VERSION "created by canmatrix"

NS_ :

BS_:

BU_: RadarFrontCenter DASy MPC3

BO_ 206 VFC_Object15A: 64 MPC3
 SG_ VFC_Obj15A_CRC : 0|16@1+ (1,0) [0|65535] ""  RadarFrontCenter,DASy
 SG_ VFC_Obj15A_AliveCtr : 16|8@1+ (1,0) [0|255] ""  RadarFrontCenter,DASy
 SG_ VFC_Obj15A_BlockCtr : 24|4@1+ (1,0) [0|15] ""  RadarFrontCenter,DASy
 SG_ VFC_Obj15A_ProtOrderIndex : 32|6@1+ (1,0) [0|63] ""  RadarFrontCenter,DASy
 SG_ VFC_Obj15A_Ax : 39|9@1+ (0.1,-16) [-16|16] "m/s^2"  RadarFrontCenter,DASy
 SG_ VFC_Obj15A_Vx : 48|12@1+ (0.1,-154) [-154|50] "m/s"  RadarFrontCenter,DASy
 SG_ VFC_Obj15A_Dx : 60|12@1+ (0.05,0) [0|204.7] "m"  RadarFrontCenter,DASy
 SG_ VFC_Obj15A_Dy : 72|14@1+ (0.01,-80) [-80|80] "m"  RadarFrontCenter,DASy
 SG_ VFC_Obj15A_Vy : 86|10@1+ (0.1,-50) [-50|50] "m/s"  RadarFrontCenter,DASy
 SG_ VFC_Obj15A_Ay : 96|8@1+ (0.1,-12) [-12|12] "m/s^2"  RadarFrontCenter,DASy
 SG_ VFC_Obj15A_DyStdDev : 104|10@1+ (0.02,0) [0|20] "m"  RadarFrontCenter,DASy
 SG_ VFC_Obj15A_DxStdDev : 118|10@1+ (0.05,0) [0|50] "m"  RadarFrontCenter,DASy
 SG_ VFC_Obj15A_VxStdDev : 128|10@1+ (0.1,0) [0|100] "m/s"  RadarFrontCenter,DASy
 SG_ VFC_Obj15A_ExistProb : 138|6@1+ (2,0) [0|100] "%"  RadarFrontCenter,DASy
 SG_ VFC_Obj15A_VyStdDev : 144|9@1+ (0.1,0) [0|50] "m/s"  RadarFrontCenter,DASy
 SG_ VFC_Obj15A_TypeProb : 154|6@1+ (2,0) [0|100] "%"  RadarFrontCenter,DASy
 SG_ VFC_Obj15A_AxStdDev : 160|8@1+ (0.1,0) [0|25] "m/s^2"  RadarFrontCenter,DASy
 SG_ VFC_Obj15A_AyStdDev : 168|8@1+ (0.1,0) [0|25] "m/s^2"  RadarFrontCenter,DASy
 SG_ VFC_Obj15A_PhiLeft : 176|13@1+ (0.00025,-1) [-1|1] ""  RadarFrontCenter,DASy
 SG_ VFC_Obj15A_ClassifiedView : 189|3@1+ (1,0) [0|7] ""  RadarFrontCenter,DASy
 SG_ VFC_Obj15A_Length : 192|9@1+ (0.05,0) [0|25.5] "m"  RadarFrontCenter,DASy
 SG_ VFC_Obj15A_WidthStdDev : 201|7@1+ (0.01,0) [0|1] "m"  RadarFrontCenter,DASy
 SG_ VFC_Obj15A_Height : 208|9@1+ (0.01,0) [0|5.11] "m"  RadarFrontCenter,DASy
 SG_ VFC_Obj15A_HeightStdDev : 217|7@1+ (0.01,0) [0|1] "m"  RadarFrontCenter,DASy
 SG_ VFC_Obj15A_PhiLeftStdDev : 224|8@1+ (0.0002,0) [0|0.05] ""  RadarFrontCenter,DASy
 SG_ VFC_Obj15A_HeadingStdDev : 232|6@1+ (0.01,0) [0|0.5] "rad"  RadarFrontCenter,DASy
 SG_ VFC_Obj15A_Measured : 238|2@1+ (1,0) [0|3] ""  RadarFrontCenter,DASy
 SG_ VFC_Obj15A_Heading : 240|9@1+ (0.01,-1.57) [-1.57|1.57] "rad"  RadarFrontCenter,DASy
 SG_ VFC_Obj15A_LengthStdDev : 249|7@1+ (0.05,0) [0|5] "m"  RadarFrontCenter,DASy
 SG_ VFC_Obj15A_PhiMid : 256|13@1+ (0.00025,-1) [-1|1] ""  RadarFrontCenter,DASy
 SG_ VFC_Obj15A_Width : 269|11@1+ (0.01,0) [0|12] "m"  RadarFrontCenter,DASy
 SG_ VFC_Obj15A_PhiMidStdDev : 280|8@1+ (0.0002,0) [0|0.05] ""  RadarFrontCenter,DASy
 SG_ VFC_Obj15A_PhiRight : 288|13@1+ (0.00025,-1) [-1|1] ""  RadarFrontCenter,DASy
 SG_ VFC_Obj15A_VisibleView : 301|3@1+ (1,0) [0|4] ""  RadarFrontCenter,DASy
 SG_ VFC_Obj15A_PhiRightStdDev : 304|8@1+ (0.0002,0) [0|0.05] ""  RadarFrontCenter,DASy
 SG_ VFC_Obj15A_PhiLeftVel : 312|13@1+ (0.001,-4) [-4|4] "1/s"  RadarFrontCenter,DASy
 SG_ VFC_Obj15A_PhiRightVel : 328|13@1+ (0.001,-4) [-4|4] "1/s"  RadarFrontCenter,DASy
 SG_ VFC_Obj15A_PhiRightVelStdDev : 344|8@1+ (0.001,0) [0|0.25] "1/s"  RadarFrontCenter,DASy
 SG_ VFC_Obj15A_PhiLeftVelStdDev : 352|8@1+ (0.001,0) [0|0.25] "1/s"  RadarFrontCenter,DASy
 SG_ VFC_Obj15A_PhiTop : 360|12@1+ (0.00025,-0.4) [-0.4|0.4] ""  RadarFrontCenter,DASy
 SG_ VFC_Obj15A_PhiBottom : 372|12@1+ (0.00025,-0.4) [-0.4|0.4] ""  RadarFrontCenter,DASy
 SG_ VFC_Obj15A_PhiTopStdDev : 384|8@1+ (0.0002,0) [0|0.05] ""  RadarFrontCenter,DASy
 SG_ VFC_Obj15A_HeadOrientation : 392|4@1+ (1,0) [0|10] ""  RadarFrontCenter,DASy
 SG_ VFC_Obj15A_Type : 396|4@1+ (1,0) [0|15] ""  RadarFrontCenter,DASy
 SG_ VFC_Obj15A_PhiBottomStdDev : 400|8@1+ (0.0002,0) [0|0.05] ""  RadarFrontCenter,DASy
 SG_ VFC_Obj15A_NormVx : 408|16@1+ (0.001,-40) [-40|25] "1/s"  RadarFrontCenter,DASy
 SG_ VFC_Obj15A_NormAx : 424|13@1+ (0.002,-10) [-10|6] "1/s^2"  RadarFrontCenter,DASy
 SG_ VFC_Obj15A_NormAxStdDev : 440|10@1+ (0.0025,0) [0|2.5] "1/s^2"  RadarFrontCenter,DASy
 SG_ VFC_Obj15A_ProbMovingLat : 450|6@1+ (2,0) [0|100] "%"  RadarFrontCenter,DASy
 SG_ VFC_Obj15A_ID : 456|8@1+ (1,0) [0|254] ""  RadarFrontCenter,DASy
 SG_ VFC_Obj15A_NormVxStdDev : 464|10@1+ (0.001,0) [0|1] "1/s"  RadarFrontCenter,DASy
 SG_ VFC_Obj15A_ProbMovingLong : 474|6@1+ (2,0) [0|100] "%"  RadarFrontCenter,DASy

BO_ 207 VFC_Object15B: 16 MPC3
 SG_ VFC_Obj15B_TTIPC_StdDev : 120|7@1+ (0.0625,0) [0|7.875] ""  RadarFrontCenter,DASy
 SG_ VFC_Obj15B_TTIPC : 104|11@1+ (0.008,-8) [-8|8] ""  RadarFrontCenter,DASy
 SG_ VFC_Obj15B_AngLongitude : 88|10@1+ (0.005,-2.5) [-2.5|2.5] "rad/s"  RadarFrontCenter,DASy
 SG_ VFC_Obj15B_CRC : 0|16@1+ (1,0) [0|65535] ""  RadarFrontCenter,DASy
 SG_ VFC_Obj15B_AliveCtr : 16|8@1+ (1,0) [0|255] ""  RadarFrontCenter,DASy
 SG_ VFC_Obj15B_BlockCtr : 24|4@1+ (1,0) [0|15] ""  RadarFrontCenter,DASy
 SG_ VFC_Obj15B_ScaleChange : 32|14@1+ (0.0001,0.5) [0.5|2.1] ""  RadarFrontCenter,DASy
 SG_ VFC_Obj15B_ScaleChngStdDev : 48|10@1+ (0.0001,0) [0|0.1] ""  RadarFrontCenter,DASy
 SG_ VFC_Obj15B_LineEdgeRightEgo : 58|1@1+ (1,0) [0|1] ""  RadarFrontCenter,DASy
 SG_ VFC_Obj15B_LineEdgeLeftEgo : 59|1@1+ (1,0) [0|1] ""  RadarFrontCenter,DASy
 SG_ VFC_Obj15B_CompletelyInImg : 60|1@1+ (1,0) [0|1] ""  RadarFrontCenter,DASy
 SG_ VFC_Obj15B_DirIndicator : 61|3@1+ (1,0) [0|7] ""  RadarFrontCenter,DASy
 SG_ VFC_Obj15B_LineEdgeAngle : 64|13@1+ (0.00025,-1) [-1|1] "rad"  RadarFrontCenter,DASy
 SG_ VFC_Obj15B_BrakeLight : 77|3@1+ (1,0) [0|7] ""  RadarFrontCenter,DASy
 SG_ VFC_Obj15B_MeasSource : 80|5@1+ (1,0) [0|31] ""  RadarFrontCenter,DASy
 SG_ VFC_Obj15B_Reliab : 98|6@1+ (1,0) [0|63] ""  RadarFrontCenter,DASy

BO_ 208 VFC_Object16A: 64 MPC3
 SG_ VFC_Obj16A_CRC : 0|16@1+ (1,0) [0|65535] ""  RadarFrontCenter,DASy
 SG_ VFC_Obj16A_AliveCtr : 16|8@1+ (1,0) [0|255] ""  RadarFrontCenter,DASy
 SG_ VFC_Obj16A_BlockCtr : 24|4@1+ (1,0) [0|15] ""  RadarFrontCenter,DASy
 SG_ VFC_Obj16A_ProtOrderIndex : 32|6@1+ (1,0) [0|63] ""  RadarFrontCenter,DASy
 SG_ VFC_Obj16A_Ax : 39|9@1+ (0.1,-16) [-16|16] "m/s^2"  RadarFrontCenter,DASy
 SG_ VFC_Obj16A_Vx : 48|12@1+ (0.1,-154) [-154|50] "m/s"  RadarFrontCenter,DASy
 SG_ VFC_Obj16A_Dx : 60|12@1+ (0.05,0) [0|204.7] "m"  RadarFrontCenter,DASy
 SG_ VFC_Obj16A_Dy : 72|14@1+ (0.01,-80) [-80|80] "m"  RadarFrontCenter,DASy
 SG_ VFC_Obj16A_Vy : 86|10@1+ (0.1,-50) [-50|50] "m/s"  RadarFrontCenter,DASy
 SG_ VFC_Obj16A_Ay : 96|8@1+ (0.1,-12) [-12|12] "m/s^2"  RadarFrontCenter,DASy
 SG_ VFC_Obj16A_DyStdDev : 104|10@1+ (0.02,0) [0|20] "m"  RadarFrontCenter,DASy
 SG_ VFC_Obj16A_DxStdDev : 118|10@1+ (0.05,0) [0|50] "m"  RadarFrontCenter,DASy
 SG_ VFC_Obj16A_VxStdDev : 128|10@1+ (0.1,0) [0|100] "m/s"  RadarFrontCenter,DASy
 SG_ VFC_Obj16A_ExistProb : 138|6@1+ (2,0) [0|100] "%"  RadarFrontCenter,DASy
 SG_ VFC_Obj16A_VyStdDev : 144|9@1+ (0.1,0) [0|50] "m/s"  RadarFrontCenter,DASy
 SG_ VFC_Obj16A_TypeProb : 154|6@1+ (2,0) [0|100] "%"  RadarFrontCenter,DASy
 SG_ VFC_Obj16A_AxStdDev : 160|8@1+ (0.1,0) [0|25] "m/s^2"  RadarFrontCenter,DASy
 SG_ VFC_Obj16A_AyStdDev : 168|8@1+ (0.1,0) [0|25] "m/s^2"  RadarFrontCenter,DASy
 SG_ VFC_Obj16A_PhiLeft : 176|13@1+ (0.00025,-1) [-1|1] ""  RadarFrontCenter,DASy
 SG_ VFC_Obj16A_ClassifiedView : 189|3@1+ (1,0) [0|7] ""  RadarFrontCenter,DASy
 SG_ VFC_Obj16A_Length : 192|9@1+ (0.05,0) [0|25.5] "m"  RadarFrontCenter,DASy
 SG_ VFC_Obj16A_WidthStdDev : 201|7@1+ (0.01,0) [0|1] "m"  RadarFrontCenter,DASy
 SG_ VFC_Obj16A_Height : 208|9@1+ (0.01,0) [0|5.11] "m"  RadarFrontCenter,DASy
 SG_ VFC_Obj16A_HeightStdDev : 217|7@1+ (0.01,0) [0|1] "m"  RadarFrontCenter,DASy
 SG_ VFC_Obj16A_PhiLeftStdDev : 224|8@1+ (0.0002,0) [0|0.05] ""  RadarFrontCenter,DASy
 SG_ VFC_Obj16A_HeadingStdDev : 232|6@1+ (0.01,0) [0|0.5] "rad"  RadarFrontCenter,DASy
 SG_ VFC_Obj16A_Measured : 238|2@1+ (1,0) [0|3] ""  RadarFrontCenter,DASy
 SG_ VFC_Obj16A_Heading : 240|9@1+ (0.01,-1.57) [-1.57|1.57] "rad"  RadarFrontCenter,DASy
 SG_ VFC_Obj16A_LengthStdDev : 249|7@1+ (0.05,0) [0|5] "m"  RadarFrontCenter,DASy
 SG_ VFC_Obj16A_PhiMid : 256|13@1+ (0.00025,-1) [-1|1] ""  RadarFrontCenter,DASy
 SG_ VFC_Obj16A_Width : 269|11@1+ (0.01,0) [0|12] "m"  RadarFrontCenter,DASy
 SG_ VFC_Obj16A_PhiMidStdDev : 280|8@1+ (0.0002,0) [0|0.05] ""  RadarFrontCenter,DASy
 SG_ VFC_Obj16A_PhiRight : 288|13@1+ (0.00025,-1) [-1|1] ""  RadarFrontCenter,DASy
 SG_ VFC_Obj16A_VisibleView : 301|3@1+ (1,0) [0|4] ""  RadarFrontCenter,DASy
 SG_ VFC_Obj16A_PhiRightStdDev : 304|8@1+ (0.0002,0) [0|0.05] ""  RadarFrontCenter,DASy
 SG_ VFC_Obj16A_PhiLeftVel : 312|13@1+ (0.001,-4) [-4|4] "1/s"  RadarFrontCenter,DASy
 SG_ VFC_Obj16A_PhiRightVel : 328|13@1+ (0.001,-4) [-4|4] "1/s"  RadarFrontCenter,DASy
 SG_ VFC_Obj16A_PhiRightVelStdDev : 344|8@1+ (0.001,0) [0|0.25] "1/s"  RadarFrontCenter,DASy
 SG_ VFC_Obj16A_PhiLeftVelStdDev : 352|8@1+ (0.001,0) [0|0.25] "1/s"  RadarFrontCenter,DASy
 SG_ VFC_Obj16A_PhiTop : 360|12@1+ (0.00025,-0.4) [-0.4|0.4] ""  RadarFrontCenter,DASy
 SG_ VFC_Obj16A_PhiBottom : 372|12@1+ (0.00025,-0.4) [-0.4|0.4] ""  RadarFrontCenter,DASy
 SG_ VFC_Obj16A_PhiTopStdDev : 384|8@1+ (0.0002,0) [0|0.05] ""  RadarFrontCenter,DASy
 SG_ VFC_Obj16A_HeadOrientation : 392|4@1+ (1,0) [0|10] ""  RadarFrontCenter,DASy
 SG_ VFC_Obj16A_Type : 396|4@1+ (1,0) [0|15] ""  RadarFrontCenter,DASy
 SG_ VFC_Obj16A_PhiBottomStdDev : 400|8@1+ (0.0002,0) [0|0.05] ""  RadarFrontCenter,DASy
 SG_ VFC_Obj16A_NormVx : 408|16@1+ (0.001,-40) [-40|25] "1/s"  RadarFrontCenter,DASy
 SG_ VFC_Obj16A_NormAx : 424|13@1+ (0.002,-10) [-10|6] "1/s^2"  RadarFrontCenter,DASy
 SG_ VFC_Obj16A_NormAxStdDev : 440|10@1+ (0.0025,0) [0|2.5] "1/s^2"  RadarFrontCenter,DASy
 SG_ VFC_Obj16A_ProbMovingLat : 450|6@1+ (2,0) [0|100] "%"  RadarFrontCenter,DASy
 SG_ VFC_Obj16A_ID : 456|8@1+ (1,0) [0|254] ""  RadarFrontCenter,DASy
 SG_ VFC_Obj16A_NormVxStdDev : 464|10@1+ (0.001,0) [0|1] "1/s"  RadarFrontCenter,DASy
 SG_ VFC_Obj16A_ProbMovingLong : 474|6@1+ (2,0) [0|100] "%"  RadarFrontCenter,DASy

BO_ 209 VFC_Object16B: 16 MPC3
 SG_ VFC_Obj16B_TTIPC_StdDev : 120|7@1+ (0.0625,0) [0|7.875] ""  RadarFrontCenter,DASy
 SG_ VFC_Obj16B_TTIPC : 104|11@1+ (0.008,-8) [-8|8] ""  RadarFrontCenter,DASy
 SG_ VFC_Obj16B_AngLongitude : 88|10@1+ (0.005,-2.5) [-2.5|2.5] "rad/s"  RadarFrontCenter,DASy
 SG_ VFC_Obj16B_CRC : 0|16@1+ (1,0) [0|65535] ""  RadarFrontCenter,DASy
 SG_ VFC_Obj16B_AliveCtr : 16|8@1+ (1,0) [0|255] ""  RadarFrontCenter,DASy
 SG_ VFC_Obj16B_BlockCtr : 24|4@1+ (1,0) [0|15] ""  RadarFrontCenter,DASy
 SG_ VFC_Obj16B_ScaleChange : 32|14@1+ (0.0001,0.5) [0.5|2.1] ""  RadarFrontCenter,DASy
 SG_ VFC_Obj16B_ScaleChngStdDev : 48|10@1+ (0.0001,0) [0|0.1] ""  RadarFrontCenter,DASy
 SG_ VFC_Obj16B_LineEdgeRightEgo : 58|1@1+ (1,0) [0|1] ""  RadarFrontCenter,DASy
 SG_ VFC_Obj16B_LineEdgeLeftEgo : 59|1@1+ (1,0) [0|1] ""  RadarFrontCenter,DASy
 SG_ VFC_Obj16B_CompletelyInImg : 60|1@1+ (1,0) [0|1] ""  RadarFrontCenter,DASy
 SG_ VFC_Obj16B_DirIndicator : 61|3@1+ (1,0) [0|7] ""  RadarFrontCenter,DASy
 SG_ VFC_Obj16B_LineEdgeAngle : 64|13@1+ (0.00025,-1) [-1|1] "rad"  RadarFrontCenter,DASy
 SG_ VFC_Obj16B_BrakeLight : 77|3@1+ (1,0) [0|7] ""  RadarFrontCenter,DASy
 SG_ VFC_Obj16B_MeasSource : 80|5@1+ (1,0) [0|31] ""  RadarFrontCenter,DASy
 SG_ VFC_Obj16B_Reliab : 98|6@1+ (1,0) [0|63] ""  RadarFrontCenter,DASy

BO_ 210 VFC_Object17A: 64 MPC3
 SG_ VFC_Obj17A_CRC : 0|16@1+ (1,0) [0|65535] ""  RadarFrontCenter,DASy
 SG_ VFC_Obj17A_AliveCtr : 16|8@1+ (1,0) [0|255] ""  RadarFrontCenter,DASy
 SG_ VFC_Obj17A_BlockCtr : 24|4@1+ (1,0) [0|15] ""  RadarFrontCenter,DASy
 SG_ VFC_Obj17A_ProtOrderIndex : 32|6@1+ (1,0) [0|63] ""  RadarFrontCenter,DASy
 SG_ VFC_Obj17A_Ax : 39|9@1+ (0.1,-16) [-16|16] "m/s^2"  RadarFrontCenter,DASy
 SG_ VFC_Obj17A_Vx : 48|12@1+ (0.1,-154) [-154|50] "m/s"  RadarFrontCenter,DASy
 SG_ VFC_Obj17A_Dx : 60|12@1+ (0.05,0) [0|204.7] "m"  RadarFrontCenter,DASy
 SG_ VFC_Obj17A_Dy : 72|14@1+ (0.01,-80) [-80|80] "m"  RadarFrontCenter,DASy
 SG_ VFC_Obj17A_Vy : 86|10@1+ (0.1,-50) [-50|50] "m/s"  RadarFrontCenter,DASy
 SG_ VFC_Obj17A_Ay : 96|8@1+ (0.1,-12) [-12|12] "m/s^2"  RadarFrontCenter,DASy
 SG_ VFC_Obj17A_DyStdDev : 104|10@1+ (0.02,0) [0|20] "m"  RadarFrontCenter,DASy
 SG_ VFC_Obj17A_DxStdDev : 118|10@1+ (0.05,0) [0|50] "m"  RadarFrontCenter,DASy
 SG_ VFC_Obj17A_VxStdDev : 128|10@1+ (0.1,0) [0|100] "m/s"  RadarFrontCenter,DASy
 SG_ VFC_Obj17A_ExistProb : 138|6@1+ (2,0) [0|100] "%"  RadarFrontCenter,DASy
 SG_ VFC_Obj17A_VyStdDev : 144|9@1+ (0.1,0) [0|50] "m/s"  RadarFrontCenter,DASy
 SG_ VFC_Obj17A_TypeProb : 154|6@1+ (2,0) [0|100] "%"  RadarFrontCenter,DASy
 SG_ VFC_Obj17A_AxStdDev : 160|8@1+ (0.1,0) [0|25] "m/s^2"  RadarFrontCenter,DASy
 SG_ VFC_Obj17A_AyStdDev : 168|8@1+ (0.1,0) [0|25] "m/s^2"  RadarFrontCenter,DASy
 SG_ VFC_Obj17A_PhiLeft : 176|13@1+ (0.00025,-1) [-1|1] ""  RadarFrontCenter,DASy
 SG_ VFC_Obj17A_ClassifiedView : 189|3@1+ (1,0) [0|7] ""  RadarFrontCenter,DASy
 SG_ VFC_Obj17A_Length : 192|9@1+ (0.05,0) [0|25.5] "m"  RadarFrontCenter,DASy
 SG_ VFC_Obj17A_WidthStdDev : 201|7@1+ (0.01,0) [0|1] "m"  RadarFrontCenter,DASy
 SG_ VFC_Obj17A_Height : 208|9@1+ (0.01,0) [0|5.11] "m"  RadarFrontCenter,DASy
 SG_ VFC_Obj17A_HeightStdDev : 217|7@1+ (0.01,0) [0|1] "m"  RadarFrontCenter,DASy
 SG_ VFC_Obj17A_PhiLeftStdDev : 224|8@1+ (0.0002,0) [0|0.05] ""  RadarFrontCenter,DASy
 SG_ VFC_Obj17A_HeadingStdDev : 232|6@1+ (0.01,0) [0|0.5] "rad"  RadarFrontCenter,DASy
 SG_ VFC_Obj17A_Measured : 238|2@1+ (1,0) [0|3] ""  RadarFrontCenter,DASy
 SG_ VFC_Obj17A_Heading : 240|9@1+ (0.01,-1.57) [-1.57|1.57] "rad"  RadarFrontCenter,DASy
 SG_ VFC_Obj17A_LengthStdDev : 249|7@1+ (0.05,0) [0|5] "m"  RadarFrontCenter,DASy
 SG_ VFC_Obj17A_PhiMid : 256|13@1+ (0.00025,-1) [-1|1] ""  RadarFrontCenter,DASy
 SG_ VFC_Obj17A_Width : 269|11@1+ (0.01,0) [0|12] "m"  RadarFrontCenter,DASy
 SG_ VFC_Obj17A_PhiMidStdDev : 280|8@1+ (0.0002,0) [0|0.05] ""  RadarFrontCenter,DASy
 SG_ VFC_Obj17A_PhiRight : 288|13@1+ (0.00025,-1) [-1|1] ""  RadarFrontCenter,DASy
 SG_ VFC_Obj17A_VisibleView : 301|3@1+ (1,0) [0|4] ""  RadarFrontCenter,DASy
 SG_ VFC_Obj17A_PhiRightStdDev : 304|8@1+ (0.0002,0) [0|0.05] ""  RadarFrontCenter,DASy
 SG_ VFC_Obj17A_PhiLeftVel : 312|13@1+ (0.001,-4) [-4|4] "1/s"  RadarFrontCenter,DASy
 SG_ VFC_Obj17A_PhiRightVel : 328|13@1+ (0.001,-4) [-4|4] "1/s"  RadarFrontCenter,DASy
 SG_ VFC_Obj17A_PhiRightVelStdDev : 344|8@1+ (0.001,0) [0|0.25] "1/s"  RadarFrontCenter,DASy
 SG_ VFC_Obj17A_PhiLeftVelStdDev : 352|8@1+ (0.001,0) [0|0.25] "1/s"  RadarFrontCenter,DASy
 SG_ VFC_Obj17A_PhiTop : 360|12@1+ (0.00025,-0.4) [-0.4|0.4] ""  RadarFrontCenter,DASy
 SG_ VFC_Obj17A_PhiBottom : 372|12@1+ (0.00025,-0.4) [-0.4|0.4] ""  RadarFrontCenter,DASy
 SG_ VFC_Obj17A_PhiTopStdDev : 384|8@1+ (0.0002,0) [0|0.05] ""  RadarFrontCenter,DASy
 SG_ VFC_Obj17A_HeadOrientation : 392|4@1+ (1,0) [0|10] ""  RadarFrontCenter,DASy
 SG_ VFC_Obj17A_Type : 396|4@1+ (1,0) [0|15] ""  RadarFrontCenter,DASy
 SG_ VFC_Obj17A_PhiBottomStdDev : 400|8@1+ (0.0002,0) [0|0.05] ""  RadarFrontCenter,DASy
 SG_ VFC_Obj17A_NormVx : 408|16@1+ (0.001,-40) [-40|25] "1/s"  RadarFrontCenter,DASy
 SG_ VFC_Obj17A_NormAx : 424|13@1+ (0.002,-10) [-10|6] "1/s^2"  RadarFrontCenter,DASy
 SG_ VFC_Obj17A_NormAxStdDev : 440|10@1+ (0.0025,0) [0|2.5] "1/s^2"  RadarFrontCenter,DASy
 SG_ VFC_Obj17A_ProbMovingLat : 450|6@1+ (2,0) [0|100] "%"  RadarFrontCenter,DASy
 SG_ VFC_Obj17A_ID : 456|8@1+ (1,0) [0|254] ""  RadarFrontCenter,DASy
 SG_ VFC_Obj17A_NormVxStdDev : 464|10@1+ (0.001,0) [0|1] "1/s"  RadarFrontCenter,DASy
 SG_ VFC_Obj17A_ProbMovingLong : 474|6@1+ (2,0) [0|100] "%"  RadarFrontCenter,DASy

BO_ 211 VFC_Object17B: 16 MPC3
 SG_ VFC_Obj17B_TTIPC_StdDev : 120|7@1+ (0.0625,0) [0|7.875] ""  RadarFrontCenter,DASy
 SG_ VFC_Obj17B_TTIPC : 104|11@1+ (0.008,-8) [-8|8] ""  RadarFrontCenter,DASy
 SG_ VFC_Obj17B_AngLongitude : 88|10@1+ (0.005,-2.5) [-2.5|2.5] "rad/s"  RadarFrontCenter,DASy
 SG_ VFC_Obj17B_CRC : 0|16@1+ (1,0) [0|65535] ""  RadarFrontCenter,DASy
 SG_ VFC_Obj17B_AliveCtr : 16|8@1+ (1,0) [0|255] ""  RadarFrontCenter,DASy
 SG_ VFC_Obj17B_BlockCtr : 24|4@1+ (1,0) [0|15] ""  RadarFrontCenter,DASy
 SG_ VFC_Obj17B_ScaleChange : 32|14@1+ (0.0001,0.5) [0.5|2.1] ""  RadarFrontCenter,DASy
 SG_ VFC_Obj17B_ScaleChngStdDev : 48|10@1+ (0.0001,0) [0|0.1] ""  RadarFrontCenter,DASy
 SG_ VFC_Obj17B_LineEdgeRightEgo : 58|1@1+ (1,0) [0|1] ""  RadarFrontCenter,DASy
 SG_ VFC_Obj17B_LineEdgeLeftEgo : 59|1@1+ (1,0) [0|1] ""  RadarFrontCenter,DASy
 SG_ VFC_Obj17B_CompletelyInImg : 60|1@1+ (1,0) [0|1] ""  RadarFrontCenter,DASy
 SG_ VFC_Obj17B_DirIndicator : 61|3@1+ (1,0) [0|7] ""  RadarFrontCenter,DASy
 SG_ VFC_Obj17B_LineEdgeAngle : 64|13@1+ (0.00025,-1) [-1|1] "rad"  RadarFrontCenter,DASy
 SG_ VFC_Obj17B_BrakeLight : 77|3@1+ (1,0) [0|7] ""  RadarFrontCenter,DASy
 SG_ VFC_Obj17B_MeasSource : 80|5@1+ (1,0) [0|31] ""  RadarFrontCenter,DASy
 SG_ VFC_Obj17B_Reliab : 98|6@1+ (1,0) [0|63] ""  RadarFrontCenter,DASy

BO_ 212 VFC_Object18A: 64 MPC3
 SG_ VFC_Obj18A_CRC : 0|16@1+ (1,0) [0|65535] ""  RadarFrontCenter,DASy
 SG_ VFC_Obj18A_AliveCtr : 16|8@1+ (1,0) [0|255] ""  RadarFrontCenter,DASy
 SG_ VFC_Obj18A_BlockCtr : 24|4@1+ (1,0) [0|15] ""  RadarFrontCenter,DASy
 SG_ VFC_Obj18A_ProtOrderIndex : 32|6@1+ (1,0) [0|63] ""  RadarFrontCenter,DASy
 SG_ VFC_Obj18A_Ax : 39|9@1+ (0.1,-16) [-16|16] "m/s^2"  RadarFrontCenter,DASy
 SG_ VFC_Obj18A_Vx : 48|12@1+ (0.1,-154) [-154|50] "m/s"  RadarFrontCenter,DASy
 SG_ VFC_Obj18A_Dx : 60|12@1+ (0.05,0) [0|204.7] "m"  RadarFrontCenter,DASy
 SG_ VFC_Obj18A_Dy : 72|14@1+ (0.01,-80) [-80|80] "m"  RadarFrontCenter,DASy
 SG_ VFC_Obj18A_Vy : 86|10@1+ (0.1,-50) [-50|50] "m/s"  RadarFrontCenter,DASy
 SG_ VFC_Obj18A_Ay : 96|8@1+ (0.1,-12) [-12|12] "m/s^2"  RadarFrontCenter,DASy
 SG_ VFC_Obj18A_DyStdDev : 104|10@1+ (0.02,0) [0|20] "m"  RadarFrontCenter,DASy
 SG_ VFC_Obj18A_DxStdDev : 118|10@1+ (0.05,0) [0|50] "m"  RadarFrontCenter,DASy
 SG_ VFC_Obj18A_VxStdDev : 128|10@1+ (0.1,0) [0|100] "m/s"  RadarFrontCenter,DASy
 SG_ VFC_Obj18A_ExistProb : 138|6@1+ (2,0) [0|100] "%"  RadarFrontCenter,DASy
 SG_ VFC_Obj18A_VyStdDev : 144|9@1+ (0.1,0) [0|50] "m/s"  RadarFrontCenter,DASy
 SG_ VFC_Obj18A_TypeProb : 154|6@1+ (2,0) [0|100] "%"  RadarFrontCenter,DASy
 SG_ VFC_Obj18A_AxStdDev : 160|8@1+ (0.1,0) [0|25] "m/s^2"  RadarFrontCenter,DASy
 SG_ VFC_Obj18A_AyStdDev : 168|8@1+ (0.1,0) [0|25] "m/s^2"  RadarFrontCenter,DASy
 SG_ VFC_Obj18A_PhiLeft : 176|13@1+ (0.00025,-1) [-1|1] ""  RadarFrontCenter,DASy
 SG_ VFC_Obj18A_ClassifiedView : 189|3@1+ (1,0) [0|7] ""  RadarFrontCenter,DASy
 SG_ VFC_Obj18A_Length : 192|9@1+ (0.05,0) [0|25.5] "m"  RadarFrontCenter,DASy
 SG_ VFC_Obj18A_WidthStdDev : 201|7@1+ (0.01,0) [0|1] "m"  RadarFrontCenter,DASy
 SG_ VFC_Obj18A_Height : 208|9@1+ (0.01,0) [0|5.11] "m"  RadarFrontCenter,DASy
 SG_ VFC_Obj18A_HeightStdDev : 217|7@1+ (0.01,0) [0|1] "m"  RadarFrontCenter,DASy
 SG_ VFC_Obj18A_PhiLeftStdDev : 224|8@1+ (0.0002,0) [0|0.05] ""  RadarFrontCenter,DASy
 SG_ VFC_Obj18A_HeadingStdDev : 232|6@1+ (0.01,0) [0|0.5] "rad"  RadarFrontCenter,DASy
 SG_ VFC_Obj18A_Measured : 238|2@1+ (1,0) [0|3] ""  RadarFrontCenter,DASy
 SG_ VFC_Obj18A_Heading : 240|9@1+ (0.01,-1.57) [-1.57|1.57] "rad"  RadarFrontCenter,DASy
 SG_ VFC_Obj18A_LengthStdDev : 249|7@1+ (0.05,0) [0|5] "m"  RadarFrontCenter,DASy
 SG_ VFC_Obj18A_PhiMid : 256|13@1+ (0.00025,-1) [-1|1] ""  RadarFrontCenter,DASy
 SG_ VFC_Obj18A_Width : 269|11@1+ (0.01,0) [0|12] "m"  RadarFrontCenter,DASy
 SG_ VFC_Obj18A_PhiMidStdDev : 280|8@1+ (0.0002,0) [0|0.05] ""  RadarFrontCenter,DASy
 SG_ VFC_Obj18A_PhiRight : 288|13@1+ (0.00025,-1) [-1|1] ""  RadarFrontCenter,DASy
 SG_ VFC_Obj18A_VisibleView : 301|3@1+ (1,0) [0|4] ""  RadarFrontCenter,DASy
 SG_ VFC_Obj18A_PhiRightStdDev : 304|8@1+ (0.0002,0) [0|0.05] ""  RadarFrontCenter,DASy
 SG_ VFC_Obj18A_PhiLeftVel : 312|13@1+ (0.001,-4) [-4|4] "1/s"  RadarFrontCenter,DASy
 SG_ VFC_Obj18A_PhiRightVel : 328|13@1+ (0.001,-4) [-4|4] "1/s"  RadarFrontCenter,DASy
 SG_ VFC_Obj18A_PhiRightVelStdDev : 344|8@1+ (0.001,0) [0|0.25] "1/s"  RadarFrontCenter,DASy
 SG_ VFC_Obj18A_PhiLeftVelStdDev : 352|8@1+ (0.001,0) [0|0.25] "1/s"  RadarFrontCenter,DASy
 SG_ VFC_Obj18A_PhiTop : 360|12@1+ (0.00025,-0.4) [-0.4|0.4] ""  RadarFrontCenter,DASy
 SG_ VFC_Obj18A_PhiBottom : 372|12@1+ (0.00025,-0.4) [-0.4|0.4] ""  RadarFrontCenter,DASy
 SG_ VFC_Obj18A_PhiTopStdDev : 384|8@1+ (0.0002,0) [0|0.05] ""  RadarFrontCenter,DASy
 SG_ VFC_Obj18A_HeadOrientation : 392|4@1+ (1,0) [0|10] ""  RadarFrontCenter,DASy
 SG_ VFC_Obj18A_Type : 396|4@1+ (1,0) [0|15] ""  RadarFrontCenter,DASy
 SG_ VFC_Obj18A_PhiBottomStdDev : 400|8@1+ (0.0002,0) [0|0.05] ""  RadarFrontCenter,DASy
 SG_ VFC_Obj18A_NormVx : 408|16@1+ (0.001,-40) [-40|25] "1/s"  RadarFrontCenter,DASy
 SG_ VFC_Obj18A_NormAx : 424|13@1+ (0.002,-10) [-10|6] "1/s^2"  RadarFrontCenter,DASy
 SG_ VFC_Obj18A_NormAxStdDev : 440|10@1+ (0.0025,0) [0|2.5] "1/s^2"  RadarFrontCenter,DASy
 SG_ VFC_Obj18A_ProbMovingLat : 450|6@1+ (2,0) [0|100] "%"  RadarFrontCenter,DASy
 SG_ VFC_Obj18A_ID : 456|8@1+ (1,0) [0|254] ""  RadarFrontCenter,DASy
 SG_ VFC_Obj18A_NormVxStdDev : 464|10@1+ (0.001,0) [0|1] "1/s"  RadarFrontCenter,DASy
 SG_ VFC_Obj18A_ProbMovingLong : 474|6@1+ (2,0) [0|100] "%"  RadarFrontCenter,DASy

BO_ 213 VFC_Object18B: 16 MPC3
 SG_ VFC_Obj18B_TTIPC_StdDev : 120|7@1+ (0.0625,0) [0|7.875] ""  RadarFrontCenter,DASy
 SG_ VFC_Obj18B_TTIPC : 104|11@1+ (0.008,-8) [-8|8] ""  RadarFrontCenter,DASy
 SG_ VFC_Obj18B_AngLongitude : 88|10@1+ (0.005,-2.5) [-2.5|2.5] "rad/s"  RadarFrontCenter,DASy
 SG_ VFC_Obj18B_CRC : 0|16@1+ (1,0) [0|65535] ""  RadarFrontCenter,DASy
 SG_ VFC_Obj18B_AliveCtr : 16|8@1+ (1,0) [0|255] ""  RadarFrontCenter,DASy
 SG_ VFC_Obj18B_BlockCtr : 24|4@1+ (1,0) [0|15] ""  RadarFrontCenter,DASy
 SG_ VFC_Obj18B_ScaleChange : 32|14@1+ (0.0001,0.5) [0.5|2.1] ""  RadarFrontCenter,DASy
 SG_ VFC_Obj18B_ScaleChngStdDev : 48|10@1+ (0.0001,0) [0|0.1] ""  RadarFrontCenter,DASy
 SG_ VFC_Obj18B_LineEdgeRightEgo : 58|1@1+ (1,0) [0|1] ""  RadarFrontCenter,DASy
 SG_ VFC_Obj18B_LineEdgeLeftEgo : 59|1@1+ (1,0) [0|1] ""  RadarFrontCenter,DASy
 SG_ VFC_Obj18B_CompletelyInImg : 60|1@1+ (1,0) [0|1] ""  RadarFrontCenter,DASy
 SG_ VFC_Obj18B_DirIndicator : 61|3@1+ (1,0) [0|7] ""  RadarFrontCenter,DASy
 SG_ VFC_Obj18B_LineEdgeAngle : 64|13@1+ (0.00025,-1) [-1|1] "rad"  RadarFrontCenter,DASy
 SG_ VFC_Obj18B_BrakeLight : 77|3@1+ (1,0) [0|7] ""  RadarFrontCenter,DASy
 SG_ VFC_Obj18B_MeasSource : 80|5@1+ (1,0) [0|31] ""  RadarFrontCenter,DASy
 SG_ VFC_Obj18B_Reliab : 98|6@1+ (1,0) [0|63] ""  RadarFrontCenter,DASy

BO_ 214 VFC_Object19A: 64 MPC3
 SG_ VFC_Obj19A_CRC : 0|16@1+ (1,0) [0|65535] ""  RadarFrontCenter,DASy
 SG_ VFC_Obj19A_AliveCtr : 16|8@1+ (1,0) [0|255] ""  RadarFrontCenter,DASy
 SG_ VFC_Obj19A_BlockCtr : 24|4@1+ (1,0) [0|15] ""  RadarFrontCenter,DASy
 SG_ VFC_Obj19A_ProtOrderIndex : 32|6@1+ (1,0) [0|63] ""  RadarFrontCenter,DASy
 SG_ VFC_Obj19A_Ax : 39|9@1+ (0.1,-16) [-16|16] "m/s^2"  RadarFrontCenter,DASy
 SG_ VFC_Obj19A_Vx : 48|12@1+ (0.1,-154) [-154|50] "m/s"  RadarFrontCenter,DASy
 SG_ VFC_Obj19A_Dx : 60|12@1+ (0.05,0) [0|204.7] "m"  RadarFrontCenter,DASy
 SG_ VFC_Obj19A_Dy : 72|14@1+ (0.01,-80) [-80|80] "m"  RadarFrontCenter,DASy
 SG_ VFC_Obj19A_Vy : 86|10@1+ (0.1,-50) [-50|50] "m/s"  RadarFrontCenter,DASy
 SG_ VFC_Obj19A_Ay : 96|8@1+ (0.1,-12) [-12|12] "m/s^2"  RadarFrontCenter,DASy
 SG_ VFC_Obj19A_DyStdDev : 104|10@1+ (0.02,0) [0|20] "m"  RadarFrontCenter,DASy
 SG_ VFC_Obj19A_DxStdDev : 118|10@1+ (0.05,0) [0|50] "m"  RadarFrontCenter,DASy
 SG_ VFC_Obj19A_VxStdDev : 128|10@1+ (0.1,0) [0|100] "m/s"  RadarFrontCenter,DASy
 SG_ VFC_Obj19A_ExistProb : 138|6@1+ (2,0) [0|100] "%"  RadarFrontCenter,DASy
 SG_ VFC_Obj19A_VyStdDev : 144|9@1+ (0.1,0) [0|50] "m/s"  RadarFrontCenter,DASy
 SG_ VFC_Obj19A_TypeProb : 154|6@1+ (2,0) [0|100] "%"  RadarFrontCenter,DASy
 SG_ VFC_Obj19A_AxStdDev : 160|8@1+ (0.1,0) [0|25] "m/s^2"  RadarFrontCenter,DASy
 SG_ VFC_Obj19A_AyStdDev : 168|8@1+ (0.1,0) [0|25] "m/s^2"  RadarFrontCenter,DASy
 SG_ VFC_Obj19A_PhiLeft : 176|13@1+ (0.00025,-1) [-1|1] ""  RadarFrontCenter,DASy
 SG_ VFC_Obj19A_ClassifiedView : 189|3@1+ (1,0) [0|7] ""  RadarFrontCenter,DASy
 SG_ VFC_Obj19A_Length : 192|9@1+ (0.05,0) [0|25.5] "m"  RadarFrontCenter,DASy
 SG_ VFC_Obj19A_WidthStdDev : 201|7@1+ (0.01,0) [0|1] "m"  RadarFrontCenter,DASy
 SG_ VFC_Obj19A_Height : 208|9@1+ (0.01,0) [0|5.11] "m"  RadarFrontCenter,DASy
 SG_ VFC_Obj19A_HeightStdDev : 217|7@1+ (0.01,0) [0|1] "m"  RadarFrontCenter,DASy
 SG_ VFC_Obj19A_PhiLeftStdDev : 224|8@1+ (0.0002,0) [0|0.05] ""  RadarFrontCenter,DASy
 SG_ VFC_Obj19A_HeadingStdDev : 232|6@1+ (0.01,0) [0|0.5] "rad"  RadarFrontCenter,DASy
 SG_ VFC_Obj19A_Measured : 238|2@1+ (1,0) [0|3] ""  RadarFrontCenter,DASy
 SG_ VFC_Obj19A_Heading : 240|9@1+ (0.01,-1.57) [-1.57|1.57] "rad"  RadarFrontCenter,DASy
 SG_ VFC_Obj19A_LengthStdDev : 249|7@1+ (0.05,0) [0|5] "m"  RadarFrontCenter,DASy
 SG_ VFC_Obj19A_PhiMid : 256|13@1+ (0.00025,-1) [-1|1] ""  RadarFrontCenter,DASy
 SG_ VFC_Obj19A_Width : 269|11@1+ (0.01,0) [0|12] "m"  RadarFrontCenter,DASy
 SG_ VFC_Obj19A_PhiMidStdDev : 280|8@1+ (0.0002,0) [0|0.05] ""  RadarFrontCenter,DASy
 SG_ VFC_Obj19A_PhiRight : 288|13@1+ (0.00025,-1) [-1|1] ""  RadarFrontCenter,DASy
 SG_ VFC_Obj19A_VisibleView : 301|3@1+ (1,0) [0|4] ""  RadarFrontCenter,DASy
 SG_ VFC_Obj19A_PhiRightStdDev : 304|8@1+ (0.0002,0) [0|0.05] ""  RadarFrontCenter,DASy
 SG_ VFC_Obj19A_PhiLeftVel : 312|13@1+ (0.001,-4) [-4|4] "1/s"  RadarFrontCenter,DASy
 SG_ VFC_Obj19A_PhiRightVel : 328|13@1+ (0.001,-4) [-4|4] "1/s"  RadarFrontCenter,DASy
 SG_ VFC_Obj19A_PhiRightVelStdDev : 344|8@1+ (0.001,0) [0|0.25] "1/s"  RadarFrontCenter,DASy
 SG_ VFC_Obj19A_PhiLeftVelStdDev : 352|8@1+ (0.001,0) [0|0.25] "1/s"  RadarFrontCenter,DASy
 SG_ VFC_Obj19A_PhiTop : 360|12@1+ (0.00025,-0.4) [-0.4|0.4] ""  RadarFrontCenter,DASy
 SG_ VFC_Obj19A_PhiBottom : 372|12@1+ (0.00025,-0.4) [-0.4|0.4] ""  RadarFrontCenter,DASy
 SG_ VFC_Obj19A_PhiTopStdDev : 384|8@1+ (0.0002,0) [0|0.05] ""  RadarFrontCenter,DASy
 SG_ VFC_Obj19A_HeadOrientation : 392|4@1+ (1,0) [0|10] ""  RadarFrontCenter,DASy
 SG_ VFC_Obj19A_Type : 396|4@1+ (1,0) [0|15] ""  RadarFrontCenter,DASy
 SG_ VFC_Obj19A_PhiBottomStdDev : 400|8@1+ (0.0002,0) [0|0.05] ""  RadarFrontCenter,DASy
 SG_ VFC_Obj19A_NormVx : 408|16@1+ (0.001,-40) [-40|25] "1/s"  RadarFrontCenter,DASy
 SG_ VFC_Obj19A_NormAx : 424|13@1+ (0.002,-10) [-10|6] "1/s^2"  RadarFrontCenter,DASy
 SG_ VFC_Obj19A_NormAxStdDev : 440|10@1+ (0.0025,0) [0|2.5] "1/s^2"  RadarFrontCenter,DASy
 SG_ VFC_Obj19A_ProbMovingLat : 450|6@1+ (2,0) [0|100] "%"  RadarFrontCenter,DASy
 SG_ VFC_Obj19A_ID : 456|8@1+ (1,0) [0|254] ""  RadarFrontCenter,DASy
 SG_ VFC_Obj19A_NormVxStdDev : 464|10@1+ (0.001,0) [0|1] "1/s"  RadarFrontCenter,DASy
 SG_ VFC_Obj19A_ProbMovingLong : 474|6@1+ (2,0) [0|100] "%"  RadarFrontCenter,DASy

BO_ 215 VFC_Object19B: 16 MPC3
 SG_ VFC_Obj19B_TTIPC_StdDev : 120|7@1+ (0.0625,0) [0|7.875] ""  RadarFrontCenter,DASy
 SG_ VFC_Obj19B_TTIPC : 104|11@1+ (0.008,-8) [-8|8] ""  RadarFrontCenter,DASy
 SG_ VFC_Obj19B_AngLongitude : 88|10@1+ (0.005,-2.5) [-2.5|2.5] "rad/s"  RadarFrontCenter,DASy
 SG_ VFC_Obj19B_CRC : 0|16@1+ (1,0) [0|65535] ""  RadarFrontCenter,DASy
 SG_ VFC_Obj19B_AliveCtr : 16|8@1+ (1,0) [0|255] ""  RadarFrontCenter,DASy
 SG_ VFC_Obj19B_BlockCtr : 24|4@1+ (1,0) [0|15] ""  RadarFrontCenter,DASy
 SG_ VFC_Obj19B_ScaleChange : 32|14@1+ (0.0001,0.5) [0.5|2.1] ""  RadarFrontCenter,DASy
 SG_ VFC_Obj19B_ScaleChngStdDev : 48|10@1+ (0.0001,0) [0|0.1] ""  RadarFrontCenter,DASy
 SG_ VFC_Obj19B_LineEdgeRightEgo : 58|1@1+ (1,0) [0|1] ""  RadarFrontCenter,DASy
 SG_ VFC_Obj19B_LineEdgeLeftEgo : 59|1@1+ (1,0) [0|1] ""  RadarFrontCenter,DASy
 SG_ VFC_Obj19B_CompletelyInImg : 60|1@1+ (1,0) [0|1] ""  RadarFrontCenter,DASy
 SG_ VFC_Obj19B_DirIndicator : 61|3@1+ (1,0) [0|7] ""  RadarFrontCenter,DASy
 SG_ VFC_Obj19B_LineEdgeAngle : 64|13@1+ (0.00025,-1) [-1|1] "rad"  RadarFrontCenter,DASy
 SG_ VFC_Obj19B_BrakeLight : 77|3@1+ (1,0) [0|7] ""  RadarFrontCenter,DASy
 SG_ VFC_Obj19B_MeasSource : 80|5@1+ (1,0) [0|31] ""  RadarFrontCenter,DASy
 SG_ VFC_Obj19B_Reliab : 98|6@1+ (1,0) [0|63] ""  RadarFrontCenter,DASy

BO_ 128 VFC_LineHeader: 16 MPC3
 SG_ VFC_LineHdr_AUTOSARTStamp : 96|26@1+ (1,0) [0|67108863] "ms"  DASy,RadarFrontCenter
 SG_ VFC_LineHdr_FrameNo : 28|4@1+ (1,0) [0|15] ""  RadarFrontCenter,DASy
 SG_ VFC_LineHdr_CRC : 0|16@1+ (1,0) [0|65535] ""  RadarFrontCenter,DASy
 SG_ VFC_LineHdr_AliveCtr : 16|8@1+ (1,0) [0|255] ""  RadarFrontCenter,DASy
 SG_ VFC_LineHdr_BlockCounter : 24|4@1+ (1,0) [0|15] ""  RadarFrontCenter,DASy
 SG_ VFC_LineHdr_Report : 32|8@1+ (1,0) [0|255] ""  RadarFrontCenter,DASy
 SG_ VFC_LineHdr_LineCount : 40|8@1+ (1,0) [0|255] ""  RadarFrontCenter,DASy
 SG_ VFC_LineHdr_PEPSIRuntime : 48|8@1+ (0.05,0) [0|10] "ms"  RadarFrontCenter,DASy
 SG_ VFC_LineHdr_TimeStamp : 56|26@1+ (1,0) [0|67108863] "ms"  RadarFrontCenter,DASy
 SG_ VFC_LineHdr_Blindness : 82|6@1+ (2,0) [0|100] "%"  RadarFrontCenter,DASy
 SG_ VFC_LineHdr_State : 88|3@1+ (1,0) [0|7] ""  RadarFrontCenter,DASy

BO_ 129 VFC_Line01: 32 MPC3
 SG_ VFC_Line01_CRC : 0|16@1+ (1,0) [0|65535] ""  RadarFrontCenter,DASy
 SG_ VFC_Line01_AliveCtr : 16|8@1+ (1,0) [0|255] ""  RadarFrontCenter,DASy
 SG_ VFC_Line01_BlockCounter : 24|4@1+ (1,0) [0|15] ""  RadarFrontCenter,DASy
 SG_ VFC_Line01_ProtOrderIndex : 32|6@1+ (1,0) [0|63] ""  RadarFrontCenter,DASy
 SG_ VFC_Line01_LineID : 40|8@1+ (1,0) [0|255] ""  RadarFrontCenter,DASy
 SG_ VFC_Line01_LaneRelation : 48|8@1+ (1,0) [0|255] ""  RadarFrontCenter,DASy
 SG_ VFC_Line01_ExistProb : 56|6@1+ (2,0) [0|100] "%"  RadarFrontCenter,DASy
 SG_ VFC_Line01_DxStart : 64|13@1+ (0.025,0) [0|204.775] "m"  RadarFrontCenter,DASy
 SG_ VFC_Line01_ColorClass : 77|3@1+ (1,0) [0|7] ""  RadarFrontCenter,DASy
 SG_ VFC_Line01_DxEnd : 80|10@1+ (0.25,0) [0|255.75] "m"  RadarFrontCenter,DASy
 SG_ VFC_Line01_HeadingAngle : 91|13@1+ (0.000488281,-1.6) [-1.6|1.6] "rad"  RadarFrontCenter,DASy
 SG_ VFC_Line01_Dy : 104|12@1+ (0.015625,-32) [-32|31.984375] "m"  RadarFrontCenter,DASy
 SG_ VFC_Line01_CurvChange : 116|12@1+ (3.8147E-006,-0.0078125) [-0.0078125|0.0078086965] "1/(m*m)"  RadarFrontCenter,DASy
 SG_ VFC_Line01_Curv : 128|13@1+ (3.8147E-006,-0.015625) [-0.015625|0.0156212077] "1/m"  RadarFrontCenter,DASy
 SG_ VFC_Line01_MeasureType : 141|3@1+ (1,0) [0|3] ""  RadarFrontCenter,DASy
 SG_ VFC_Line01_LineWidth : 144|8@1+ (0.01,0) [0|2.55] "m"  RadarFrontCenter,DASy
 SG_ VFC_Line01_CourseDeviation : 152|10@1+ (0.05,0) [0|50] ""  RadarFrontCenter,DASy
 SG_ VFC_Line01_Type : 162|5@1+ (1,0) [0|31] ""  RadarFrontCenter,DASy
 SG_ VFC_Line01_DyStdDevDxEnd : 167|9@1+ (0.0078125,0) [0|3.9921875] "m"  RadarFrontCenter,DASy
 SG_ VFC_Line01_HypoConfidence : 176|8@1+ (1,0) [0|255] ""  RadarFrontCenter,DASy
 SG_ VFC_Line01_prevID : 184|8@1+ (1,0) [0|255] ""  RadarFrontCenter,DASy
 SG_ VFC_Line01_nextID : 192|8@1+ (1,0) [0|255] ""  RadarFrontCenter,DASy
 SG_ VFC_Line01_DyStdDevDxStart : 200|9@1+ (0.0078125,0) [0|3.9921875] "m"  RadarFrontCenter,DASy
 SG_ VFC_Line01_TypeProb : 209|6@1+ (2,0) [0|100] "%"  RadarFrontCenter,DASy
 SG_ VFC_Line01_DyStdDevDxMid : 215|9@1+ (0.0078125,0) [0|3.9921875] "m"  RadarFrontCenter,DASy

BO_ 130 VFC_Line02: 32 MPC3
 SG_ VFC_Line02_CRC : 0|16@1+ (1,0) [0|65535] ""  RadarFrontCenter,DASy
 SG_ VFC_Line02_AliveCtr : 16|8@1+ (1,0) [0|255] ""  RadarFrontCenter,DASy
 SG_ VFC_Line02_BlockCounter : 24|4@1+ (1,0) [0|15] ""  RadarFrontCenter,DASy
 SG_ VFC_Line02_ProtOrderIndex : 32|6@1+ (1,0) [0|63] ""  RadarFrontCenter,DASy
 SG_ VFC_Line02_LineID : 40|8@1+ (1,0) [0|255] ""  RadarFrontCenter,DASy
 SG_ VFC_Line02_LaneRelation : 48|8@1+ (1,0) [0|255] ""  RadarFrontCenter,DASy
 SG_ VFC_Line02_ExistProb : 56|6@1+ (2,0) [0|100] "%"  RadarFrontCenter,DASy
 SG_ VFC_Line02_DxStart : 64|13@1+ (0.025,0) [0|204.775] "m"  RadarFrontCenter,DASy
 SG_ VFC_Line02_ColorClass : 77|3@1+ (1,0) [0|7] ""  RadarFrontCenter,DASy
 SG_ VFC_Line02_DxEnd : 80|10@1+ (0.25,0) [0|255.75] "m"  RadarFrontCenter,DASy
 SG_ VFC_Line02_HeadingAngle : 91|13@1+ (0.000488281,-1.6) [-1.6|1.6] "rad"  RadarFrontCenter,DASy
 SG_ VFC_Line02_Dy : 104|12@1+ (0.015625,-32) [-32|31.984375] "m"  RadarFrontCenter,DASy
 SG_ VFC_Line02_CurvChange : 116|12@1+ (3.8147E-006,-0.0078125) [-0.0078125|0.0078086965] "1/(m*m)"  RadarFrontCenter,DASy
 SG_ VFC_Line02_Curv : 128|13@1+ (3.8147E-006,-0.015625) [-0.015625|0.0156212077] "1/m"  RadarFrontCenter,DASy
 SG_ VFC_Line02_MeasureType : 141|3@1+ (1,0) [0|3] ""  RadarFrontCenter,DASy
 SG_ VFC_Line02_LineWidth : 144|8@1+ (0.01,0) [0|2.55] "m"  RadarFrontCenter,DASy
 SG_ VFC_Line02_CourseDeviation : 152|10@1+ (0.05,0) [0|50] ""  RadarFrontCenter,DASy
 SG_ VFC_Line02_Type : 162|5@1+ (1,0) [0|31] ""  RadarFrontCenter,DASy
 SG_ VFC_Line02_DyStdDevDxEnd : 167|9@1+ (0.0078125,0) [0|3.9921875] "m"  RadarFrontCenter,DASy
 SG_ VFC_Line02_HypoConfidence : 176|8@1+ (1,0) [0|255] ""  RadarFrontCenter,DASy
 SG_ VFC_Line02_prevID : 184|8@1+ (1,0) [0|255] ""  RadarFrontCenter,DASy
 SG_ VFC_Line02_nextID : 192|8@1+ (1,0) [0|255] ""  RadarFrontCenter,DASy
 SG_ VFC_Line02_DyStdDevDxStart : 200|9@1+ (0.0078125,0) [0|3.9921875] "m"  RadarFrontCenter,DASy
 SG_ VFC_Line02_TypeProb : 209|6@1+ (2,0) [0|100] "%"  RadarFrontCenter,DASy
 SG_ VFC_Line02_DyStdDevDxMid : 215|9@1+ (0.0078125,0) [0|3.9921875] "m"  RadarFrontCenter,DASy

BO_ 131 VFC_Line03: 32 MPC3
 SG_ VFC_Line03_CRC : 0|16@1+ (1,0) [0|65535] ""  RadarFrontCenter,DASy
 SG_ VFC_Line03_AliveCtr : 16|8@1+ (1,0) [0|255] ""  RadarFrontCenter,DASy
 SG_ VFC_Line03_BlockCounter : 24|4@1+ (1,0) [0|15] ""  RadarFrontCenter,DASy
 SG_ VFC_Line03_ProtOrderIndex : 32|6@1+ (1,0) [0|63] ""  RadarFrontCenter,DASy
 SG_ VFC_Line03_LineID : 40|8@1+ (1,0) [0|255] ""  RadarFrontCenter,DASy
 SG_ VFC_Line03_LaneRelation : 48|8@1+ (1,0) [0|255] ""  RadarFrontCenter,DASy
 SG_ VFC_Line03_ExistProb : 56|6@1+ (2,0) [0|100] "%"  RadarFrontCenter,DASy
 SG_ VFC_Line03_DxStart : 64|13@1+ (0.025,0) [0|204.775] "m"  RadarFrontCenter,DASy
 SG_ VFC_Line03_ColorClass : 77|3@1+ (1,0) [0|7] ""  RadarFrontCenter,DASy
 SG_ VFC_Line03_DxEnd : 80|10@1+ (0.25,0) [0|255.75] "m"  RadarFrontCenter,DASy
 SG_ VFC_Line03_HeadingAngle : 91|13@1+ (0.000488281,-1.6) [-1.6|1.6] "rad"  RadarFrontCenter,DASy
 SG_ VFC_Line03_Dy : 104|12@1+ (0.015625,-32) [-32|31.984375] "m"  RadarFrontCenter,DASy
 SG_ VFC_Line03_CurvChange : 116|12@1+ (3.8147E-006,-0.0078125) [-0.0078125|0.0078086965] "1/(m*m)"  RadarFrontCenter,DASy
 SG_ VFC_Line03_Curv : 128|13@1+ (3.8147E-006,-0.015625) [-0.015625|0.0156212077] "1/m"  RadarFrontCenter,DASy
 SG_ VFC_Line03_MeasureType : 141|3@1+ (1,0) [0|3] ""  RadarFrontCenter,DASy
 SG_ VFC_Line03_LineWidth : 144|8@1+ (0.01,0) [0|2.55] "m"  RadarFrontCenter,DASy
 SG_ VFC_Line03_CourseDeviation : 152|10@1+ (0.05,0) [0|50] ""  RadarFrontCenter,DASy
 SG_ VFC_Line03_Type : 162|5@1+ (1,0) [0|31] ""  RadarFrontCenter,DASy
 SG_ VFC_Line03_DyStdDevDxEnd : 167|9@1+ (0.0078125,0) [0|3.9921875] "m"  RadarFrontCenter,DASy
 SG_ VFC_Line03_HypoConfidence : 176|8@1+ (1,0) [0|255] ""  RadarFrontCenter,DASy
 SG_ VFC_Line03_prevID : 184|8@1+ (1,0) [0|255] ""  RadarFrontCenter,DASy
 SG_ VFC_Line03_nextID : 192|8@1+ (1,0) [0|255] ""  RadarFrontCenter,DASy
 SG_ VFC_Line03_DyStdDevDxStart : 200|9@1+ (0.0078125,0) [0|3.9921875] "m"  RadarFrontCenter,DASy
 SG_ VFC_Line03_TypeProb : 209|6@1+ (2,0) [0|100] "%"  RadarFrontCenter,DASy
 SG_ VFC_Line03_DyStdDevDxMid : 215|9@1+ (0.0078125,0) [0|3.9921875] "m"  RadarFrontCenter,DASy

BO_ 132 VFC_Line04: 32 MPC3
 SG_ VFC_Line04_CRC : 0|16@1+ (1,0) [0|65535] ""  RadarFrontCenter,DASy
 SG_ VFC_Line04_AliveCtr : 16|8@1+ (1,0) [0|255] ""  RadarFrontCenter,DASy
 SG_ VFC_Line04_BlockCounter : 24|4@1+ (1,0) [0|15] ""  RadarFrontCenter,DASy
 SG_ VFC_Line04_ProtOrderIndex : 32|6@1+ (1,0) [0|63] ""  RadarFrontCenter,DASy
 SG_ VFC_Line04_LineID : 40|8@1+ (1,0) [0|255] ""  RadarFrontCenter,DASy
 SG_ VFC_Line04_LaneRelation : 48|8@1+ (1,0) [0|255] ""  RadarFrontCenter,DASy
 SG_ VFC_Line04_ExistProb : 56|6@1+ (2,0) [0|100] "%"  RadarFrontCenter,DASy
 SG_ VFC_Line04_DxStart : 64|13@1+ (0.025,0) [0|204.775] "m"  RadarFrontCenter,DASy
 SG_ VFC_Line04_ColorClass : 77|3@1+ (1,0) [0|7] ""  RadarFrontCenter,DASy
 SG_ VFC_Line04_DxEnd : 80|10@1+ (0.25,0) [0|255.75] "m"  RadarFrontCenter,DASy
 SG_ VFC_Line04_HeadingAngle : 91|13@1+ (0.000488281,-1.6) [-1.6|1.6] "rad"  RadarFrontCenter,DASy
 SG_ VFC_Line04_Dy : 104|12@1+ (0.015625,-32) [-32|31.984375] "m"  RadarFrontCenter,DASy
 SG_ VFC_Line04_CurvChange : 116|12@1+ (3.8147E-006,-0.0078125) [-0.0078125|0.0078086965] "1/(m*m)"  RadarFrontCenter,DASy
 SG_ VFC_Line04_Curv : 128|13@1+ (3.8147E-006,-0.015625) [-0.015625|0.0156212077] "1/m"  RadarFrontCenter,DASy
 SG_ VFC_Line04_MeasureType : 141|3@1+ (1,0) [0|3] ""  RadarFrontCenter,DASy
 SG_ VFC_Line04_LineWidth : 144|8@1+ (0.01,0) [0|2.55] "m"  RadarFrontCenter,DASy
 SG_ VFC_Line04_CourseDeviation : 152|10@1+ (0.05,0) [0|50] ""  RadarFrontCenter,DASy
 SG_ VFC_Line04_Type : 162|5@1+ (1,0) [0|31] ""  RadarFrontCenter,DASy
 SG_ VFC_Line04_DyStdDevDxEnd : 167|9@1+ (0.0078125,0) [0|3.9921875] "m"  RadarFrontCenter,DASy
 SG_ VFC_Line04_HypoConfidence : 176|8@1+ (1,0) [0|255] ""  RadarFrontCenter,DASy
 SG_ VFC_Line04_prevID : 184|8@1+ (1,0) [0|255] ""  RadarFrontCenter,DASy
 SG_ VFC_Line04_nextID : 192|8@1+ (1,0) [0|255] ""  RadarFrontCenter,DASy
 SG_ VFC_Line04_DyStdDevDxStart : 200|9@1+ (0.0078125,0) [0|3.9921875] "m"  RadarFrontCenter,DASy
 SG_ VFC_Line04_TypeProb : 209|6@1+ (2,0) [0|100] "%"  RadarFrontCenter,DASy
 SG_ VFC_Line04_DyStdDevDxMid : 215|9@1+ (0.0078125,0) [0|3.9921875] "m"  RadarFrontCenter,DASy

BO_ 133 VFC_Line05: 32 MPC3
 SG_ VFC_Line05_CRC : 0|16@1+ (1,0) [0|65535] ""  RadarFrontCenter,DASy
 SG_ VFC_Line05_AliveCtr : 16|8@1+ (1,0) [0|255] ""  RadarFrontCenter,DASy
 SG_ VFC_Line05_BlockCounter : 24|4@1+ (1,0) [0|15] ""  RadarFrontCenter,DASy
 SG_ VFC_Line05_ProtOrderIndex : 32|6@1+ (1,0) [0|63] ""  RadarFrontCenter,DASy
 SG_ VFC_Line05_LineID : 40|8@1+ (1,0) [0|255] ""  RadarFrontCenter,DASy
 SG_ VFC_Line05_LaneRelation : 48|8@1+ (1,0) [0|255] ""  RadarFrontCenter,DASy
 SG_ VFC_Line05_ExistProb : 56|6@1+ (2,0) [0|100] "%"  RadarFrontCenter,DASy
 SG_ VFC_Line05_DxStart : 64|13@1+ (0.025,0) [0|204.775] "m"  RadarFrontCenter,DASy
 SG_ VFC_Line05_ColorClass : 77|3@1+ (1,0) [0|7] ""  RadarFrontCenter,DASy
 SG_ VFC_Line05_DxEnd : 80|10@1+ (0.25,0) [0|255.75] "m"  RadarFrontCenter,DASy
 SG_ VFC_Line05_HeadingAngle : 91|13@1+ (0.000488281,-1.6) [-1.6|1.6] "rad"  RadarFrontCenter,DASy
 SG_ VFC_Line05_Dy : 104|12@1+ (0.015625,-32) [-32|31.984375] "m"  RadarFrontCenter,DASy
 SG_ VFC_Line05_CurvChange : 116|12@1+ (3.8147E-006,-0.0078125) [-0.0078125|0.0078086965] "1/(m*m)"  RadarFrontCenter,DASy
 SG_ VFC_Line05_Curv : 128|13@1+ (3.8147E-006,-0.015625) [-0.015625|0.0156212077] "1/m"  RadarFrontCenter,DASy
 SG_ VFC_Line05_MeasureType : 141|3@1+ (1,0) [0|3] ""  RadarFrontCenter,DASy
 SG_ VFC_Line05_LineWidth : 144|8@1+ (0.01,0) [0|2.55] "m"  RadarFrontCenter,DASy
 SG_ VFC_Line05_CourseDeviation : 152|10@1+ (0.05,0) [0|50] ""  RadarFrontCenter,DASy
 SG_ VFC_Line05_Type : 162|5@1+ (1,0) [0|31] ""  RadarFrontCenter,DASy
 SG_ VFC_Line05_DyStdDevDxEnd : 167|9@1+ (0.0078125,0) [0|3.9921875] "m"  RadarFrontCenter,DASy
 SG_ VFC_Line05_HypoConfidence : 176|8@1+ (1,0) [0|255] ""  RadarFrontCenter,DASy
 SG_ VFC_Line05_prevID : 184|8@1+ (1,0) [0|255] ""  RadarFrontCenter,DASy
 SG_ VFC_Line05_nextID : 192|8@1+ (1,0) [0|255] ""  RadarFrontCenter,DASy
 SG_ VFC_Line05_DyStdDevDxStart : 200|9@1+ (0.0078125,0) [0|3.9921875] "m"  RadarFrontCenter,DASy
 SG_ VFC_Line05_TypeProb : 209|6@1+ (2,0) [0|100] "%"  RadarFrontCenter,DASy
 SG_ VFC_Line05_DyStdDevDxMid : 215|9@1+ (0.0078125,0) [0|3.9921875] "m"  RadarFrontCenter,DASy

BO_ 134 VFC_Line06: 32 MPC3
 SG_ VFC_Line06_CRC : 0|16@1+ (1,0) [0|65535] ""  RadarFrontCenter,DASy
 SG_ VFC_Line06_AliveCtr : 16|8@1+ (1,0) [0|255] ""  RadarFrontCenter,DASy
 SG_ VFC_Line06_BlockCounter : 24|4@1+ (1,0) [0|15] ""  RadarFrontCenter,DASy
 SG_ VFC_Line06_ProtOrderIndex : 32|6@1+ (1,0) [0|63] ""  RadarFrontCenter,DASy
 SG_ VFC_Line06_LineID : 40|8@1+ (1,0) [0|255] ""  RadarFrontCenter,DASy
 SG_ VFC_Line06_LaneRelation : 48|8@1+ (1,0) [0|255] ""  RadarFrontCenter,DASy
 SG_ VFC_Line06_ExistProb : 56|6@1+ (2,0) [0|100] "%"  RadarFrontCenter,DASy
 SG_ VFC_Line06_DxStart : 64|13@1+ (0.025,0) [0|204.775] "m"  RadarFrontCenter,DASy
 SG_ VFC_Line06_ColorClass : 77|3@1+ (1,0) [0|7] ""  RadarFrontCenter,DASy
 SG_ VFC_Line06_DxEnd : 80|10@1+ (0.25,0) [0|255.75] "m"  RadarFrontCenter,DASy
 SG_ VFC_Line06_HeadingAngle : 91|13@1+ (0.000488281,-1.6) [-1.6|1.6] "rad"  RadarFrontCenter,DASy
 SG_ VFC_Line06_Dy : 104|12@1+ (0.015625,-32) [-32|31.984375] "m"  RadarFrontCenter,DASy
 SG_ VFC_Line06_CurvChange : 116|12@1+ (3.8147E-006,-0.0078125) [-0.0078125|0.0078086965] "1/(m*m)"  RadarFrontCenter,DASy
 SG_ VFC_Line06_Curv : 128|13@1+ (3.8147E-006,-0.015625) [-0.015625|0.0156212077] "1/m"  RadarFrontCenter,DASy
 SG_ VFC_Line06_MeasureType : 141|3@1+ (1,0) [0|3] ""  RadarFrontCenter,DASy
 SG_ VFC_Line06_LineWidth : 144|8@1+ (0.01,0) [0|2.55] "m"  RadarFrontCenter,DASy
 SG_ VFC_Line06_CourseDeviation : 152|10@1+ (0.05,0) [0|50] ""  RadarFrontCenter,DASy
 SG_ VFC_Line06_Type : 162|5@1+ (1,0) [0|31] ""  RadarFrontCenter,DASy
 SG_ VFC_Line06_DyStdDevDxEnd : 167|9@1+ (0.0078125,0) [0|3.9921875] "m"  RadarFrontCenter,DASy
 SG_ VFC_Line06_HypoConfidence : 176|8@1+ (1,0) [0|255] ""  RadarFrontCenter,DASy
 SG_ VFC_Line06_prevID : 184|8@1+ (1,0) [0|255] ""  RadarFrontCenter,DASy
 SG_ VFC_Line06_nextID : 192|8@1+ (1,0) [0|255] ""  RadarFrontCenter,DASy
 SG_ VFC_Line06_DyStdDevDxStart : 200|9@1+ (0.0078125,0) [0|3.9921875] "m"  RadarFrontCenter,DASy
 SG_ VFC_Line06_TypeProb : 209|6@1+ (2,0) [0|100] "%"  RadarFrontCenter,DASy
 SG_ VFC_Line06_DyStdDevDxMid : 215|9@1+ (0.0078125,0) [0|3.9921875] "m"  RadarFrontCenter,DASy

BO_ 135 VFC_Line07: 32 MPC3
 SG_ VFC_Line07_CRC : 0|16@1+ (1,0) [0|65535] ""  RadarFrontCenter,DASy
 SG_ VFC_Line07_AliveCtr : 16|8@1+ (1,0) [0|255] ""  RadarFrontCenter,DASy
 SG_ VFC_Line07_BlockCounter : 24|4@1+ (1,0) [0|15] ""  RadarFrontCenter,DASy
 SG_ VFC_Line07_ProtOrderIndex : 32|6@1+ (1,0) [0|63] ""  RadarFrontCenter,DASy
 SG_ VFC_Line07_LineID : 40|8@1+ (1,0) [0|255] ""  RadarFrontCenter,DASy
 SG_ VFC_Line07_LaneRelation : 48|8@1+ (1,0) [0|255] ""  RadarFrontCenter,DASy
 SG_ VFC_Line07_ExistProb : 56|6@1+ (2,0) [0|100] "%"  RadarFrontCenter,DASy
 SG_ VFC_Line07_DxStart : 64|13@1+ (0.025,0) [0|204.775] "m"  RadarFrontCenter,DASy
 SG_ VFC_Line07_ColorClass : 77|3@1+ (1,0) [0|7] ""  RadarFrontCenter,DASy
 SG_ VFC_Line07_DxEnd : 80|10@1+ (0.25,0) [0|255.75] "m"  RadarFrontCenter,DASy
 SG_ VFC_Line07_HeadingAngle : 91|13@1+ (0.000488281,-1.6) [-1.6|1.6] "rad"  RadarFrontCenter,DASy
 SG_ VFC_Line07_Dy : 104|12@1+ (0.015625,-32) [-32|31.984375] "m"  RadarFrontCenter,DASy
 SG_ VFC_Line07_CurvChange : 116|12@1+ (3.8147E-006,-0.0078125) [-0.0078125|0.0078086965] "1/(m*m)"  RadarFrontCenter,DASy
 SG_ VFC_Line07_Curv : 128|13@1+ (3.8147E-006,-0.015625) [-0.015625|0.0156212077] "1/m"  RadarFrontCenter,DASy
 SG_ VFC_Line07_MeasureType : 141|3@1+ (1,0) [0|3] ""  RadarFrontCenter,DASy
 SG_ VFC_Line07_LineWidth : 144|8@1+ (0.01,0) [0|2.55] "m"  RadarFrontCenter,DASy
 SG_ VFC_Line07_CourseDeviation : 152|10@1+ (0.05,0) [0|50] ""  RadarFrontCenter,DASy
 SG_ VFC_Line07_Type : 162|5@1+ (1,0) [0|31] ""  RadarFrontCenter,DASy
 SG_ VFC_Line07_DyStdDevDxEnd : 167|9@1+ (0.0078125,0) [0|3.9921875] "m"  RadarFrontCenter,DASy
 SG_ VFC_Line07_HypoConfidence : 176|8@1+ (1,0) [0|255] ""  RadarFrontCenter,DASy
 SG_ VFC_Line07_prevID : 184|8@1+ (1,0) [0|255] ""  RadarFrontCenter,DASy
 SG_ VFC_Line07_nextID : 192|8@1+ (1,0) [0|255] ""  RadarFrontCenter,DASy
 SG_ VFC_Line07_DyStdDevDxStart : 200|9@1+ (0.0078125,0) [0|3.9921875] "m"  RadarFrontCenter,DASy
 SG_ VFC_Line07_TypeProb : 209|6@1+ (2,0) [0|100] "%"  RadarFrontCenter,DASy
 SG_ VFC_Line07_DyStdDevDxMid : 215|9@1+ (0.0078125,0) [0|3.9921875] "m"  RadarFrontCenter,DASy

BO_ 136 VFC_Line08: 32 MPC3
 SG_ VFC_Line08_CRC : 0|16@1+ (1,0) [0|65535] ""  RadarFrontCenter,DASy
 SG_ VFC_Line08_AliveCtr : 16|8@1+ (1,0) [0|255] ""  RadarFrontCenter,DASy
 SG_ VFC_Line08_BlockCounter : 24|4@1+ (1,0) [0|15] ""  RadarFrontCenter,DASy
 SG_ VFC_Line08_ProtOrderIndex : 32|6@1+ (1,0) [0|63] ""  RadarFrontCenter,DASy
 SG_ VFC_Line08_LineID : 40|8@1+ (1,0) [0|255] ""  RadarFrontCenter,DASy
 SG_ VFC_Line08_LaneRelation : 48|8@1+ (1,0) [0|255] ""  RadarFrontCenter,DASy
 SG_ VFC_Line08_ExistProb : 56|6@1+ (2,0) [0|100] "%"  RadarFrontCenter,DASy
 SG_ VFC_Line08_DxStart : 64|13@1+ (0.025,0) [0|204.775] "m"  RadarFrontCenter,DASy
 SG_ VFC_Line08_ColorClass : 77|3@1+ (1,0) [0|7] ""  RadarFrontCenter,DASy
 SG_ VFC_Line08_DxEnd : 80|10@1+ (0.25,0) [0|255.75] "m"  RadarFrontCenter,DASy
 SG_ VFC_Line08_HeadingAngle : 91|13@1+ (0.000488281,-1.6) [-1.6|1.6] "rad"  RadarFrontCenter,DASy
 SG_ VFC_Line08_Dy : 104|12@1+ (0.015625,-32) [-32|31.984375] "m"  RadarFrontCenter,DASy
 SG_ VFC_Line08_CurvChange : 116|12@1+ (3.8147E-006,-0.0078125) [-0.0078125|0.0078086965] "1/(m*m)"  RadarFrontCenter,DASy
 SG_ VFC_Line08_Curv : 128|13@1+ (3.8147E-006,-0.015625) [-0.015625|0.0156212077] "1/m"  RadarFrontCenter,DASy
 SG_ VFC_Line08_MeasureType : 141|3@1+ (1,0) [0|3] ""  RadarFrontCenter,DASy
 SG_ VFC_Line08_LineWidth : 144|8@1+ (0.01,0) [0|2.55] "m"  RadarFrontCenter,DASy
 SG_ VFC_Line08_CourseDeviation : 152|10@1+ (0.05,0) [0|50] ""  RadarFrontCenter,DASy
 SG_ VFC_Line08_Type : 162|5@1+ (1,0) [0|31] ""  RadarFrontCenter,DASy
 SG_ VFC_Line08_DyStdDevDxEnd : 167|9@1+ (0.0078125,0) [0|3.9921875] "m"  RadarFrontCenter,DASy
 SG_ VFC_Line08_HypoConfidence : 176|8@1+ (1,0) [0|255] ""  RadarFrontCenter,DASy
 SG_ VFC_Line08_prevID : 184|8@1+ (1,0) [0|255] ""  RadarFrontCenter,DASy
 SG_ VFC_Line08_nextID : 192|8@1+ (1,0) [0|255] ""  RadarFrontCenter,DASy
 SG_ VFC_Line08_DyStdDevDxStart : 200|9@1+ (0.0078125,0) [0|3.9921875] "m"  RadarFrontCenter,DASy
 SG_ VFC_Line08_TypeProb : 209|6@1+ (2,0) [0|100] "%"  RadarFrontCenter,DASy
 SG_ VFC_Line08_DyStdDevDxMid : 215|9@1+ (0.0078125,0) [0|3.9921875] "m"  RadarFrontCenter,DASy

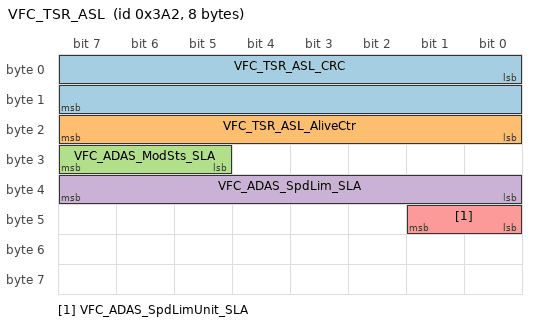
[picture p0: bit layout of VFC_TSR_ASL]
BO_ 930 VFC_TSR_ASL: 8 MPC3
 SG_ VFC_TSR_ASL_CRC : 0|16@1+ (1,0) [0|65535] ""  RadarFrontCenter,DASy
 SG_ VFC_TSR_ASL_AliveCtr : 16|8@1+ (1,0) [0|255] ""  RadarFrontCenter,DASy
 SG_ VFC_ADAS_ModSts_SLA : 29|3@1+ (1,0) [0|7] ""  RadarFrontCenter,DASy
 SG_ VFC_ADAS_SpdLim_SLA : 32|8@1+ (1,0) [0|255] ""  RadarFrontCenter,DASy
 SG_ VFC_ADAS_SpdLimUnit_SLA : 40|2@1+ (1,0) [0|3] ""  RadarFrontCenter,DASy

CM_ SG_ 206 VFC_Obj15A_CRC "CRC - Autosar E2E Profile 5";
CM_ SG_ 206 VFC_Obj15A_AliveCtr "Alive counter - Autosar E2E Profile 5";
CM_ SG_ 206 VFC_Obj15A_BlockCtr "Protocol-Signal: Block-Counter";
CM_ SG_ 206 VFC_Obj15A_ProtOrderIndex "Protocol-Signal: Index to ensure same order in Tx and Rx of the objects";
CM_ SG_ 206 VFC_Obj15A_Ax "Object Acceleration in longitudinal direction";
CM_ SG_ 206 VFC_Obj15A_Vx "Object Velocity in longitudinal direction";
CM_ SG_ 206 VFC_Obj15A_Dx "Object Position in longitudinal direction";
CM_ SG_ 206 VFC_Obj15A_Dy "Object Position in lateral direction";
CM_ SG_ 206 VFC_Obj15A_Vy "Object Velocity in lateral direction";
CM_ SG_ 206 VFC_Obj15A_Ay "Object Acceleration in lateral direction";
CM_ SG_ 206 VFC_Obj15A_DyStdDev "Standard deviation of Object position in lateral direction";
CM_ SG_ 206 VFC_Obj15A_DxStdDev "Standard deviation of Object position in longitudinal direction";
CM_ SG_ 206 VFC_Obj15A_VxStdDev "Standard deviation of Object velocity in longitudinal direction";
CM_ SG_ 206 VFC_Obj15A_ExistProb "Object existence probability";
CM_ SG_ 206 VFC_Obj15A_VyStdDev "Standard deviation of Object velocity in lateral direction";
CM_ SG_ 206 VFC_Obj15A_TypeProb "Probability of the classified object type";
CM_ SG_ 206 VFC_Obj15A_AxStdDev "Standard deviation of Object acceleration in longitudinal direction";
CM_ SG_ 206 VFC_Obj15A_AyStdDev "Standard deviation of Object acceleration in lateral direction";
CM_ SG_ 206 VFC_Obj15A_PhiLeft "ACCS Viewing Angle of left object edge(dimensionless)";
CM_ SG_ 206 VFC_Obj15A_ClassifiedView "The classified view of object to be used in connection with Heading angle";
CM_ SG_ 206 VFC_Obj15A_Length "Length of the object";
CM_ SG_ 206 VFC_Obj15A_WidthStdDev "Standard deviation of object width";
CM_ SG_ 206 VFC_Obj15A_Height "Height of the object";
CM_ SG_ 206 VFC_Obj15A_HeightStdDev "Standard deviation of object height";
CM_ SG_ 206 VFC_Obj15A_PhiLeftStdDev "Standard deviation of the ACCS angle of left object(dimensionless)";
CM_ SG_ 206 VFC_Obj15A_HeadingStdDev "Standard deviation of object Heading angle";
CM_ SG_ 206 VFC_Obj15A_Measured "Indicator if the object detected is measured or predicted.";
CM_ SG_ 206 VFC_Obj15A_Heading "Heading angle of the object";
CM_ SG_ 206 VFC_Obj15A_LengthStdDev "Standard deviation of object length";
CM_ SG_ 206 VFC_Obj15A_PhiMid "Viewing angle of the ACCS middle of the object(dimensionless)";
CM_ SG_ 206 VFC_Obj15A_Width "Width of the object";
CM_ SG_ 206 VFC_Obj15A_PhiMidStdDev "Standard deviation of the ACCS middle angle of object(dimensionless)";
CM_ SG_ 206 VFC_Obj15A_PhiRight "ACCS Viewing Angle of right object edge(dimensionless)";
CM_ SG_ 206 VFC_Obj15A_VisibleView "The visible view of the detectd object";
CM_ SG_ 206 VFC_Obj15A_PhiRightStdDev "Standard deviation of the ACCS angle of right object(dimensionless)";
CM_ SG_ 206 VFC_Obj15A_PhiLeftVel "Velocity of the ACCS viewing angle of the left edge";
CM_ SG_ 206 VFC_Obj15A_PhiRightVel "Velocity of the ACCS viewing angle of the right edge";
CM_ SG_ 206 VFC_Obj15A_PhiRightVelStdDev "Standard deviation of ACCS viewing angle velocity of right object edge from ego vehicle related to camera";
CM_ SG_ 206 VFC_Obj15A_PhiLeftVelStdDev "Standard deviation of ACCS viewing angle velocity of left object edge from ego vehicle related to camera";
CM_ SG_ 206 VFC_Obj15A_PhiTop "ACCS Viewing angle of the top of the object(dimensionless)";
CM_ SG_ 206 VFC_Obj15A_PhiBottom "ACCS Viewing angle of the bottom of the object(dimensionless)";
CM_ SG_ 206 VFC_Obj15A_PhiTopStdDev "Standard deviation  of the ACCS top angle of object(dimensionless)";
CM_ SG_ 206 VFC_Obj15A_HeadOrientation "The orientation of the head of cyclists or pedestrians that are detected.";
CM_ SG_ 206 VFC_Obj15A_Type "Classification of the object";
CM_ SG_ 206 VFC_Obj15A_PhiBottomStdDev "Standard deviation of the ACCS bottom angle of object(dimensionless)";
CM_ SG_ 206 VFC_Obj15A_NormVx "Normalised object velocity in longitudinal direction.";
CM_ SG_ 206 VFC_Obj15A_NormAx "Normalised object acceleration in longitudinal direction.";
CM_ SG_ 206 VFC_Obj15A_NormAxStdDev "Standard deviation of Normalized Object Acceleration in longitudinal direction";
CM_ SG_ 206 VFC_Obj15A_ProbMovingLat "Probability of object moving laterally";
CM_ SG_ 206 VFC_Obj15A_ID "Unique Object ID";
CM_ SG_ 206 VFC_Obj15A_NormVxStdDev "Standard deviation of Normalized Object Velocity in longitudinal direction";
CM_ SG_ 206 VFC_Obj15A_ProbMovingLong "Probability of object moving longitudinally";
CM_ SG_ 207 VFC_Obj15B_TTIPC_StdDev "Inverse TTI standard deviation";
CM_ SG_ 207 VFC_Obj15B_TTIPC "Inverse TTI";
CM_ SG_ 207 VFC_Obj15B_AngLongitude "angular velocity with regarding to longitudinal direction";
CM_ SG_ 207 VFC_Obj15B_CRC "CRC - Autosar E2E Profile 5";
CM_ SG_ 207 VFC_Obj15B_AliveCtr "Alive counter - Autosar E2E Profile 5";
CM_ SG_ 207 VFC_Obj15B_BlockCtr "Protocol-Signal: Block Counter";
CM_ SG_ 207 VFC_Obj15B_ScaleChange "A scale change of of the detected object";
CM_ SG_ 207 VFC_Obj15B_ScaleChngStdDev "Standard deviation of object scale change";
CM_ SG_ 207 VFC_Obj15B_LineEdgeRightEgo "ObjLineEdgeAngle refers to the line which limits the host vehicle lane on the right side";
CM_ SG_ 207 VFC_Obj15B_LineEdgeLeftEgo "ObjLineEdgeAngle refers to the line which limits the host vehicle lane on the left side";
CM_ SG_ 207 VFC_Obj15B_CompletelyInImg "indicator if the object is completely measrued in the image";
CM_ SG_ 207 VFC_Obj15B_DirIndicator "The detected direction indicator lights";
CM_ SG_ 207 VFC_Obj15B_LineEdgeAngle "Angle between the video object's edge and the lane marking";
CM_ SG_ 207 VFC_Obj15B_BrakeLight "The number of detected lights. More confident if more lights are detected.";
CM_ SG_ 207 VFC_Obj15B_MeasSource "Bitmask for the measurement programs from which this object originates";
CM_ SG_ 207 VFC_Obj15B_Reliab "Bitmask that indicates the algorithmic paths that have detected this object";
CM_ SG_ 208 VFC_Obj16A_CRC "CRC - Autosar E2E Profile 5";
CM_ SG_ 208 VFC_Obj16A_AliveCtr "Alive counter - Autosar E2E Profile 5";
CM_ SG_ 208 VFC_Obj16A_BlockCtr "Protocol-Signal: Block-Counter";
CM_ SG_ 208 VFC_Obj16A_ProtOrderIndex "Protocol-Signal: Index to ensure same order in Tx and Rx of the objects";
CM_ SG_ 208 VFC_Obj16A_Ax "Object Acceleration in longitudinal direction";
CM_ SG_ 208 VFC_Obj16A_Vx "Object Velocity in longitudinal direction";
CM_ SG_ 208 VFC_Obj16A_Dx "Object Position in longitudinal direction";
CM_ SG_ 208 VFC_Obj16A_Dy "Object Position in lateral direction";
CM_ SG_ 208 VFC_Obj16A_Vy "Object Velocity in lateral direction";
CM_ SG_ 208 VFC_Obj16A_Ay "Object Acceleration in lateral direction";
CM_ SG_ 208 VFC_Obj16A_DyStdDev "Standard deviation of Object position in lateral direction";
CM_ SG_ 208 VFC_Obj16A_DxStdDev "Standard deviation of Object position in longitudinal direction";
CM_ SG_ 208 VFC_Obj16A_VxStdDev "Standard deviation of Object velocity in longitudinal direction";
CM_ SG_ 208 VFC_Obj16A_ExistProb "Object existence probability";
CM_ SG_ 208 VFC_Obj16A_VyStdDev "Standard deviation of Object velocity in lateral direction";
CM_ SG_ 208 VFC_Obj16A_TypeProb "Probability of the classified object type";
CM_ SG_ 208 VFC_Obj16A_AxStdDev "Standard deviation of Object acceleration in longitudinal direction";
CM_ SG_ 208 VFC_Obj16A_AyStdDev "Standard deviation of Object acceleration in lateral direction";
CM_ SG_ 208 VFC_Obj16A_PhiLeft "ACCS Viewing Angle of left object edge(dimensionless)";
CM_ SG_ 208 VFC_Obj16A_ClassifiedView "The classified view of object to be used in connection with Heading angle";
CM_ SG_ 208 VFC_Obj16A_Length "Length of the object";
CM_ SG_ 208 VFC_Obj16A_WidthStdDev "Standard deviation of object width";
CM_ SG_ 208 VFC_Obj16A_Height "Height of the object";
CM_ SG_ 208 VFC_Obj16A_HeightStdDev "Standard deviation of object height";
CM_ SG_ 208 VFC_Obj16A_PhiLeftStdDev "Standard deviation of the ACCS angle of left object(dimensionless)";
CM_ SG_ 208 VFC_Obj16A_HeadingStdDev "Standard deviation of object Heading angle";
CM_ SG_ 208 VFC_Obj16A_Measured "Indicator if the object detected is measured or predicted.";
CM_ SG_ 208 VFC_Obj16A_Heading "Heading angle of the object";
CM_ SG_ 208 VFC_Obj16A_LengthStdDev "Standard deviation of object length";
CM_ SG_ 208 VFC_Obj16A_PhiMid "Viewing angle of the ACCS middle of the object(dimensionless)";
CM_ SG_ 208 VFC_Obj16A_Width "Width of the object";
CM_ SG_ 208 VFC_Obj16A_PhiMidStdDev "Standard deviation of the ACCS middle angle of object(dimensionless)";
CM_ SG_ 208 VFC_Obj16A_PhiRight "ACCS Viewing Angle of right object edge(dimensionless)";
CM_ SG_ 208 VFC_Obj16A_VisibleView "The visible view of the detectd object";
CM_ SG_ 208 VFC_Obj16A_PhiRightStdDev "Standard deviation of the ACCS angle of right object(dimensionless)";
CM_ SG_ 208 VFC_Obj16A_PhiLeftVel "Velocity of the ACCS viewing angle of the left edge";
CM_ SG_ 208 VFC_Obj16A_PhiRightVel "Velocity of the ACCS viewing angle of the right edge";
CM_ SG_ 208 VFC_Obj16A_PhiRightVelStdDev "Standard deviation of ACCS viewing angle velocity of right object edge from ego vehicle related to camera";
CM_ SG_ 208 VFC_Obj16A_PhiLeftVelStdDev "Standard deviation of ACCS viewing angle velocity of left object edge from ego vehicle related to camera";
CM_ SG_ 208 VFC_Obj16A_PhiTop "ACCS Viewing angle of the top of the object(dimensionless)";
CM_ SG_ 208 VFC_Obj16A_PhiBottom "ACCS Viewing angle of the bottom of the object(dimensionless)";
CM_ SG_ 208 VFC_Obj16A_PhiTopStdDev "Standard deviation  of the ACCS top angle of object(dimensionless)";
CM_ SG_ 208 VFC_Obj16A_HeadOrientation "The orientation of the head of cyclists or pedestrians that are detected.";
CM_ SG_ 208 VFC_Obj16A_Type "Classification of the object";
CM_ SG_ 208 VFC_Obj16A_PhiBottomStdDev "Standard deviation of the ACCS bottom angle of object(dimensionless)";
CM_ SG_ 208 VFC_Obj16A_NormVx "Normalised object velocity in longitudinal direction.";
CM_ SG_ 208 VFC_Obj16A_NormAx "Normalised object acceleration in longitudinal direction.";
CM_ SG_ 208 VFC_Obj16A_NormAxStdDev "Standard deviation of Normalized Object Acceleration in longitudinal direction";
CM_ SG_ 208 VFC_Obj16A_ProbMovingLat "Probability of object moving laterally";
CM_ SG_ 208 VFC_Obj16A_ID "Unique Object ID";
CM_ SG_ 208 VFC_Obj16A_NormVxStdDev "Standard deviation of Normalized Object Velocity in longitudinal direction";
CM_ SG_ 208 VFC_Obj16A_ProbMovingLong "Probability of object moving longitudinally";
CM_ SG_ 209 VFC_Obj16B_TTIPC_StdDev "Inverse TTI standard deviation";
CM_ SG_ 209 VFC_Obj16B_TTIPC "Inverse TTI";
CM_ SG_ 209 VFC_Obj16B_AngLongitude "angular velocity with regarding to longitudinal direction";
CM_ SG_ 209 VFC_Obj16B_CRC "CRC - Autosar E2E Profile 5";
CM_ SG_ 209 VFC_Obj16B_AliveCtr "Alive counter - Autosar E2E Profile 5";
CM_ SG_ 209 VFC_Obj16B_BlockCtr "Protocol-Signal: Block Counter";
CM_ SG_ 209 VFC_Obj16B_ScaleChange "A scale change of of the detected object";
CM_ SG_ 209 VFC_Obj16B_ScaleChngStdDev "Standard deviation of object scale change";
CM_ SG_ 209 VFC_Obj16B_LineEdgeRightEgo "ObjLineEdgeAngle refers to the line which limits the host vehicle lane on the right side";
CM_ SG_ 209 VFC_Obj16B_LineEdgeLeftEgo "ObjLineEdgeAngle refers to the line which limits the host vehicle lane on the left side";
CM_ SG_ 209 VFC_Obj16B_CompletelyInImg "indicator if the object is completely measrued in the image";
CM_ SG_ 209 VFC_Obj16B_DirIndicator "The detected direction indicator lights";
CM_ SG_ 209 VFC_Obj16B_LineEdgeAngle "Angle between the video object's edge and the lane marking";
CM_ SG_ 209 VFC_Obj16B_BrakeLight "The number of detected lights. More confident if more lights are detected.";
CM_ SG_ 209 VFC_Obj16B_MeasSource "Bitmask for the measurement programs from which this object originates";
CM_ SG_ 209 VFC_Obj16B_Reliab "Bitmask that indicates the algorithmic paths that have detected this object";
CM_ SG_ 210 VFC_Obj17A_CRC "CRC - Autosar E2E Profile 5";
CM_ SG_ 210 VFC_Obj17A_AliveCtr "Alive counter - Autosar E2E Profile 5";
CM_ SG_ 210 VFC_Obj17A_BlockCtr "Protocol-Signal: Block-Counter";
CM_ SG_ 210 VFC_Obj17A_ProtOrderIndex "Protocol-Signal: Index to ensure same order in Tx and Rx of the objects";
CM_ SG_ 210 VFC_Obj17A_Ax "Object Acceleration in longitudinal direction";
CM_ SG_ 210 VFC_Obj17A_Vx "Object Velocity in longitudinal direction";
CM_ SG_ 210 VFC_Obj17A_Dx "Object Position in longitudinal direction";
CM_ SG_ 210 VFC_Obj17A_Dy "Object Position in lateral direction";
CM_ SG_ 210 VFC_Obj17A_Vy "Object Velocity in lateral direction";
CM_ SG_ 210 VFC_Obj17A_Ay "Object Acceleration in lateral direction";
CM_ SG_ 210 VFC_Obj17A_DyStdDev "Standard deviation of Object position in lateral direction";
CM_ SG_ 210 VFC_Obj17A_DxStdDev "Standard deviation of Object position in longitudinal direction";
CM_ SG_ 210 VFC_Obj17A_VxStdDev "Standard deviation of Object velocity in longitudinal direction";
CM_ SG_ 210 VFC_Obj17A_ExistProb "Object existence probability";
CM_ SG_ 210 VFC_Obj17A_VyStdDev "Standard deviation of Object velocity in lateral direction";
CM_ SG_ 210 VFC_Obj17A_TypeProb "Probability of the classified object type";
CM_ SG_ 210 VFC_Obj17A_AxStdDev "Standard deviation of Object acceleration in longitudinal direction";
CM_ SG_ 210 VFC_Obj17A_AyStdDev "Standard deviation of Object acceleration in lateral direction";
CM_ SG_ 210 VFC_Obj17A_PhiLeft "ACCS Viewing Angle of left object edge(dimensionless)";
CM_ SG_ 210 VFC_Obj17A_ClassifiedView "The classified view of object to be used in connection with Heading angle";
CM_ SG_ 210 VFC_Obj17A_Length "Length of the object";
CM_ SG_ 210 VFC_Obj17A_WidthStdDev "Standard deviation of object width";
CM_ SG_ 210 VFC_Obj17A_Height "Height of the object";
CM_ SG_ 210 VFC_Obj17A_HeightStdDev "Standard deviation of object height";
CM_ SG_ 210 VFC_Obj17A_PhiLeftStdDev "Standard deviation of the ACCS angle of left object(dimensionless)";
CM_ SG_ 210 VFC_Obj17A_HeadingStdDev "Standard deviation of object Heading angle";
CM_ SG_ 210 VFC_Obj17A_Measured "Indicator if the object detected is measured or predicted.";
CM_ SG_ 210 VFC_Obj17A_Heading "Heading angle of the object";
CM_ SG_ 210 VFC_Obj17A_LengthStdDev "Standard deviation of object length";
CM_ SG_ 210 VFC_Obj17A_PhiMid "Viewing angle of the ACCS middle of the object(dimensionless)";
CM_ SG_ 210 VFC_Obj17A_Width "Width of the object";
CM_ SG_ 210 VFC_Obj17A_PhiMidStdDev "Standard deviation of the ACCS middle angle of object(dimensionless)";
CM_ SG_ 210 VFC_Obj17A_PhiRight "ACCS Viewing Angle of right object edge(dimensionless)";
CM_ SG_ 210 VFC_Obj17A_VisibleView "The visible view of the detectd object";
CM_ SG_ 210 VFC_Obj17A_PhiRightStdDev "Standard deviation of the ACCS angle of right object(dimensionless)";
CM_ SG_ 210 VFC_Obj17A_PhiLeftVel "Velocity of the ACCS viewing angle of the left edge";
CM_ SG_ 210 VFC_Obj17A_PhiRightVel "Velocity of the ACCS viewing angle of the right edge";
CM_ SG_ 210 VFC_Obj17A_PhiRightVelStdDev "Standard deviation of ACCS viewing angle velocity of right object edge from ego vehicle related to camera";
CM_ SG_ 210 VFC_Obj17A_PhiLeftVelStdDev "Standard deviation of ACCS viewing angle velocity of left object edge from ego vehicle related to camera";
CM_ SG_ 210 VFC_Obj17A_PhiTop "ACCS Viewing angle of the top of the object(dimensionless)";
CM_ SG_ 210 VFC_Obj17A_PhiBottom "ACCS Viewing angle of the bottom of the object(dimensionless)";
CM_ SG_ 210 VFC_Obj17A_PhiTopStdDev "Standard deviation  of the ACCS top angle of object(dimensionless)";
CM_ SG_ 210 VFC_Obj17A_HeadOrientation "The orientation of the head of cyclists or pedestrians that are detected.";
CM_ SG_ 210 VFC_Obj17A_Type "Classification of the object";
CM_ SG_ 210 VFC_Obj17A_PhiBottomStdDev "Standard deviation of the ACCS bottom angle of object(dimensionless)";
CM_ SG_ 210 VFC_Obj17A_NormVx "Normalised object velocity in longitudinal direction.";
CM_ SG_ 210 VFC_Obj17A_NormAx "Normalised object acceleration in longitudinal direction.";
CM_ SG_ 210 VFC_Obj17A_NormAxStdDev "Standard deviation of Normalized Object Acceleration in longitudinal direction";
CM_ SG_ 210 VFC_Obj17A_ProbMovingLat "Probability of object moving laterally";
CM_ SG_ 210 VFC_Obj17A_ID "Unique Object ID";
CM_ SG_ 210 VFC_Obj17A_NormVxStdDev "Standard deviation of Normalized Object Velocity in longitudinal direction";
CM_ SG_ 210 VFC_Obj17A_ProbMovingLong "Probability of object moving longitudinally";
CM_ SG_ 211 VFC_Obj17B_TTIPC_StdDev "Inverse TTI standard deviation";
CM_ SG_ 211 VFC_Obj17B_TTIPC "Inverse TTI";
CM_ SG_ 211 VFC_Obj17B_AngLongitude "angular velocity with regarding to longitudinal direction";
CM_ SG_ 211 VFC_Obj17B_CRC "CRC - Autosar E2E Profile 5";
CM_ SG_ 211 VFC_Obj17B_AliveCtr "Alive counter - Autosar E2E Profile 5";
CM_ SG_ 211 VFC_Obj17B_BlockCtr "Protocol-Signal: Block Counter";
CM_ SG_ 211 VFC_Obj17B_ScaleChange "A scale change of of the detected object";
CM_ SG_ 211 VFC_Obj17B_ScaleChngStdDev "Standard deviation of object scale change";
CM_ SG_ 211 VFC_Obj17B_LineEdgeRightEgo "ObjLineEdgeAngle refers to the line which limits the host vehicle lane on the right side";
CM_ SG_ 211 VFC_Obj17B_LineEdgeLeftEgo "ObjLineEdgeAngle refers to the line which limits the host vehicle lane on the left side";
CM_ SG_ 211 VFC_Obj17B_CompletelyInImg "indicator if the object is completely measrued in the image";
CM_ SG_ 211 VFC_Obj17B_DirIndicator "The detected direction indicator lights";
CM_ SG_ 211 VFC_Obj17B_LineEdgeAngle "Angle between the video object's edge and the lane marking";
CM_ SG_ 211 VFC_Obj17B_BrakeLight "The number of detected lights. More confident if more lights are detected.";
CM_ SG_ 211 VFC_Obj17B_MeasSource "Bitmask for the measurement programs from which this object originates";
CM_ SG_ 211 VFC_Obj17B_Reliab "Bitmask that indicates the algorithmic paths that have detected this object";
CM_ SG_ 212 VFC_Obj18A_CRC "CRC - Autosar E2E Profile 5";
CM_ SG_ 212 VFC_Obj18A_AliveCtr "Alive counter - Autosar E2E Profile 5";
CM_ SG_ 212 VFC_Obj18A_BlockCtr "Protocol-Signal: Block-Counter";
CM_ SG_ 212 VFC_Obj18A_ProtOrderIndex "Protocol-Signal: Index to ensure same order in Tx and Rx of the objects";
CM_ SG_ 212 VFC_Obj18A_Ax "Object Acceleration in longitudinal direction";
CM_ SG_ 212 VFC_Obj18A_Vx "Object Velocity in longitudinal direction";
CM_ SG_ 212 VFC_Obj18A_Dx "Object Position in longitudinal direction";
CM_ SG_ 212 VFC_Obj18A_Dy "Object Position in lateral direction";
CM_ SG_ 212 VFC_Obj18A_Vy "Object Velocity in lateral direction";
CM_ SG_ 212 VFC_Obj18A_Ay "Object Acceleration in lateral direction";
CM_ SG_ 212 VFC_Obj18A_DyStdDev "Standard deviation of Object position in lateral direction";
CM_ SG_ 212 VFC_Obj18A_DxStdDev "Standard deviation of Object position in longitudinal direction";
CM_ SG_ 212 VFC_Obj18A_VxStdDev "Standard deviation of Object velocity in longitudinal direction";
CM_ SG_ 212 VFC_Obj18A_ExistProb "Object existence probability";
CM_ SG_ 212 VFC_Obj18A_VyStdDev "Standard deviation of Object velocity in lateral direction";
CM_ SG_ 212 VFC_Obj18A_TypeProb "Probability of the classified object type";
CM_ SG_ 212 VFC_Obj18A_AxStdDev "Standard deviation of Object acceleration in longitudinal direction";
CM_ SG_ 212 VFC_Obj18A_AyStdDev "Standard deviation of Object acceleration in lateral direction";
CM_ SG_ 212 VFC_Obj18A_PhiLeft "ACCS Viewing Angle of left object edge(dimensionless)";
CM_ SG_ 212 VFC_Obj18A_ClassifiedView "The classified view of object to be used in connection with Heading angle";
CM_ SG_ 212 VFC_Obj18A_Length "Length of the object";
CM_ SG_ 212 VFC_Obj18A_WidthStdDev "Standard deviation of object width";
CM_ SG_ 212 VFC_Obj18A_Height "Height of the object";
CM_ SG_ 212 VFC_Obj18A_HeightStdDev "Standard deviation of object height";
CM_ SG_ 212 VFC_Obj18A_PhiLeftStdDev "Standard deviation of the ACCS angle of left object(dimensionless)";
CM_ SG_ 212 VFC_Obj18A_HeadingStdDev "Standard deviation of object Heading angle";
CM_ SG_ 212 VFC_Obj18A_Measured "Indicator if the object detected is measured or predicted.";
CM_ SG_ 212 VFC_Obj18A_Heading "Heading angle of the object";
CM_ SG_ 212 VFC_Obj18A_LengthStdDev "Standard deviation of object length";
CM_ SG_ 212 VFC_Obj18A_PhiMid "Viewing angle of the ACCS middle of the object(dimensionless)";
CM_ SG_ 212 VFC_Obj18A_Width "Width of the object";
CM_ SG_ 212 VFC_Obj18A_PhiMidStdDev "Standard deviation of the ACCS middle angle of object(dimensionless)";
CM_ SG_ 212 VFC_Obj18A_PhiRight "ACCS Viewing Angle of right object edge(dimensionless)";
CM_ SG_ 212 VFC_Obj18A_VisibleView "The visible view of the detectd object";
CM_ SG_ 212 VFC_Obj18A_PhiRightStdDev "Standard deviation of the ACCS angle of right object(dimensionless)";
CM_ SG_ 212 VFC_Obj18A_PhiLeftVel "Velocity of the ACCS viewing angle of the left edge";
CM_ SG_ 212 VFC_Obj18A_PhiRightVel "Velocity of the ACCS viewing angle of the right edge";
CM_ SG_ 212 VFC_Obj18A_PhiRightVelStdDev "Standard deviation of ACCS viewing angle velocity of right object edge from ego vehicle related to camera";
CM_ SG_ 212 VFC_Obj18A_PhiLeftVelStdDev "Standard deviation of ACCS viewing angle velocity of left object edge from ego vehicle related to camera";
CM_ SG_ 212 VFC_Obj18A_PhiTop "ACCS Viewing angle of the top of the object(dimensionless)";
CM_ SG_ 212 VFC_Obj18A_PhiBottom "ACCS Viewing angle of the bottom of the object(dimensionless)";
CM_ SG_ 212 VFC_Obj18A_PhiTopStdDev "Standard deviation  of the ACCS top angle of object(dimensionless)";
CM_ SG_ 212 VFC_Obj18A_HeadOrientation "The orientation of the head of cyclists or pedestrians that are detected.";
CM_ SG_ 212 VFC_Obj18A_Type "Classification of the object";
CM_ SG_ 212 VFC_Obj18A_PhiBottomStdDev "Standard deviation of the ACCS bottom angle of object(dimensionless)";
CM_ SG_ 212 VFC_Obj18A_NormVx "Normalised object velocity in longitudinal direction.";
CM_ SG_ 212 VFC_Obj18A_NormAx "Normalised object acceleration in longitudinal direction.";
CM_ SG_ 212 VFC_Obj18A_NormAxStdDev "Standard deviation of Normalized Object Acceleration in longitudinal direction";
CM_ SG_ 212 VFC_Obj18A_ProbMovingLat "Probability of object moving laterally";
CM_ SG_ 212 VFC_Obj18A_ID "Unique Object ID";
CM_ SG_ 212 VFC_Obj18A_NormVxStdDev "Standard deviation of Normalized Object Velocity in longitudinal direction";
CM_ SG_ 212 VFC_Obj18A_ProbMovingLong "Probability of object moving longitudinally";
CM_ SG_ 213 VFC_Obj18B_TTIPC_StdDev "Inverse TTI standard deviation";
CM_ SG_ 213 VFC_Obj18B_TTIPC "Inverse TTI";
CM_ SG_ 213 VFC_Obj18B_AngLongitude "angular velocity with regarding to longitudinal direction";
CM_ SG_ 213 VFC_Obj18B_CRC "CRC - Autosar E2E Profile 5";
CM_ SG_ 213 VFC_Obj18B_AliveCtr "Alive counter - Autosar E2E Profile 5";
CM_ SG_ 213 VFC_Obj18B_BlockCtr "Protocol-Signal: Block Counter";
CM_ SG_ 213 VFC_Obj18B_ScaleChange "A scale change of of the detected object";
CM_ SG_ 213 VFC_Obj18B_ScaleChngStdDev "Standard deviation of object scale change";
CM_ SG_ 213 VFC_Obj18B_LineEdgeRightEgo "ObjLineEdgeAngle refers to the line which limits the host vehicle lane on the right side";
CM_ SG_ 213 VFC_Obj18B_LineEdgeLeftEgo "ObjLineEdgeAngle refers to the line which limits the host vehicle lane on the left side";
CM_ SG_ 213 VFC_Obj18B_CompletelyInImg "indicator if the object is completely measrued in the image";
CM_ SG_ 213 VFC_Obj18B_DirIndicator "The detected direction indicator lights";
CM_ SG_ 213 VFC_Obj18B_LineEdgeAngle "Angle between the video object's edge and the lane marking";
CM_ SG_ 213 VFC_Obj18B_BrakeLight "The number of detected lights. More confident if more lights are detected.";
CM_ SG_ 213 VFC_Obj18B_MeasSource "Bitmask for the measurement programs from which this object originates";
CM_ SG_ 213 VFC_Obj18B_Reliab "Bitmask that indicates the algorithmic paths that have detected this object";
CM_ SG_ 214 VFC_Obj19A_CRC "CRC - Autosar E2E Profile 5";
CM_ SG_ 214 VFC_Obj19A_AliveCtr "Alive counter - Autosar E2E Profile 5";
CM_ SG_ 214 VFC_Obj19A_BlockCtr "Protocol-Signal: Block-Counter";
CM_ SG_ 214 VFC_Obj19A_ProtOrderIndex "Protocol-Signal: Index to ensure same order in Tx and Rx of the objects";
CM_ SG_ 214 VFC_Obj19A_Ax "Object Acceleration in longitudinal direction";
CM_ SG_ 214 VFC_Obj19A_Vx "Object Velocity in longitudinal direction";
CM_ SG_ 214 VFC_Obj19A_Dx "Object Position in longitudinal direction";
CM_ SG_ 214 VFC_Obj19A_Dy "Object Position in lateral direction";
CM_ SG_ 214 VFC_Obj19A_Vy "Object Velocity in lateral direction";
CM_ SG_ 214 VFC_Obj19A_Ay "Object Acceleration in lateral direction";
CM_ SG_ 214 VFC_Obj19A_DyStdDev "Standard deviation of Object position in lateral direction";
CM_ SG_ 214 VFC_Obj19A_DxStdDev "Standard deviation of Object position in longitudinal direction";
CM_ SG_ 214 VFC_Obj19A_VxStdDev "Standard deviation of Object velocity in longitudinal direction";
CM_ SG_ 214 VFC_Obj19A_ExistProb "Object existence probability";
CM_ SG_ 214 VFC_Obj19A_VyStdDev "Standard deviation of Object velocity in lateral direction";
CM_ SG_ 214 VFC_Obj19A_TypeProb "Probability of the classified object type";
CM_ SG_ 214 VFC_Obj19A_AxStdDev "Standard deviation of Object acceleration in longitudinal direction";
CM_ SG_ 214 VFC_Obj19A_AyStdDev "Standard deviation of Object acceleration in lateral direction";
CM_ SG_ 214 VFC_Obj19A_PhiLeft "ACCS Viewing Angle of left object edge(dimensionless)";
CM_ SG_ 214 VFC_Obj19A_ClassifiedView "The classified view of object to be used in connection with Heading angle";
CM_ SG_ 214 VFC_Obj19A_Length "Length of the object";
CM_ SG_ 214 VFC_Obj19A_WidthStdDev "Standard deviation of object width";
CM_ SG_ 214 VFC_Obj19A_Height "Height of the object";
CM_ SG_ 214 VFC_Obj19A_HeightStdDev "Standard deviation of object height";
CM_ SG_ 214 VFC_Obj19A_PhiLeftStdDev "Standard deviation of the ACCS angle of left object(dimensionless)";
CM_ SG_ 214 VFC_Obj19A_HeadingStdDev "Standard deviation of object Heading angle";
CM_ SG_ 214 VFC_Obj19A_Measured "Indicator if the object detected is measured or predicted.";
CM_ SG_ 214 VFC_Obj19A_Heading "Heading angle of the object";
CM_ SG_ 214 VFC_Obj19A_LengthStdDev "Standard deviation of object length";
CM_ SG_ 214 VFC_Obj19A_PhiMid "Viewing angle of the ACCS middle of the object(dimensionless)";
CM_ SG_ 214 VFC_Obj19A_Width "Width of the object";
CM_ SG_ 214 VFC_Obj19A_PhiMidStdDev "Standard deviation of the ACCS middle angle of object(dimensionless)";
CM_ SG_ 214 VFC_Obj19A_PhiRight "ACCS Viewing Angle of right object edge(dimensionless)";
CM_ SG_ 214 VFC_Obj19A_VisibleView "The visible view of the detectd object";
CM_ SG_ 214 VFC_Obj19A_PhiRightStdDev "Standard deviation of the ACCS angle of right object(dimensionless)";
CM_ SG_ 214 VFC_Obj19A_PhiLeftVel "Velocity of the ACCS viewing angle of the left edge";
CM_ SG_ 214 VFC_Obj19A_PhiRightVel "Velocity of the ACCS viewing angle of the right edge";
CM_ SG_ 214 VFC_Obj19A_PhiRightVelStdDev "Standard deviation of ACCS viewing angle velocity of right object edge from ego vehicle related to camera";
CM_ SG_ 214 VFC_Obj19A_PhiLeftVelStdDev "Standard deviation of ACCS viewing angle velocity of left object edge from ego vehicle related to camera";
CM_ SG_ 214 VFC_Obj19A_PhiTop "ACCS Viewing angle of the top of the object(dimensionless)";
CM_ SG_ 214 VFC_Obj19A_PhiBottom "ACCS Viewing angle of the bottom of the object(dimensionless)";
CM_ SG_ 214 VFC_Obj19A_PhiTopStdDev "Standard deviation  of the ACCS top angle of object(dimensionless)";
CM_ SG_ 214 VFC_Obj19A_HeadOrientation "The orientation of the head of cyclists or pedestrians that are detected.";
CM_ SG_ 214 VFC_Obj19A_Type "Classification of the object";
CM_ SG_ 214 VFC_Obj19A_PhiBottomStdDev "Standard deviation of the ACCS bottom angle of object(dimensionless)";
CM_ SG_ 214 VFC_Obj19A_NormVx "Normalised object velocity in longitudinal direction.";
CM_ SG_ 214 VFC_Obj19A_NormAx "Normalised object acceleration in longitudinal direction.";
CM_ SG_ 214 VFC_Obj19A_NormAxStdDev "Standard deviation of Normalized Object Acceleration in longitudinal direction";
CM_ SG_ 214 VFC_Obj19A_ProbMovingLat "Probability of object moving laterally";
CM_ SG_ 214 VFC_Obj19A_ID "Unique Object ID";
CM_ SG_ 214 VFC_Obj19A_NormVxStdDev "Standard deviation of Normalized Object Velocity in longitudinal direction";
CM_ SG_ 214 VFC_Obj19A_ProbMovingLong "Probability of object moving longitudinally";
CM_ SG_ 215 VFC_Obj19B_TTIPC_StdDev "Inverse TTI standard deviation";
CM_ SG_ 215 VFC_Obj19B_TTIPC "Inverse TTI";
CM_ SG_ 215 VFC_Obj19B_AngLongitude "angular velocity with regarding to longitudinal direction";
CM_ SG_ 215 VFC_Obj19B_CRC "CRC - Autosar E2E Profile 5";
CM_ SG_ 215 VFC_Obj19B_AliveCtr "Alive counter - Autosar E2E Profile 5";
CM_ SG_ 215 VFC_Obj19B_BlockCtr "Protocol-Signal: Block Counter";
CM_ SG_ 215 VFC_Obj19B_ScaleChange "A scale change of of the detected object";
CM_ SG_ 215 VFC_Obj19B_ScaleChngStdDev "Standard deviation of object scale change";
CM_ SG_ 215 VFC_Obj19B_LineEdgeRightEgo "ObjLineEdgeAngle refers to the line which limits the host vehicle lane on the right side";
CM_ SG_ 215 VFC_Obj19B_LineEdgeLeftEgo "ObjLineEdgeAngle refers to the line which limits the host vehicle lane on the left side";
CM_ SG_ 215 VFC_Obj19B_CompletelyInImg "indicator if the object is completely measrued in the image";
CM_ SG_ 215 VFC_Obj19B_DirIndicator "The detected direction indicator lights";
CM_ SG_ 215 VFC_Obj19B_LineEdgeAngle "Angle between the video object's edge and the lane marking";
CM_ SG_ 215 VFC_Obj19B_BrakeLight "The number of detected lights. More confident if more lights are detected.";
CM_ SG_ 215 VFC_Obj19B_MeasSource "Bitmask for the measurement programs from which this object originates";
CM_ SG_ 215 VFC_Obj19B_Reliab "Bitmask that indicates the algorithmic paths that have detected this object";
CM_ SG_ 128 VFC_LineHdr_AUTOSARTStamp "Time stamp when Clothoids measurement, in autosar time sync mode";
CM_ SG_ 128 VFC_LineHdr_FrameNo "The frame number that the data belongs to";
CM_ SG_ 128 VFC_LineHdr_CRC "CRC - Autosar E2E Profile 5";
CM_ SG_ 128 VFC_LineHdr_AliveCtr "Alive counter - Autosar E2E Profile 5";
CM_ SG_ 128 VFC_LineHdr_BlockCounter "Protocol-Signal:Blockcounter";
CM_ SG_ 128 VFC_LineHdr_Report "Bitmask for Errors if PEPSI was not executed";
CM_ SG_ 128 VFC_LineHdr_LineCount "Number of Lines to be send (max 15)";
CM_ SG_ 128 VFC_LineHdr_PEPSIRuntime "Last runtime of the PEPSI Algorithm. As PEPSI does runtime management, this can be used as an indicator for the quality of the results.";
CM_ SG_ 128 VFC_LineHdr_TimeStamp "TimeStamp of Clothoids when lines are measured, for 1R1V sensor set";
CM_ SG_ 128 VFC_LineHdr_Blindness "Blindness Indicator for Lines";
CM_ SG_ 128 VFC_LineHdr_State "Informs the system of the current state of the camera";
CM_ SG_ 129 VFC_Line01_CRC "CRC - Autosar E2E Profile 5";
CM_ SG_ 129 VFC_Line01_AliveCtr "Alive counter - Autosar E2E Profile 5";
CM_ SG_ 129 VFC_Line01_BlockCounter "Protocol-Signal:Blockcounter";
CM_ SG_ 129 VFC_Line01_ProtOrderIndex "Protocol-Signal: Index to ensure same order in Tx and Rx of the clothoids";
CM_ SG_ 129 VFC_Line01_LineID "Object ID is used to order the Objects in line";
CM_ SG_ 129 VFC_Line01_LaneRelation "Indicating its position relative to the ego lane";
CM_ SG_ 129 VFC_Line01_ExistProb "Confidence for this line";
CM_ SG_ 129 VFC_Line01_DxStart "Longitudinal start point of the line, also called dxStart";
CM_ SG_ 129 VFC_Line01_ColorClass "The color of the line";
CM_ SG_ 129 VFC_Line01_DxEnd "Longitudinal range of the line, also called dxEnd";
CM_ SG_ 129 VFC_Line01_HeadingAngle "Heading angle, difference in yaw angle between vehicle heading and Line";
CM_ SG_ 129 VFC_Line01_Dy "Dy at position of DxStart  (not always x=0, because of high values for 2nd segment)";
CM_ SG_ 129 VFC_Line01_CurvChange "Currvature change or alteration of the Line, also called kappaDt";
CM_ SG_ 129 VFC_Line01_Curv "Curvature of the Line, also called kappa";
CM_ SG_ 129 VFC_Line01_MeasureType "Indicates if Line was measured, interpolated or inferred (virtual line)";
CM_ SG_ 129 VFC_Line01_LineWidth "Width of the line";
CM_ SG_ 129 VFC_Line01_CourseDeviation "Confidence measure quantifying a weighted deviation between course/path and the predicted lane";
CM_ SG_ 129 VFC_Line01_Type "Type of the Line";
CM_ SG_ 129 VFC_Line01_DyStdDevDxEnd "Standard deviation of the lateral offset, at point of DxEnd";
CM_ SG_ 129 VFC_Line01_HypoConfidence "multiple hypothesis info. from Video (ambiguity ID)";
CM_ SG_ 129 VFC_Line01_prevID "when in multi-segment, prevID is used to show that the current line ID is from which previous ID";
CM_ SG_ 129 VFC_Line01_nextID "when in multi-segment, nextID is used to show that which line ID is next to the current line ID";
CM_ SG_ 129 VFC_Line01_DyStdDevDxStart "Standard deviation of the lateral offset, at point of DxStart";
CM_ SG_ 129 VFC_Line01_TypeProb "Confidence measure for Type classification";
CM_ SG_ 129 VFC_Line01_DyStdDevDxMid "Standard deviation of the lateral offset, at point of DxMid, DyStdDevDxMid (dxMid = (dxEnd-dxStart)/2 )";
CM_ SG_ 130 VFC_Line02_CRC "CRC - Autosar E2E Profile 5";
CM_ SG_ 130 VFC_Line02_AliveCtr "Alive counter - Autosar E2E Profile 5";
CM_ SG_ 130 VFC_Line02_BlockCounter "Protocol-Signal:Blockcounter";
CM_ SG_ 130 VFC_Line02_ProtOrderIndex "Protocol-Signal: Index to ensure same order in Tx and Rx of the clothoids";
CM_ SG_ 130 VFC_Line02_LineID "Object ID is used to order the Objects in line";
CM_ SG_ 130 VFC_Line02_LaneRelation "Indicating its position relative to the ego lane";
CM_ SG_ 130 VFC_Line02_ExistProb "Confidence for this line";
CM_ SG_ 130 VFC_Line02_DxStart "Longitudinal start point of the line, also called dxStart";
CM_ SG_ 130 VFC_Line02_ColorClass "The color of the line";
CM_ SG_ 130 VFC_Line02_DxEnd "Longitudinal range of the line, also called dxEnd";
CM_ SG_ 130 VFC_Line02_HeadingAngle "Heading angle, difference in yaw angle between vehicle heading and Line";
CM_ SG_ 130 VFC_Line02_Dy "Dy at position of DxStart  (not always x=0, because of high values for 2nd segment)";
CM_ SG_ 130 VFC_Line02_CurvChange "Currvature change or alteration of the Line, also called kappaDt";
CM_ SG_ 130 VFC_Line02_Curv "Curvature of the Line, also called kappa";
CM_ SG_ 130 VFC_Line02_MeasureType "Indicates if Line was measured, interpolated or inferred (virtual line)";
CM_ SG_ 130 VFC_Line02_LineWidth "Width of the line";
CM_ SG_ 130 VFC_Line02_CourseDeviation "Confidence measure quantifying a weighted deviation between course/path and the predicted lane";
CM_ SG_ 130 VFC_Line02_Type "Type of the Line";
CM_ SG_ 130 VFC_Line02_DyStdDevDxEnd "Standard deviation of the lateral offset, at point of DxEnd";
CM_ SG_ 130 VFC_Line02_HypoConfidence "multiple hypothesis info. from Video (ambiguity ID)";
CM_ SG_ 130 VFC_Line02_prevID "when in multi-segment, prevID is used to show that the current line ID is from which previous ID";
CM_ SG_ 130 VFC_Line02_nextID "when in multi-segment, nextID is used to show that which line ID is next to the current line ID";
CM_ SG_ 130 VFC_Line02_DyStdDevDxStart "Standard deviation of the lateral offset, at point of DxStart";
CM_ SG_ 130 VFC_Line02_TypeProb "Confidence measure for Type classification";
CM_ SG_ 130 VFC_Line02_DyStdDevDxMid "Standard deviation of the lateral offset, at point of DxMid, DyStdDevDxMid (dxMid = (dxEnd-dxStart)/2 )";
CM_ SG_ 131 VFC_Line03_CRC "CRC - Autosar E2E Profile 5";
CM_ SG_ 131 VFC_Line03_AliveCtr "Alive counter - Autosar E2E Profile 5";
CM_ SG_ 131 VFC_Line03_BlockCounter "Protocol-Signal:Blockcounter";
CM_ SG_ 131 VFC_Line03_ProtOrderIndex "Protocol-Signal: Index to ensure same order in Tx and Rx of the clothoids";
CM_ SG_ 131 VFC_Line03_LineID "Object ID is used to order the Objects in line";
CM_ SG_ 131 VFC_Line03_LaneRelation "Indicating its position relative to the ego lane";
CM_ SG_ 131 VFC_Line03_ExistProb "Confidence for this line";
CM_ SG_ 131 VFC_Line03_DxStart "Longitudinal start point of the line, also called dxStart";
CM_ SG_ 131 VFC_Line03_ColorClass "The color of the line";
CM_ SG_ 131 VFC_Line03_DxEnd "Longitudinal range of the line, also called dxEnd";
CM_ SG_ 131 VFC_Line03_HeadingAngle "Heading angle, difference in yaw angle between vehicle heading and Line";
CM_ SG_ 131 VFC_Line03_Dy "Dy at position of DxStart  (not always x=0, because of high values for 2nd segment)";
CM_ SG_ 131 VFC_Line03_CurvChange "Currvature change or alteration of the Line, also called kappaDt";
CM_ SG_ 131 VFC_Line03_Curv "Curvature of the Line, also called kappa";
CM_ SG_ 131 VFC_Line03_MeasureType "Indicates if Line was measured, interpolated or inferred (virtual line)";
CM_ SG_ 131 VFC_Line03_LineWidth "Width of the line";
CM_ SG_ 131 VFC_Line03_CourseDeviation "Confidence measure quantifying a weighted deviation between course/path and the predicted lane";
CM_ SG_ 131 VFC_Line03_Type "Type of the Line";
CM_ SG_ 131 VFC_Line03_DyStdDevDxEnd "Standard deviation of the lateral offset, at point of DxEnd";
CM_ SG_ 131 VFC_Line03_HypoConfidence "multiple hypothesis info. from Video (ambiguity ID)";
CM_ SG_ 131 VFC_Line03_prevID "when in multi-segment, prevID is used to show that the current line ID is from which previous ID";
CM_ SG_ 131 VFC_Line03_nextID "when in multi-segment, nextID is used to show that which line ID is next to the current line ID";
CM_ SG_ 131 VFC_Line03_DyStdDevDxStart "Standard deviation of the lateral offset, at point of DxStart";
CM_ SG_ 131 VFC_Line03_TypeProb "Confidence measure for Type classification";
CM_ SG_ 131 VFC_Line03_DyStdDevDxMid "Standard deviation of the lateral offset, at point of DxMid, DyStdDevDxMid (dxMid = (dxEnd-dxStart)/2 )";
CM_ SG_ 132 VFC_Line04_CRC "CRC - Autosar E2E Profile 5";
CM_ SG_ 132 VFC_Line04_AliveCtr "Alive counter - Autosar E2E Profile 5";
CM_ SG_ 132 VFC_Line04_BlockCounter "Protocol-Signal:Blockcounter";
CM_ SG_ 132 VFC_Line04_ProtOrderIndex "Protocol-Signal: Index to ensure same order in Tx and Rx of the clothoids";
CM_ SG_ 132 VFC_Line04_LineID "Object ID is used to order the Objects in line";
CM_ SG_ 132 VFC_Line04_LaneRelation "Indicating its position relative to the ego lane";
CM_ SG_ 132 VFC_Line04_ExistProb "Confidence for this line";
CM_ SG_ 132 VFC_Line04_DxStart "Longitudinal start point of the line, also called dxStart";
CM_ SG_ 132 VFC_Line04_ColorClass "The color of the line";
CM_ SG_ 132 VFC_Line04_DxEnd "Longitudinal range of the line, also called dxEnd";
CM_ SG_ 132 VFC_Line04_HeadingAngle "Heading angle, difference in yaw angle between vehicle heading and Line";
CM_ SG_ 132 VFC_Line04_Dy "Dy at position of DxStart  (not always x=0, because of high values for 2nd segment)";
CM_ SG_ 132 VFC_Line04_CurvChange "Currvature change or alteration of the Line, also called kappaDt";
CM_ SG_ 132 VFC_Line04_Curv "Curvature of the Line, also called kappa";
CM_ SG_ 132 VFC_Line04_MeasureType "Indicates if Line was measured, interpolated or inferred (virtual line)";
CM_ SG_ 132 VFC_Line04_LineWidth "Width of the line";
CM_ SG_ 132 VFC_Line04_CourseDeviation "Confidence measure quantifying a weighted deviation between course/path and the predicted lane";
CM_ SG_ 132 VFC_Line04_Type "Type of the Line";
CM_ SG_ 132 VFC_Line04_DyStdDevDxEnd "Standard deviation of the lateral offset, at point of DxEnd";
CM_ SG_ 132 VFC_Line04_HypoConfidence "multiple hypothesis info. from Video (ambiguity ID)";
CM_ SG_ 132 VFC_Line04_prevID "when in multi-segment, prevID is used to show that the current line ID is from which previous ID";
CM_ SG_ 132 VFC_Line04_nextID "when in multi-segment, nextID is used to show that which line ID is next to the current line ID";
CM_ SG_ 132 VFC_Line04_DyStdDevDxStart "Standard deviation of the lateral offset, at point of DxStart";
CM_ SG_ 132 VFC_Line04_TypeProb "Confidence measure for Type classification";
CM_ SG_ 132 VFC_Line04_DyStdDevDxMid "Standard deviation of the lateral offset, at point of DxMid, DyStdDevDxMid (dxMid = (dxEnd-dxStart)/2 )";
CM_ SG_ 133 VFC_Line05_CRC "CRC - Autosar E2E Profile 5";
CM_ SG_ 133 VFC_Line05_AliveCtr "Alive counter - Autosar E2E Profile 5";
CM_ SG_ 133 VFC_Line05_BlockCounter "Protocol-Signal:Blockcounter";
CM_ SG_ 133 VFC_Line05_ProtOrderIndex "Protocol-Signal: Index to ensure same order in Tx and Rx of the clothoids";
CM_ SG_ 133 VFC_Line05_LineID "Object ID is used to order the Objects in line";
CM_ SG_ 133 VFC_Line05_LaneRelation "Indicating its position relative to the ego lane";
CM_ SG_ 133 VFC_Line05_ExistProb "Confidence for this line";
CM_ SG_ 133 VFC_Line05_DxStart "Longitudinal start point of the line, also called dxStart";
CM_ SG_ 133 VFC_Line05_ColorClass "The color of the line";
CM_ SG_ 133 VFC_Line05_DxEnd "Longitudinal range of the line, also called dxEnd";
CM_ SG_ 133 VFC_Line05_HeadingAngle "Heading angle, difference in yaw angle between vehicle heading and Line";
CM_ SG_ 133 VFC_Line05_Dy "Dy at position of DxStart  (not always x=0, because of high values for 2nd segment)";
CM_ SG_ 133 VFC_Line05_CurvChange "Currvature change or alteration of the Line, also called kappaDt";
CM_ SG_ 133 VFC_Line05_Curv "Curvature of the Line, also called kappa";
CM_ SG_ 133 VFC_Line05_MeasureType "Indicates if Line was measured, interpolated or inferred (virtual line)";
CM_ SG_ 133 VFC_Line05_LineWidth "Width of the line";
CM_ SG_ 133 VFC_Line05_CourseDeviation "Confidence measure quantifying a weighted deviation between course/path and the predicted lane";
CM_ SG_ 133 VFC_Line05_Type "Type of the Line";
CM_ SG_ 133 VFC_Line05_DyStdDevDxEnd "Standard deviation of the lateral offset, at point of DxEnd";
CM_ SG_ 133 VFC_Line05_HypoConfidence "multiple hypothesis info. from Video (ambiguity ID)";
CM_ SG_ 133 VFC_Line05_prevID "when in multi-segment, prevID is used to show that the current line ID is from which previous ID";
CM_ SG_ 133 VFC_Line05_nextID "when in multi-segment, nextID is used to show that which line ID is next to the current line ID";
CM_ SG_ 133 VFC_Line05_DyStdDevDxStart "Standard deviation of the lateral offset, at point of DxStart";
CM_ SG_ 133 VFC_Line05_TypeProb "Confidence measure for Type classification";
CM_ SG_ 133 VFC_Line05_DyStdDevDxMid "Standard deviation of the lateral offset, at point of DxMid, DyStdDevDxMid (dxMid = (dxEnd-dxStart)/2 )";
CM_ SG_ 134 VFC_Line06_CRC "CRC - Autosar E2E Profile 5";
CM_ SG_ 134 VFC_Line06_AliveCtr "Alive counter - Autosar E2E Profile 5";
CM_ SG_ 134 VFC_Line06_BlockCounter "Protocol-Signal:Blockcounter";
CM_ SG_ 134 VFC_Line06_ProtOrderIndex "Protocol-Signal: Index to ensure same order in Tx and Rx of the clothoids";
CM_ SG_ 134 VFC_Line06_LineID "Object ID is used to order the Objects in line";
CM_ SG_ 134 VFC_Line06_LaneRelation "Indicating its position relative to the ego lane";
CM_ SG_ 134 VFC_Line06_ExistProb "Confidence for this line";
CM_ SG_ 134 VFC_Line06_DxStart "Longitudinal start point of the line, also called dxStart";
CM_ SG_ 134 VFC_Line06_ColorClass "The color of the line";
CM_ SG_ 134 VFC_Line06_DxEnd "Longitudinal range of the line, also called dxEnd";
CM_ SG_ 134 VFC_Line06_HeadingAngle "Heading angle, difference in yaw angle between vehicle heading and Line";
CM_ SG_ 134 VFC_Line06_Dy "Dy at position of DxStart  (not always x=0, because of high values for 2nd segment)";
CM_ SG_ 134 VFC_Line06_CurvChange "Currvature change or alteration of the Line, also called kappaDt";
CM_ SG_ 134 VFC_Line06_Curv "Curvature of the Line, also called kappa";
CM_ SG_ 134 VFC_Line06_MeasureType "Indicates if Line was measured, interpolated or inferred (virtual line)";
CM_ SG_ 134 VFC_Line06_LineWidth "Width of the line";
CM_ SG_ 134 VFC_Line06_CourseDeviation "Confidence measure quantifying a weighted deviation between course/path and the predicted lane";
CM_ SG_ 134 VFC_Line06_Type "Type of the Line";
CM_ SG_ 134 VFC_Line06_DyStdDevDxEnd "Standard deviation of the lateral offset, at point of DxEnd";
CM_ SG_ 134 VFC_Line06_HypoConfidence "multiple hypothesis info. from Video (ambiguity ID)";
CM_ SG_ 134 VFC_Line06_prevID "when in multi-segment, prevID is used to show that the current line ID is from which previous ID";
CM_ SG_ 134 VFC_Line06_nextID "when in multi-segment, nextID is used to show that which line ID is next to the current line ID";
CM_ SG_ 134 VFC_Line06_DyStdDevDxStart "Standard deviation of the lateral offset, at point of DxStart";
CM_ SG_ 134 VFC_Line06_TypeProb "Confidence measure for Type classification";
CM_ SG_ 134 VFC_Line06_DyStdDevDxMid "Standard deviation of the lateral offset, at point of DxMid, DyStdDevDxMid (dxMid = (dxEnd-dxStart)/2 )";
CM_ SG_ 135 VFC_Line07_CRC "CRC - Autosar E2E Profile 5";
CM_ SG_ 135 VFC_Line07_AliveCtr "Alive counter - Autosar E2E Profile 5";
CM_ SG_ 135 VFC_Line07_BlockCounter "Protocol-Signal:Blockcounter";
CM_ SG_ 135 VFC_Line07_ProtOrderIndex "Protocol-Signal: Index to ensure same order in Tx and Rx of the clothoids";
CM_ SG_ 135 VFC_Line07_LineID "Object ID is used to order the Objects in line";
CM_ SG_ 135 VFC_Line07_LaneRelation "Indicating its position relative to the ego lane";
CM_ SG_ 135 VFC_Line07_ExistProb "Confidence for this line";
CM_ SG_ 135 VFC_Line07_DxStart "Longitudinal start point of the line, also called dxStart";
CM_ SG_ 135 VFC_Line07_ColorClass "The color of the line";
CM_ SG_ 135 VFC_Line07_DxEnd "Longitudinal range of the line, also called dxEnd";
CM_ SG_ 135 VFC_Line07_HeadingAngle "Heading angle, difference in yaw angle between vehicle heading and Line";
CM_ SG_ 135 VFC_Line07_Dy "Dy at position of DxStart  (not always x=0, because of high values for 2nd segment)";
CM_ SG_ 135 VFC_Line07_CurvChange "Currvature change or alteration of the Line, also called kappaDt";
CM_ SG_ 135 VFC_Line07_Curv "Curvature of the Line, also called kappa";
CM_ SG_ 135 VFC_Line07_MeasureType "Indicates if Line was measured, interpolated or inferred (virtual line)";
CM_ SG_ 135 VFC_Line07_LineWidth "Width of the line";
CM_ SG_ 135 VFC_Line07_CourseDeviation "Confidence measure quantifying a weighted deviation between course/path and the predicted lane";
CM_ SG_ 135 VFC_Line07_Type "Type of the Line";
CM_ SG_ 135 VFC_Line07_DyStdDevDxEnd "Standard deviation of the lateral offset, at point of DxEnd";
CM_ SG_ 135 VFC_Line07_HypoConfidence "multiple hypothesis info. from Video (ambiguity ID)";
CM_ SG_ 135 VFC_Line07_prevID "when in multi-segment, prevID is used to show that the current line ID is from which previous ID";
CM_ SG_ 135 VFC_Line07_nextID "when in multi-segment, nextID is used to show that which line ID is next to the current line ID";
CM_ SG_ 135 VFC_Line07_DyStdDevDxStart "Standard deviation of the lateral offset, at point of DxStart";
CM_ SG_ 135 VFC_Line07_TypeProb "Confidence measure for Type classification";
CM_ SG_ 135 VFC_Line07_DyStdDevDxMid "Standard deviation of the lateral offset, at point of DxMid, DyStdDevDxMid (dxMid = (dxEnd-dxStart)/2 )";
CM_ SG_ 136 VFC_Line08_CRC "CRC - Autosar E2E Profile 5";
CM_ SG_ 136 VFC_Line08_AliveCtr "Alive counter - Autosar E2E Profile 5";
CM_ SG_ 136 VFC_Line08_BlockCounter "Protocol-Signal:Blockcounter";
CM_ SG_ 136 VFC_Line08_ProtOrderIndex "Protocol-Signal: Index to ensure same order in Tx and Rx of the clothoids";
CM_ SG_ 136 VFC_Line08_LineID "Object ID is used to order the Objects in line";
CM_ SG_ 136 VFC_Line08_LaneRelation "Indicating its position relative to the ego lane";
CM_ SG_ 136 VFC_Line08_ExistProb "Confidence for this line";
CM_ SG_ 136 VFC_Line08_DxStart "Longitudinal start point of the line, also called dxStart";
CM_ SG_ 136 VFC_Line08_ColorClass "The color of the line";
CM_ SG_ 136 VFC_Line08_DxEnd "Longitudinal range of the line, also called dxEnd";
CM_ SG_ 136 VFC_Line08_HeadingAngle "Heading angle, difference in yaw angle between vehicle heading and Line";
CM_ SG_ 136 VFC_Line08_Dy "Dy at position of DxStart  (not always x=0, because of high values for 2nd segment)";
CM_ SG_ 136 VFC_Line08_CurvChange "Currvature change or alteration of the Line, also called kappaDt";
CM_ SG_ 136 VFC_Line08_Curv "Curvature of the Line, also called kappa";
CM_ SG_ 136 VFC_Line08_MeasureType "Indicates if Line was measured, interpolated or inferred (virtual line)";
CM_ SG_ 136 VFC_Line08_LineWidth "Width of the line";
CM_ SG_ 136 VFC_Line08_CourseDeviation "Confidence measure quantifying a weighted deviation between course/path and the predicted lane";
CM_ SG_ 136 VFC_Line08_Type "Type of the Line";
CM_ SG_ 136 VFC_Line08_DyStdDevDxEnd "Standard deviation of the lateral offset, at point of DxEnd";
CM_ SG_ 136 VFC_Line08_HypoConfidence "multiple hypothesis info. from Video (ambiguity ID)";
CM_ SG_ 136 VFC_Line08_prevID "when in multi-segment, prevID is used to show that the current line ID is from which previous ID";
CM_ SG_ 136 VFC_Line08_nextID "when in multi-segment, nextID is used to show that which line ID is next to the current line ID";
CM_ SG_ 136 VFC_Line08_DyStdDevDxStart "Standard deviation of the lateral offset, at point of DxStart";
CM_ SG_ 136 VFC_Line08_TypeProb "Confidence measure for Type classification";
CM_ SG_ 136 VFC_Line08_DyStdDevDxMid "Standard deviation of the lateral offset, at point of DxMid, DyStdDevDxMid (dxMid = (dxEnd-dxStart)/2 )";
CM_ BO_ 930 "Speed limit value, from video to DASy";
CM_ SG_ 930 VFC_TSR_ASL_CRC "CRC - Autosar E2E Profile 5";
CM_ SG_ 930 VFC_TSR_ASL_AliveCtr "Alive counter - Autosar E2E Profile 5";
CM_ SG_ 930 VFC_ADAS_ModSts_SLA "SLA mode status, from BJEV ASL spec V0.8";
CM_ SG_ 930 VFC_ADAS_SpdLim_SLA "Speed limit value, from BJEV ASL spec V0.8";
CM_ SG_ 930 VFC_ADAS_SpdLimUnit_SLA "Speed limit unit, from BJEV ASL spec V0.8";
BA_DEF_ BO_  "GenMsgSendType" ENUM  "cyclic","NoMsgSendType","IfActive","Event","CA","CE";
BA_DEF_ BO_  "GenMsgCycleTime" INT 0 0;
BA_DEF_ SG_  "GenSigSendType" ENUM  "cyclic","OnChange","OnWrite","IfActive","OnChangeWithRepetition","OnWriteWithRepetition","IfActiveWithRepetition","CA","CE","Event";
BA_DEF_ SG_  "GenSigStartValue" INT 0 0;
BA_DEF_ BO_  "CANFD_BRS" ENUM  "0","1";
BA_DEF_ BO_  "VFrameFormat" ENUM  "StandardCAN","ExtendedCAN","reserved","reserved","reserved","reserved","reserved","reserved","reserved","reserved","reserved","reserved","reserved","reserved","StandardCAN_FD","ExtendedCAN_FD";
BA_DEF_ BO_  "GenMsgILSupport" ENUM  "No","Yes";
BA_DEF_DEF_  "GenMsgSendType" "cyclic";
BA_DEF_DEF_  "GenMsgCycleTime" 0;
BA_DEF_DEF_  "GenSigSendType" "cyclic";
BA_DEF_DEF_  "GenSigStartValue" 0;
BA_DEF_DEF_  "CANFD_BRS" "1";
BA_DEF_DEF_  "VFrameFormat" "";
BA_DEF_DEF_  "GenMsgILSupport" "Yes";
BA_ "GenMsgSendType" BO_ 206 3;
BA_ "VFrameFormat" BO_ 206 14;
BA_ "GenMsgSendType" BO_ 207 3;
BA_ "VFrameFormat" BO_ 207 14;
BA_ "GenMsgSendType" BO_ 208 3;
BA_ "VFrameFormat" BO_ 208 14;
BA_ "GenMsgSendType" BO_ 209 3;
BA_ "VFrameFormat" BO_ 209 14;
BA_ "GenMsgSendType" BO_ 210 3;
BA_ "VFrameFormat" BO_ 210 14;
BA_ "GenMsgSendType" BO_ 211 3;
BA_ "VFrameFormat" BO_ 211 14;
BA_ "GenMsgSendType" BO_ 212 3;
BA_ "VFrameFormat" BO_ 212 14;
BA_ "GenMsgSendType" BO_ 213 3;
BA_ "VFrameFormat" BO_ 213 14;
BA_ "GenMsgSendType" BO_ 214 3;
BA_ "VFrameFormat" BO_ 214 14;
BA_ "GenMsgSendType" BO_ 215 3;
BA_ "VFrameFormat" BO_ 215 14;
BA_ "GenMsgSendType" BO_ 128 3;
BA_ "VFrameFormat" BO_ 128 14;
BA_ "GenMsgSendType" BO_ 129 3;
BA_ "VFrameFormat" BO_ 129 14;
BA_ "GenMsgSendType" BO_ 130 3;
BA_ "VFrameFormat" BO_ 130 14;
BA_ "GenMsgSendType" BO_ 131 3;
BA_ "VFrameFormat" BO_ 131 14;
BA_ "GenMsgSendType" BO_ 132 3;
BA_ "VFrameFormat" BO_ 132 14;
BA_ "GenMsgSendType" BO_ 133 3;
BA_ "VFrameFormat" BO_ 133 14;
BA_ "GenMsgSendType" BO_ 134 3;
BA_ "VFrameFormat" BO_ 134 14;
BA_ "GenMsgSendType" BO_ 135 3;
BA_ "VFrameFormat" BO_ 135 14;
BA_ "GenMsgSendType" BO_ 136 3;
BA_ "VFrameFormat" BO_ 136 14;
BA_ "GenMsgCycleTime" BO_ 930 100;
BA_ "VFrameFormat" BO_ 930 14;
BA_ "GenSigSendType" SG_ 206 VFC_Obj15A_CRC 9;
BA_ "GenSigSendType" SG_ 206 VFC_Obj15A_AliveCtr 9;
BA_ "GenSigSendType" SG_ 206 VFC_Obj15A_BlockCtr 9;
BA_ "GenSigSendType" SG_ 206 VFC_Obj15A_ProtOrderIndex 9;
BA_ "GenSigSendType" SG_ 206 VFC_Obj15A_Ax 9;
BA_ "GenSigStartValue" SG_ 206 VFC_Obj15A_Ax 160;
BA_ "GenSigSendType" SG_ 206 VFC_Obj15A_Vx 9;
BA_ "GenSigStartValue" SG_ 206 VFC_Obj15A_Vx 1540;
BA_ "GenSigSendType" SG_ 206 VFC_Obj15A_Dx 9;
BA_ "GenSigSendType" SG_ 206 VFC_Obj15A_Dy 9;
BA_ "GenSigStartValue" SG_ 206 VFC_Obj15A_Dy 8000;
BA_ "GenSigSendType" SG_ 206 VFC_Obj15A_Vy 9;
BA_ "GenSigStartValue" SG_ 206 VFC_Obj15A_Vy 500;
BA_ "GenSigSendType" SG_ 206 VFC_Obj15A_Ay 9;
BA_ "GenSigStartValue" SG_ 206 VFC_Obj15A_Ay 120;
BA_ "GenSigSendType" SG_ 206 VFC_Obj15A_DyStdDev 9;
BA_ "GenSigSendType" SG_ 206 VFC_Obj15A_DxStdDev 9;
BA_ "GenSigSendType" SG_ 206 VFC_Obj15A_VxStdDev 9;
BA_ "GenSigSendType" SG_ 206 VFC_Obj15A_ExistProb 9;
BA_ "GenSigSendType" SG_ 206 VFC_Obj15A_VyStdDev 9;
BA_ "GenSigSendType" SG_ 206 VFC_Obj15A_TypeProb 9;
BA_ "GenSigSendType" SG_ 206 VFC_Obj15A_AxStdDev 9;
BA_ "GenSigSendType" SG_ 206 VFC_Obj15A_AyStdDev 9;
BA_ "GenSigSendType" SG_ 206 VFC_Obj15A_PhiLeft 9;
BA_ "GenSigStartValue" SG_ 206 VFC_Obj15A_PhiLeft 4000;
BA_ "GenSigSendType" SG_ 206 VFC_Obj15A_ClassifiedView 9;
BA_ "GenSigSendType" SG_ 206 VFC_Obj15A_Length 9;
BA_ "GenSigSendType" SG_ 206 VFC_Obj15A_WidthStdDev 9;
BA_ "GenSigSendType" SG_ 206 VFC_Obj15A_Height 9;
BA_ "GenSigSendType" SG_ 206 VFC_Obj15A_HeightStdDev 9;
BA_ "GenSigSendType" SG_ 206 VFC_Obj15A_PhiLeftStdDev 9;
BA_ "GenSigSendType" SG_ 206 VFC_Obj15A_HeadingStdDev 9;
BA_ "GenSigSendType" SG_ 206 VFC_Obj15A_Measured 9;
BA_ "GenSigSendType" SG_ 206 VFC_Obj15A_Heading 9;
BA_ "GenSigStartValue" SG_ 206 VFC_Obj15A_Heading 157;
BA_ "GenSigSendType" SG_ 206 VFC_Obj15A_LengthStdDev 9;
BA_ "GenSigSendType" SG_ 206 VFC_Obj15A_PhiMid 9;
BA_ "GenSigStartValue" SG_ 206 VFC_Obj15A_PhiMid 4000;
BA_ "GenSigSendType" SG_ 206 VFC_Obj15A_Width 9;
BA_ "GenSigSendType" SG_ 206 VFC_Obj15A_PhiMidStdDev 9;
BA_ "GenSigSendType" SG_ 206 VFC_Obj15A_PhiRight 9;
BA_ "GenSigStartValue" SG_ 206 VFC_Obj15A_PhiRight 4000;
BA_ "GenSigSendType" SG_ 206 VFC_Obj15A_VisibleView 9;
BA_ "GenSigSendType" SG_ 206 VFC_Obj15A_PhiRightStdDev 9;
BA_ "GenSigSendType" SG_ 206 VFC_Obj15A_PhiLeftVel 9;
BA_ "GenSigStartValue" SG_ 206 VFC_Obj15A_PhiLeftVel 4000;
BA_ "GenSigSendType" SG_ 206 VFC_Obj15A_PhiRightVel 9;
BA_ "GenSigStartValue" SG_ 206 VFC_Obj15A_PhiRightVel 4000;
BA_ "GenSigSendType" SG_ 206 VFC_Obj15A_PhiRightVelStdDev 9;
BA_ "GenSigSendType" SG_ 206 VFC_Obj15A_PhiLeftVelStdDev 9;
BA_ "GenSigSendType" SG_ 206 VFC_Obj15A_PhiTop 9;
BA_ "GenSigStartValue" SG_ 206 VFC_Obj15A_PhiTop 1600;
BA_ "GenSigSendType" SG_ 206 VFC_Obj15A_PhiBottom 9;
BA_ "GenSigStartValue" SG_ 206 VFC_Obj15A_PhiBottom 1600;
BA_ "GenSigSendType" SG_ 206 VFC_Obj15A_PhiTopStdDev 9;
BA_ "GenSigSendType" SG_ 206 VFC_Obj15A_HeadOrientation 9;
BA_ "GenSigSendType" SG_ 206 VFC_Obj15A_Type 9;
BA_ "GenSigSendType" SG_ 206 VFC_Obj15A_PhiBottomStdDev 9;
BA_ "GenSigSendType" SG_ 206 VFC_Obj15A_NormVx 9;
BA_ "GenSigStartValue" SG_ 206 VFC_Obj15A_NormVx 40000;
BA_ "GenSigSendType" SG_ 206 VFC_Obj15A_NormAx 9;
BA_ "GenSigStartValue" SG_ 206 VFC_Obj15A_NormAx 5000;
BA_ "GenSigSendType" SG_ 206 VFC_Obj15A_NormAxStdDev 9;
BA_ "GenSigSendType" SG_ 206 VFC_Obj15A_ProbMovingLat 9;
BA_ "GenSigSendType" SG_ 206 VFC_Obj15A_ID 9;
BA_ "GenSigSendType" SG_ 206 VFC_Obj15A_NormVxStdDev 9;
BA_ "GenSigSendType" SG_ 206 VFC_Obj15A_ProbMovingLong 9;
BA_ "GenSigSendType" SG_ 207 VFC_Obj15B_TTIPC_StdDev 9;
BA_ "GenSigSendType" SG_ 207 VFC_Obj15B_TTIPC 9;
BA_ "GenSigSendType" SG_ 207 VFC_Obj15B_AngLongitude 9;
BA_ "GenSigStartValue" SG_ 207 VFC_Obj15B_AngLongitude 500;
BA_ "GenSigSendType" SG_ 207 VFC_Obj15B_CRC 9;
BA_ "GenSigSendType" SG_ 207 VFC_Obj15B_AliveCtr 9;
BA_ "GenSigSendType" SG_ 207 VFC_Obj15B_BlockCtr 9;
BA_ "GenSigSendType" SG_ 207 VFC_Obj15B_ScaleChange 9;
BA_ "GenSigSendType" SG_ 207 VFC_Obj15B_ScaleChngStdDev 9;
BA_ "GenSigSendType" SG_ 207 VFC_Obj15B_LineEdgeRightEgo 9;
BA_ "GenSigSendType" SG_ 207 VFC_Obj15B_LineEdgeLeftEgo 9;
BA_ "GenSigSendType" SG_ 207 VFC_Obj15B_CompletelyInImg 9;
BA_ "GenSigSendType" SG_ 207 VFC_Obj15B_DirIndicator 9;
BA_ "GenSigSendType" SG_ 207 VFC_Obj15B_LineEdgeAngle 9;
BA_ "GenSigStartValue" SG_ 207 VFC_Obj15B_LineEdgeAngle 4000;
BA_ "GenSigSendType" SG_ 207 VFC_Obj15B_BrakeLight 9;
BA_ "GenSigSendType" SG_ 207 VFC_Obj15B_MeasSource 9;
BA_ "GenSigSendType" SG_ 207 VFC_Obj15B_Reliab 9;
BA_ "GenSigSendType" SG_ 208 VFC_Obj16A_CRC 9;
BA_ "GenSigSendType" SG_ 208 VFC_Obj16A_AliveCtr 9;
BA_ "GenSigSendType" SG_ 208 VFC_Obj16A_BlockCtr 9;
BA_ "GenSigSendType" SG_ 208 VFC_Obj16A_ProtOrderIndex 9;
BA_ "GenSigSendType" SG_ 208 VFC_Obj16A_Ax 9;
BA_ "GenSigStartValue" SG_ 208 VFC_Obj16A_Ax 160;
BA_ "GenSigSendType" SG_ 208 VFC_Obj16A_Vx 9;
BA_ "GenSigStartValue" SG_ 208 VFC_Obj16A_Vx 1540;
BA_ "GenSigSendType" SG_ 208 VFC_Obj16A_Dx 9;
BA_ "GenSigSendType" SG_ 208 VFC_Obj16A_Dy 9;
BA_ "GenSigStartValue" SG_ 208 VFC_Obj16A_Dy 8000;
BA_ "GenSigSendType" SG_ 208 VFC_Obj16A_Vy 9;
BA_ "GenSigStartValue" SG_ 208 VFC_Obj16A_Vy 500;
BA_ "GenSigSendType" SG_ 208 VFC_Obj16A_Ay 9;
BA_ "GenSigStartValue" SG_ 208 VFC_Obj16A_Ay 120;
BA_ "GenSigSendType" SG_ 208 VFC_Obj16A_DyStdDev 9;
BA_ "GenSigSendType" SG_ 208 VFC_Obj16A_DxStdDev 9;
BA_ "GenSigSendType" SG_ 208 VFC_Obj16A_VxStdDev 9;
BA_ "GenSigSendType" SG_ 208 VFC_Obj16A_ExistProb 9;
BA_ "GenSigSendType" SG_ 208 VFC_Obj16A_VyStdDev 9;
BA_ "GenSigSendType" SG_ 208 VFC_Obj16A_TypeProb 9;
BA_ "GenSigSendType" SG_ 208 VFC_Obj16A_AxStdDev 9;
BA_ "GenSigSendType" SG_ 208 VFC_Obj16A_AyStdDev 9;
BA_ "GenSigSendType" SG_ 208 VFC_Obj16A_PhiLeft 9;
BA_ "GenSigStartValue" SG_ 208 VFC_Obj16A_PhiLeft 4000;
BA_ "GenSigSendType" SG_ 208 VFC_Obj16A_ClassifiedView 9;
BA_ "GenSigSendType" SG_ 208 VFC_Obj16A_Length 9;
BA_ "GenSigSendType" SG_ 208 VFC_Obj16A_WidthStdDev 9;
BA_ "GenSigSendType" SG_ 208 VFC_Obj16A_Height 9;
BA_ "GenSigSendType" SG_ 208 VFC_Obj16A_HeightStdDev 9;
BA_ "GenSigSendType" SG_ 208 VFC_Obj16A_PhiLeftStdDev 9;
BA_ "GenSigSendType" SG_ 208 VFC_Obj16A_HeadingStdDev 9;
BA_ "GenSigSendType" SG_ 208 VFC_Obj16A_Measured 9;
BA_ "GenSigSendType" SG_ 208 VFC_Obj16A_Heading 9;
BA_ "GenSigStartValue" SG_ 208 VFC_Obj16A_Heading 157;
BA_ "GenSigSendType" SG_ 208 VFC_Obj16A_LengthStdDev 9;
BA_ "GenSigSendType" SG_ 208 VFC_Obj16A_PhiMid 9;
BA_ "GenSigStartValue" SG_ 208 VFC_Obj16A_PhiMid 4000;
BA_ "GenSigSendType" SG_ 208 VFC_Obj16A_Width 9;
BA_ "GenSigSendType" SG_ 208 VFC_Obj16A_PhiMidStdDev 9;
BA_ "GenSigSendType" SG_ 208 VFC_Obj16A_PhiRight 9;
BA_ "GenSigStartValue" SG_ 208 VFC_Obj16A_PhiRight 4000;
BA_ "GenSigSendType" SG_ 208 VFC_Obj16A_VisibleView 9;
BA_ "GenSigSendType" SG_ 208 VFC_Obj16A_PhiRightStdDev 9;
BA_ "GenSigSendType" SG_ 208 VFC_Obj16A_PhiLeftVel 9;
BA_ "GenSigStartValue" SG_ 208 VFC_Obj16A_PhiLeftVel 4000;
BA_ "GenSigSendType" SG_ 208 VFC_Obj16A_PhiRightVel 9;
BA_ "GenSigStartValue" SG_ 208 VFC_Obj16A_PhiRightVel 4000;
BA_ "GenSigSendType" SG_ 208 VFC_Obj16A_PhiRightVelStdDev 9;
BA_ "GenSigSendType" SG_ 208 VFC_Obj16A_PhiLeftVelStdDev 9;
BA_ "GenSigSendType" SG_ 208 VFC_Obj16A_PhiTop 9;
BA_ "GenSigStartValue" SG_ 208 VFC_Obj16A_PhiTop 1600;
BA_ "GenSigSendType" SG_ 208 VFC_Obj16A_PhiBottom 9;
BA_ "GenSigStartValue" SG_ 208 VFC_Obj16A_PhiBottom 1600;
BA_ "GenSigSendType" SG_ 208 VFC_Obj16A_PhiTopStdDev 9;
BA_ "GenSigSendType" SG_ 208 VFC_Obj16A_HeadOrientation 9;
BA_ "GenSigSendType" SG_ 208 VFC_Obj16A_Type 9;
BA_ "GenSigSendType" SG_ 208 VFC_Obj16A_PhiBottomStdDev 9;
BA_ "GenSigSendType" SG_ 208 VFC_Obj16A_NormVx 9;
BA_ "GenSigStartValue" SG_ 208 VFC_Obj16A_NormVx 40000;
BA_ "GenSigSendType" SG_ 208 VFC_Obj16A_NormAx 9;
BA_ "GenSigStartValue" SG_ 208 VFC_Obj16A_NormAx 5000;
BA_ "GenSigSendType" SG_ 208 VFC_Obj16A_NormAxStdDev 9;
BA_ "GenSigSendType" SG_ 208 VFC_Obj16A_ProbMovingLat 9;
BA_ "GenSigSendType" SG_ 208 VFC_Obj16A_ID 9;
BA_ "GenSigSendType" SG_ 208 VFC_Obj16A_NormVxStdDev 9;
BA_ "GenSigSendType" SG_ 208 VFC_Obj16A_ProbMovingLong 9;
BA_ "GenSigSendType" SG_ 209 VFC_Obj16B_TTIPC_StdDev 9;
BA_ "GenSigSendType" SG_ 209 VFC_Obj16B_TTIPC 9;
BA_ "GenSigSendType" SG_ 209 VFC_Obj16B_AngLongitude 9;
BA_ "GenSigStartValue" SG_ 209 VFC_Obj16B_AngLongitude 500;
BA_ "GenSigSendType" SG_ 209 VFC_Obj16B_CRC 9;
BA_ "GenSigSendType" SG_ 209 VFC_Obj16B_AliveCtr 9;
BA_ "GenSigSendType" SG_ 209 VFC_Obj16B_BlockCtr 9;
BA_ "GenSigSendType" SG_ 209 VFC_Obj16B_ScaleChange 9;
BA_ "GenSigSendType" SG_ 209 VFC_Obj16B_ScaleChngStdDev 9;
BA_ "GenSigSendType" SG_ 209 VFC_Obj16B_LineEdgeRightEgo 9;
BA_ "GenSigSendType" SG_ 209 VFC_Obj16B_LineEdgeLeftEgo 9;
BA_ "GenSigSendType" SG_ 209 VFC_Obj16B_CompletelyInImg 9;
BA_ "GenSigSendType" SG_ 209 VFC_Obj16B_DirIndicator 9;
BA_ "GenSigSendType" SG_ 209 VFC_Obj16B_LineEdgeAngle 9;
BA_ "GenSigStartValue" SG_ 209 VFC_Obj16B_LineEdgeAngle 4000;
BA_ "GenSigSendType" SG_ 209 VFC_Obj16B_BrakeLight 9;
BA_ "GenSigSendType" SG_ 209 VFC_Obj16B_MeasSource 9;
BA_ "GenSigSendType" SG_ 209 VFC_Obj16B_Reliab 9;
BA_ "GenSigSendType" SG_ 210 VFC_Obj17A_CRC 9;
BA_ "GenSigSendType" SG_ 210 VFC_Obj17A_AliveCtr 9;
BA_ "GenSigSendType" SG_ 210 VFC_Obj17A_BlockCtr 9;
BA_ "GenSigSendType" SG_ 210 VFC_Obj17A_ProtOrderIndex 9;
BA_ "GenSigSendType" SG_ 210 VFC_Obj17A_Ax 9;
BA_ "GenSigStartValue" SG_ 210 VFC_Obj17A_Ax 160;
BA_ "GenSigSendType" SG_ 210 VFC_Obj17A_Vx 9;
BA_ "GenSigStartValue" SG_ 210 VFC_Obj17A_Vx 1540;
BA_ "GenSigSendType" SG_ 210 VFC_Obj17A_Dx 9;
BA_ "GenSigSendType" SG_ 210 VFC_Obj17A_Dy 9;
BA_ "GenSigStartValue" SG_ 210 VFC_Obj17A_Dy 8000;
BA_ "GenSigSendType" SG_ 210 VFC_Obj17A_Vy 9;
BA_ "GenSigStartValue" SG_ 210 VFC_Obj17A_Vy 500;
BA_ "GenSigSendType" SG_ 210 VFC_Obj17A_Ay 9;
BA_ "GenSigStartValue" SG_ 210 VFC_Obj17A_Ay 120;
BA_ "GenSigSendType" SG_ 210 VFC_Obj17A_DyStdDev 9;
BA_ "GenSigSendType" SG_ 210 VFC_Obj17A_DxStdDev 9;
BA_ "GenSigSendType" SG_ 210 VFC_Obj17A_VxStdDev 9;
BA_ "GenSigSendType" SG_ 210 VFC_Obj17A_ExistProb 9;
BA_ "GenSigSendType" SG_ 210 VFC_Obj17A_VyStdDev 9;
BA_ "GenSigSendType" SG_ 210 VFC_Obj17A_TypeProb 9;
BA_ "GenSigSendType" SG_ 210 VFC_Obj17A_AxStdDev 9;
BA_ "GenSigSendType" SG_ 210 VFC_Obj17A_AyStdDev 9;
BA_ "GenSigSendType" SG_ 210 VFC_Obj17A_PhiLeft 9;
BA_ "GenSigStartValue" SG_ 210 VFC_Obj17A_PhiLeft 4000;
BA_ "GenSigSendType" SG_ 210 VFC_Obj17A_ClassifiedView 9;
BA_ "GenSigSendType" SG_ 210 VFC_Obj17A_Length 9;
BA_ "GenSigSendType" SG_ 210 VFC_Obj17A_WidthStdDev 9;
BA_ "GenSigSendType" SG_ 210 VFC_Obj17A_Height 9;
BA_ "GenSigSendType" SG_ 210 VFC_Obj17A_HeightStdDev 9;
BA_ "GenSigSendType" SG_ 210 VFC_Obj17A_PhiLeftStdDev 9;
BA_ "GenSigSendType" SG_ 210 VFC_Obj17A_HeadingStdDev 9;
BA_ "GenSigSendType" SG_ 210 VFC_Obj17A_Measured 9;
BA_ "GenSigSendType" SG_ 210 VFC_Obj17A_Heading 9;
BA_ "GenSigStartValue" SG_ 210 VFC_Obj17A_Heading 157;
BA_ "GenSigSendType" SG_ 210 VFC_Obj17A_LengthStdDev 9;
BA_ "GenSigSendType" SG_ 210 VFC_Obj17A_PhiMid 9;
BA_ "GenSigStartValue" SG_ 210 VFC_Obj17A_PhiMid 4000;
BA_ "GenSigSendType" SG_ 210 VFC_Obj17A_Width 9;
BA_ "GenSigSendType" SG_ 210 VFC_Obj17A_PhiMidStdDev 9;
BA_ "GenSigSendType" SG_ 210 VFC_Obj17A_PhiRight 9;
BA_ "GenSigStartValue" SG_ 210 VFC_Obj17A_PhiRight 4000;
BA_ "GenSigSendType" SG_ 210 VFC_Obj17A_VisibleView 9;
BA_ "GenSigSendType" SG_ 210 VFC_Obj17A_PhiRightStdDev 9;
BA_ "GenSigSendType" SG_ 210 VFC_Obj17A_PhiLeftVel 9;
BA_ "GenSigStartValue" SG_ 210 VFC_Obj17A_PhiLeftVel 4000;
BA_ "GenSigSendType" SG_ 210 VFC_Obj17A_PhiRightVel 9;
BA_ "GenSigStartValue" SG_ 210 VFC_Obj17A_PhiRightVel 4000;
BA_ "GenSigSendType" SG_ 210 VFC_Obj17A_PhiRightVelStdDev 9;
BA_ "GenSigSendType" SG_ 210 VFC_Obj17A_PhiLeftVelStdDev 9;
BA_ "GenSigSendType" SG_ 210 VFC_Obj17A_PhiTop 9;
BA_ "GenSigStartValue" SG_ 210 VFC_Obj17A_PhiTop 1600;
BA_ "GenSigSendType" SG_ 210 VFC_Obj17A_PhiBottom 9;
BA_ "GenSigStartValue" SG_ 210 VFC_Obj17A_PhiBottom 1600;
BA_ "GenSigSendType" SG_ 210 VFC_Obj17A_PhiTopStdDev 9;
BA_ "GenSigSendType" SG_ 210 VFC_Obj17A_HeadOrientation 9;
BA_ "GenSigSendType" SG_ 210 VFC_Obj17A_Type 9;
BA_ "GenSigSendType" SG_ 210 VFC_Obj17A_PhiBottomStdDev 9;
BA_ "GenSigSendType" SG_ 210 VFC_Obj17A_NormVx 9;
BA_ "GenSigStartValue" SG_ 210 VFC_Obj17A_NormVx 40000;
BA_ "GenSigSendType" SG_ 210 VFC_Obj17A_NormAx 9;
BA_ "GenSigStartValue" SG_ 210 VFC_Obj17A_NormAx 5000;
BA_ "GenSigSendType" SG_ 210 VFC_Obj17A_NormAxStdDev 9;
BA_ "GenSigSendType" SG_ 210 VFC_Obj17A_ProbMovingLat 9;
BA_ "GenSigSendType" SG_ 210 VFC_Obj17A_ID 9;
BA_ "GenSigSendType" SG_ 210 VFC_Obj17A_NormVxStdDev 9;
BA_ "GenSigSendType" SG_ 210 VFC_Obj17A_ProbMovingLong 9;
BA_ "GenSigSendType" SG_ 211 VFC_Obj17B_TTIPC_StdDev 9;
BA_ "GenSigSendType" SG_ 211 VFC_Obj17B_TTIPC 9;
BA_ "GenSigSendType" SG_ 211 VFC_Obj17B_AngLongitude 9;
BA_ "GenSigStartValue" SG_ 211 VFC_Obj17B_AngLongitude 500;
BA_ "GenSigSendType" SG_ 211 VFC_Obj17B_CRC 9;
BA_ "GenSigSendType" SG_ 211 VFC_Obj17B_AliveCtr 9;
BA_ "GenSigSendType" SG_ 211 VFC_Obj17B_BlockCtr 9;
BA_ "GenSigSendType" SG_ 211 VFC_Obj17B_ScaleChange 9;
BA_ "GenSigSendType" SG_ 211 VFC_Obj17B_ScaleChngStdDev 9;
BA_ "GenSigSendType" SG_ 211 VFC_Obj17B_LineEdgeRightEgo 9;
BA_ "GenSigSendType" SG_ 211 VFC_Obj17B_LineEdgeLeftEgo 9;
BA_ "GenSigSendType" SG_ 211 VFC_Obj17B_CompletelyInImg 9;
BA_ "GenSigSendType" SG_ 211 VFC_Obj17B_DirIndicator 9;
BA_ "GenSigSendType" SG_ 211 VFC_Obj17B_LineEdgeAngle 9;
BA_ "GenSigStartValue" SG_ 211 VFC_Obj17B_LineEdgeAngle 4000;
BA_ "GenSigSendType" SG_ 211 VFC_Obj17B_BrakeLight 9;
BA_ "GenSigSendType" SG_ 211 VFC_Obj17B_MeasSource 9;
BA_ "GenSigSendType" SG_ 211 VFC_Obj17B_Reliab 9;
BA_ "GenSigSendType" SG_ 212 VFC_Obj18A_CRC 9;
BA_ "GenSigSendType" SG_ 212 VFC_Obj18A_AliveCtr 9;
BA_ "GenSigSendType" SG_ 212 VFC_Obj18A_BlockCtr 9;
BA_ "GenSigSendType" SG_ 212 VFC_Obj18A_ProtOrderIndex 9;
BA_ "GenSigSendType" SG_ 212 VFC_Obj18A_Ax 9;
BA_ "GenSigStartValue" SG_ 212 VFC_Obj18A_Ax 160;
BA_ "GenSigSendType" SG_ 212 VFC_Obj18A_Vx 9;
BA_ "GenSigStartValue" SG_ 212 VFC_Obj18A_Vx 1540;
BA_ "GenSigSendType" SG_ 212 VFC_Obj18A_Dx 9;
BA_ "GenSigSendType" SG_ 212 VFC_Obj18A_Dy 9;
BA_ "GenSigStartValue" SG_ 212 VFC_Obj18A_Dy 8000;
BA_ "GenSigSendType" SG_ 212 VFC_Obj18A_Vy 9;
BA_ "GenSigStartValue" SG_ 212 VFC_Obj18A_Vy 500;
BA_ "GenSigSendType" SG_ 212 VFC_Obj18A_Ay 9;
BA_ "GenSigStartValue" SG_ 212 VFC_Obj18A_Ay 120;
BA_ "GenSigSendType" SG_ 212 VFC_Obj18A_DyStdDev 9;
BA_ "GenSigSendType" SG_ 212 VFC_Obj18A_DxStdDev 9;
BA_ "GenSigSendType" SG_ 212 VFC_Obj18A_VxStdDev 9;
BA_ "GenSigSendType" SG_ 212 VFC_Obj18A_ExistProb 9;
BA_ "GenSigSendType" SG_ 212 VFC_Obj18A_VyStdDev 9;
BA_ "GenSigSendType" SG_ 212 VFC_Obj18A_TypeProb 9;
BA_ "GenSigSendType" SG_ 212 VFC_Obj18A_AxStdDev 9;
BA_ "GenSigSendType" SG_ 212 VFC_Obj18A_AyStdDev 9;
BA_ "GenSigSendType" SG_ 212 VFC_Obj18A_PhiLeft 9;
BA_ "GenSigStartValue" SG_ 212 VFC_Obj18A_PhiLeft 4000;
BA_ "GenSigSendType" SG_ 212 VFC_Obj18A_ClassifiedView 9;
BA_ "GenSigSendType" SG_ 212 VFC_Obj18A_Length 9;
BA_ "GenSigSendType" SG_ 212 VFC_Obj18A_WidthStdDev 9;
BA_ "GenSigSendType" SG_ 212 VFC_Obj18A_Height 9;
BA_ "GenSigSendType" SG_ 212 VFC_Obj18A_HeightStdDev 9;
BA_ "GenSigSendType" SG_ 212 VFC_Obj18A_PhiLeftStdDev 9;
BA_ "GenSigSendType" SG_ 212 VFC_Obj18A_HeadingStdDev 9;
BA_ "GenSigSendType" SG_ 212 VFC_Obj18A_Measured 9;
BA_ "GenSigSendType" SG_ 212 VFC_Obj18A_Heading 9;
BA_ "GenSigStartValue" SG_ 212 VFC_Obj18A_Heading 157;
BA_ "GenSigSendType" SG_ 212 VFC_Obj18A_LengthStdDev 9;
BA_ "GenSigSendType" SG_ 212 VFC_Obj18A_PhiMid 9;
BA_ "GenSigStartValue" SG_ 212 VFC_Obj18A_PhiMid 4000;
BA_ "GenSigSendType" SG_ 212 VFC_Obj18A_Width 9;
BA_ "GenSigSendType" SG_ 212 VFC_Obj18A_PhiMidStdDev 9;
BA_ "GenSigSendType" SG_ 212 VFC_Obj18A_PhiRight 9;
BA_ "GenSigStartValue" SG_ 212 VFC_Obj18A_PhiRight 4000;
BA_ "GenSigSendType" SG_ 212 VFC_Obj18A_VisibleView 9;
BA_ "GenSigSendType" SG_ 212 VFC_Obj18A_PhiRightStdDev 9;
BA_ "GenSigSendType" SG_ 212 VFC_Obj18A_PhiLeftVel 9;
BA_ "GenSigStartValue" SG_ 212 VFC_Obj18A_PhiLeftVel 4000;
BA_ "GenSigSendType" SG_ 212 VFC_Obj18A_PhiRightVel 9;
BA_ "GenSigStartValue" SG_ 212 VFC_Obj18A_PhiRightVel 4000;
BA_ "GenSigSendType" SG_ 212 VFC_Obj18A_PhiRightVelStdDev 9;
BA_ "GenSigSendType" SG_ 212 VFC_Obj18A_PhiLeftVelStdDev 9;
BA_ "GenSigSendType" SG_ 212 VFC_Obj18A_PhiTop 9;
BA_ "GenSigStartValue" SG_ 212 VFC_Obj18A_PhiTop 1600;
BA_ "GenSigSendType" SG_ 212 VFC_Obj18A_PhiBottom 9;
BA_ "GenSigStartValue" SG_ 212 VFC_Obj18A_PhiBottom 1600;
BA_ "GenSigSendType" SG_ 212 VFC_Obj18A_PhiTopStdDev 9;
BA_ "GenSigSendType" SG_ 212 VFC_Obj18A_HeadOrientation 9;
BA_ "GenSigSendType" SG_ 212 VFC_Obj18A_Type 9;
BA_ "GenSigSendType" SG_ 212 VFC_Obj18A_PhiBottomStdDev 9;
BA_ "GenSigSendType" SG_ 212 VFC_Obj18A_NormVx 9;
BA_ "GenSigStartValue" SG_ 212 VFC_Obj18A_NormVx 40000;
BA_ "GenSigSendType" SG_ 212 VFC_Obj18A_NormAx 9;
BA_ "GenSigStartValue" SG_ 212 VFC_Obj18A_NormAx 5000;
BA_ "GenSigSendType" SG_ 212 VFC_Obj18A_NormAxStdDev 9;
BA_ "GenSigSendType" SG_ 212 VFC_Obj18A_ProbMovingLat 9;
BA_ "GenSigSendType" SG_ 212 VFC_Obj18A_ID 9;
BA_ "GenSigSendType" SG_ 212 VFC_Obj18A_NormVxStdDev 9;
BA_ "GenSigSendType" SG_ 212 VFC_Obj18A_ProbMovingLong 9;
BA_ "GenSigSendType" SG_ 213 VFC_Obj18B_TTIPC_StdDev 9;
BA_ "GenSigSendType" SG_ 213 VFC_Obj18B_TTIPC 9;
BA_ "GenSigSendType" SG_ 213 VFC_Obj18B_AngLongitude 9;
BA_ "GenSigStartValue" SG_ 213 VFC_Obj18B_AngLongitude 500;
BA_ "GenSigSendType" SG_ 213 VFC_Obj18B_CRC 9;
BA_ "GenSigSendType" SG_ 213 VFC_Obj18B_AliveCtr 9;
BA_ "GenSigSendType" SG_ 213 VFC_Obj18B_BlockCtr 9;
BA_ "GenSigSendType" SG_ 213 VFC_Obj18B_ScaleChange 9;
BA_ "GenSigSendType" SG_ 213 VFC_Obj18B_ScaleChngStdDev 9;
BA_ "GenSigSendType" SG_ 213 VFC_Obj18B_LineEdgeRightEgo 9;
BA_ "GenSigSendType" SG_ 213 VFC_Obj18B_LineEdgeLeftEgo 9;
BA_ "GenSigSendType" SG_ 213 VFC_Obj18B_CompletelyInImg 9;
BA_ "GenSigSendType" SG_ 213 VFC_Obj18B_DirIndicator 9;
BA_ "GenSigSendType" SG_ 213 VFC_Obj18B_LineEdgeAngle 9;
BA_ "GenSigStartValue" SG_ 213 VFC_Obj18B_LineEdgeAngle 4000;
BA_ "GenSigSendType" SG_ 213 VFC_Obj18B_BrakeLight 9;
BA_ "GenSigSendType" SG_ 213 VFC_Obj18B_MeasSource 9;
BA_ "GenSigSendType" SG_ 213 VFC_Obj18B_Reliab 9;
BA_ "GenSigSendType" SG_ 214 VFC_Obj19A_CRC 9;
BA_ "GenSigSendType" SG_ 214 VFC_Obj19A_AliveCtr 9;
BA_ "GenSigSendType" SG_ 214 VFC_Obj19A_BlockCtr 9;
BA_ "GenSigSendType" SG_ 214 VFC_Obj19A_ProtOrderIndex 9;
BA_ "GenSigSendType" SG_ 214 VFC_Obj19A_Ax 9;
BA_ "GenSigStartValue" SG_ 214 VFC_Obj19A_Ax 160;
BA_ "GenSigSendType" SG_ 214 VFC_Obj19A_Vx 9;
BA_ "GenSigStartValue" SG_ 214 VFC_Obj19A_Vx 1540;
BA_ "GenSigSendType" SG_ 214 VFC_Obj19A_Dx 9;
BA_ "GenSigSendType" SG_ 214 VFC_Obj19A_Dy 9;
BA_ "GenSigStartValue" SG_ 214 VFC_Obj19A_Dy 8000;
BA_ "GenSigSendType" SG_ 214 VFC_Obj19A_Vy 9;
BA_ "GenSigStartValue" SG_ 214 VFC_Obj19A_Vy 500;
BA_ "GenSigSendType" SG_ 214 VFC_Obj19A_Ay 9;
BA_ "GenSigStartValue" SG_ 214 VFC_Obj19A_Ay 120;
BA_ "GenSigSendType" SG_ 214 VFC_Obj19A_DyStdDev 9;
BA_ "GenSigSendType" SG_ 214 VFC_Obj19A_DxStdDev 9;
BA_ "GenSigSendType" SG_ 214 VFC_Obj19A_VxStdDev 9;
BA_ "GenSigSendType" SG_ 214 VFC_Obj19A_ExistProb 9;
BA_ "GenSigSendType" SG_ 214 VFC_Obj19A_VyStdDev 9;
BA_ "GenSigSendType" SG_ 214 VFC_Obj19A_TypeProb 9;
BA_ "GenSigSendType" SG_ 214 VFC_Obj19A_AxStdDev 9;
BA_ "GenSigSendType" SG_ 214 VFC_Obj19A_AyStdDev 9;
BA_ "GenSigSendType" SG_ 214 VFC_Obj19A_PhiLeft 9;
BA_ "GenSigStartValue" SG_ 214 VFC_Obj19A_PhiLeft 4000;
BA_ "GenSigSendType" SG_ 214 VFC_Obj19A_ClassifiedView 9;
BA_ "GenSigSendType" SG_ 214 VFC_Obj19A_Length 9;
BA_ "GenSigSendType" SG_ 214 VFC_Obj19A_WidthStdDev 9;
BA_ "GenSigSendType" SG_ 214 VFC_Obj19A_Height 9;
BA_ "GenSigSendType" SG_ 214 VFC_Obj19A_HeightStdDev 9;
BA_ "GenSigSendType" SG_ 214 VFC_Obj19A_PhiLeftStdDev 9;
BA_ "GenSigSendType" SG_ 214 VFC_Obj19A_HeadingStdDev 9;
BA_ "GenSigSendType" SG_ 214 VFC_Obj19A_Measured 9;
BA_ "GenSigSendType" SG_ 214 VFC_Obj19A_Heading 9;
BA_ "GenSigStartValue" SG_ 214 VFC_Obj19A_Heading 157;
BA_ "GenSigSendType" SG_ 214 VFC_Obj19A_LengthStdDev 9;
BA_ "GenSigSendType" SG_ 214 VFC_Obj19A_PhiMid 9;
BA_ "GenSigStartValue" SG_ 214 VFC_Obj19A_PhiMid 4000;
BA_ "GenSigSendType" SG_ 214 VFC_Obj19A_Width 9;
BA_ "GenSigSendType" SG_ 214 VFC_Obj19A_PhiMidStdDev 9;
BA_ "GenSigSendType" SG_ 214 VFC_Obj19A_PhiRight 9;
BA_ "GenSigStartValue" SG_ 214 VFC_Obj19A_PhiRight 4000;
BA_ "GenSigSendType" SG_ 214 VFC_Obj19A_VisibleView 9;
BA_ "GenSigSendType" SG_ 214 VFC_Obj19A_PhiRightStdDev 9;
BA_ "GenSigSendType" SG_ 214 VFC_Obj19A_PhiLeftVel 9;
BA_ "GenSigStartValue" SG_ 214 VFC_Obj19A_PhiLeftVel 4000;
BA_ "GenSigSendType" SG_ 214 VFC_Obj19A_PhiRightVel 9;
BA_ "GenSigStartValue" SG_ 214 VFC_Obj19A_PhiRightVel 4000;
BA_ "GenSigSendType" SG_ 214 VFC_Obj19A_PhiRightVelStdDev 9;
BA_ "GenSigSendType" SG_ 214 VFC_Obj19A_PhiLeftVelStdDev 9;
BA_ "GenSigSendType" SG_ 214 VFC_Obj19A_PhiTop 9;
BA_ "GenSigStartValue" SG_ 214 VFC_Obj19A_PhiTop 1600;
BA_ "GenSigSendType" SG_ 214 VFC_Obj19A_PhiBottom 9;
BA_ "GenSigStartValue" SG_ 214 VFC_Obj19A_PhiBottom 1600;
BA_ "GenSigSendType" SG_ 214 VFC_Obj19A_PhiTopStdDev 9;
BA_ "GenSigSendType" SG_ 214 VFC_Obj19A_HeadOrientation 9;
BA_ "GenSigSendType" SG_ 214 VFC_Obj19A_Type 9;
BA_ "GenSigSendType" SG_ 214 VFC_Obj19A_PhiBottomStdDev 9;
BA_ "GenSigSendType" SG_ 214 VFC_Obj19A_NormVx 9;
BA_ "GenSigStartValue" SG_ 214 VFC_Obj19A_NormVx 40000;
BA_ "GenSigSendType" SG_ 214 VFC_Obj19A_NormAx 9;
BA_ "GenSigStartValue" SG_ 214 VFC_Obj19A_NormAx 5000;
BA_ "GenSigSendType" SG_ 214 VFC_Obj19A_NormAxStdDev 9;
BA_ "GenSigSendType" SG_ 214 VFC_Obj19A_ProbMovingLat 9;
BA_ "GenSigSendType" SG_ 214 VFC_Obj19A_ID 9;
BA_ "GenSigSendType" SG_ 214 VFC_Obj19A_NormVxStdDev 9;
BA_ "GenSigSendType" SG_ 214 VFC_Obj19A_ProbMovingLong 9;
BA_ "GenSigSendType" SG_ 215 VFC_Obj19B_TTIPC_StdDev 9;
BA_ "GenSigSendType" SG_ 215 VFC_Obj19B_TTIPC 9;
BA_ "GenSigSendType" SG_ 215 VFC_Obj19B_AngLongitude 9;
BA_ "GenSigStartValue" SG_ 215 VFC_Obj19B_AngLongitude 500;
BA_ "GenSigSendType" SG_ 215 VFC_Obj19B_CRC 9;
BA_ "GenSigSendType" SG_ 215 VFC_Obj19B_AliveCtr 9;
BA_ "GenSigSendType" SG_ 215 VFC_Obj19B_BlockCtr 9;
BA_ "GenSigSendType" SG_ 215 VFC_Obj19B_ScaleChange 9;
BA_ "GenSigSendType" SG_ 215 VFC_Obj19B_ScaleChngStdDev 9;
BA_ "GenSigSendType" SG_ 215 VFC_Obj19B_LineEdgeRightEgo 9;
BA_ "GenSigSendType" SG_ 215 VFC_Obj19B_LineEdgeLeftEgo 9;
BA_ "GenSigSendType" SG_ 215 VFC_Obj19B_CompletelyInImg 9;
BA_ "GenSigSendType" SG_ 215 VFC_Obj19B_DirIndicator 9;
BA_ "GenSigSendType" SG_ 215 VFC_Obj19B_LineEdgeAngle 9;
BA_ "GenSigStartValue" SG_ 215 VFC_Obj19B_LineEdgeAngle 4000;
BA_ "GenSigSendType" SG_ 215 VFC_Obj19B_BrakeLight 9;
BA_ "GenSigSendType" SG_ 215 VFC_Obj19B_MeasSource 9;
BA_ "GenSigSendType" SG_ 215 VFC_Obj19B_Reliab 9;
BA_ "GenSigSendType" SG_ 128 VFC_LineHdr_AUTOSARTStamp 9;
BA_ "GenSigSendType" SG_ 128 VFC_LineHdr_FrameNo 9;
BA_ "GenSigSendType" SG_ 128 VFC_LineHdr_CRC 9;
BA_ "GenSigSendType" SG_ 128 VFC_LineHdr_AliveCtr 9;
BA_ "GenSigSendType" SG_ 128 VFC_LineHdr_BlockCounter 9;
BA_ "GenSigSendType" SG_ 128 VFC_LineHdr_Report 9;
BA_ "GenSigSendType" SG_ 128 VFC_LineHdr_LineCount 9;
BA_ "GenSigSendType" SG_ 128 VFC_LineHdr_PEPSIRuntime 9;
BA_ "GenSigSendType" SG_ 128 VFC_LineHdr_TimeStamp 9;
BA_ "GenSigSendType" SG_ 128 VFC_LineHdr_Blindness 9;
BA_ "GenSigSendType" SG_ 128 VFC_LineHdr_State 9;
BA_ "GenSigSendType" SG_ 129 VFC_Line01_CRC 9;
BA_ "GenSigSendType" SG_ 129 VFC_Line01_AliveCtr 9;
BA_ "GenSigSendType" SG_ 129 VFC_Line01_BlockCounter 9;
BA_ "GenSigSendType" SG_ 129 VFC_Line01_ProtOrderIndex 9;
BA_ "GenSigSendType" SG_ 129 VFC_Line01_LineID 9;
BA_ "GenSigSendType" SG_ 129 VFC_Line01_LaneRelation 9;
BA_ "GenSigSendType" SG_ 129 VFC_Line01_ExistProb 9;
BA_ "GenSigSendType" SG_ 129 VFC_Line01_DxStart 9;
BA_ "GenSigSendType" SG_ 129 VFC_Line01_ColorClass 9;
BA_ "GenSigSendType" SG_ 129 VFC_Line01_DxEnd 9;
BA_ "GenSigSendType" SG_ 129 VFC_Line01_HeadingAngle 9;
BA_ "GenSigStartValue" SG_ 129 VFC_Line01_HeadingAngle 3277;
BA_ "GenSigSendType" SG_ 129 VFC_Line01_Dy 9;
BA_ "GenSigStartValue" SG_ 129 VFC_Line01_Dy 2048;
BA_ "GenSigSendType" SG_ 129 VFC_Line01_CurvChange 9;
BA_ "GenSigStartValue" SG_ 129 VFC_Line01_CurvChange 2048;
BA_ "GenSigSendType" SG_ 129 VFC_Line01_Curv 9;
BA_ "GenSigStartValue" SG_ 129 VFC_Line01_Curv 4096;
BA_ "GenSigSendType" SG_ 129 VFC_Line01_MeasureType 9;
BA_ "GenSigSendType" SG_ 129 VFC_Line01_LineWidth 9;
BA_ "GenSigSendType" SG_ 129 VFC_Line01_CourseDeviation 9;
BA_ "GenSigSendType" SG_ 129 VFC_Line01_Type 9;
BA_ "GenSigSendType" SG_ 129 VFC_Line01_DyStdDevDxEnd 9;
BA_ "GenSigSendType" SG_ 129 VFC_Line01_HypoConfidence 9;
BA_ "GenSigSendType" SG_ 129 VFC_Line01_prevID 9;
BA_ "GenSigSendType" SG_ 129 VFC_Line01_nextID 9;
BA_ "GenSigSendType" SG_ 129 VFC_Line01_DyStdDevDxStart 9;
BA_ "GenSigSendType" SG_ 129 VFC_Line01_TypeProb 9;
BA_ "GenSigSendType" SG_ 129 VFC_Line01_DyStdDevDxMid 9;
BA_ "GenSigSendType" SG_ 130 VFC_Line02_CRC 9;
BA_ "GenSigSendType" SG_ 130 VFC_Line02_AliveCtr 9;
BA_ "GenSigSendType" SG_ 130 VFC_Line02_BlockCounter 9;
BA_ "GenSigSendType" SG_ 130 VFC_Line02_ProtOrderIndex 9;
BA_ "GenSigSendType" SG_ 130 VFC_Line02_LineID 9;
BA_ "GenSigSendType" SG_ 130 VFC_Line02_LaneRelation 9;
BA_ "GenSigSendType" SG_ 130 VFC_Line02_ExistProb 9;
BA_ "GenSigSendType" SG_ 130 VFC_Line02_DxStart 9;
BA_ "GenSigSendType" SG_ 130 VFC_Line02_ColorClass 9;
BA_ "GenSigSendType" SG_ 130 VFC_Line02_DxEnd 9;
BA_ "GenSigSendType" SG_ 130 VFC_Line02_HeadingAngle 9;
BA_ "GenSigStartValue" SG_ 130 VFC_Line02_HeadingAngle 3277;
BA_ "GenSigSendType" SG_ 130 VFC_Line02_Dy 9;
BA_ "GenSigStartValue" SG_ 130 VFC_Line02_Dy 2048;
BA_ "GenSigSendType" SG_ 130 VFC_Line02_CurvChange 9;
BA_ "GenSigStartValue" SG_ 130 VFC_Line02_CurvChange 2048;
BA_ "GenSigSendType" SG_ 130 VFC_Line02_Curv 9;
BA_ "GenSigStartValue" SG_ 130 VFC_Line02_Curv 4096;
BA_ "GenSigSendType" SG_ 130 VFC_Line02_MeasureType 9;
BA_ "GenSigSendType" SG_ 130 VFC_Line02_LineWidth 9;
BA_ "GenSigSendType" SG_ 130 VFC_Line02_CourseDeviation 9;
BA_ "GenSigSendType" SG_ 130 VFC_Line02_Type 9;
BA_ "GenSigSendType" SG_ 130 VFC_Line02_DyStdDevDxEnd 9;
BA_ "GenSigSendType" SG_ 130 VFC_Line02_HypoConfidence 9;
BA_ "GenSigSendType" SG_ 130 VFC_Line02_prevID 9;
BA_ "GenSigSendType" SG_ 130 VFC_Line02_nextID 9;
BA_ "GenSigSendType" SG_ 130 VFC_Line02_DyStdDevDxStart 9;
BA_ "GenSigSendType" SG_ 130 VFC_Line02_TypeProb 9;
BA_ "GenSigSendType" SG_ 130 VFC_Line02_DyStdDevDxMid 9;
BA_ "GenSigSendType" SG_ 131 VFC_Line03_CRC 9;
BA_ "GenSigSendType" SG_ 131 VFC_Line03_AliveCtr 9;
BA_ "GenSigSendType" SG_ 131 VFC_Line03_BlockCounter 9;
BA_ "GenSigSendType" SG_ 131 VFC_Line03_ProtOrderIndex 9;
BA_ "GenSigSendType" SG_ 131 VFC_Line03_LineID 9;
BA_ "GenSigSendType" SG_ 131 VFC_Line03_LaneRelation 9;
BA_ "GenSigSendType" SG_ 131 VFC_Line03_ExistProb 9;
BA_ "GenSigSendType" SG_ 131 VFC_Line03_DxStart 9;
BA_ "GenSigSendType" SG_ 131 VFC_Line03_ColorClass 9;
BA_ "GenSigSendType" SG_ 131 VFC_Line03_DxEnd 9;
BA_ "GenSigSendType" SG_ 131 VFC_Line03_HeadingAngle 9;
BA_ "GenSigStartValue" SG_ 131 VFC_Line03_HeadingAngle 3277;
BA_ "GenSigSendType" SG_ 131 VFC_Line03_Dy 9;
BA_ "GenSigStartValue" SG_ 131 VFC_Line03_Dy 2048;
BA_ "GenSigSendType" SG_ 131 VFC_Line03_CurvChange 9;
BA_ "GenSigStartValue" SG_ 131 VFC_Line03_CurvChange 2048;
BA_ "GenSigSendType" SG_ 131 VFC_Line03_Curv 9;
BA_ "GenSigStartValue" SG_ 131 VFC_Line03_Curv 4096;
BA_ "GenSigSendType" SG_ 131 VFC_Line03_MeasureType 9;
BA_ "GenSigSendType" SG_ 131 VFC_Line03_LineWidth 9;
BA_ "GenSigSendType" SG_ 131 VFC_Line03_CourseDeviation 9;
BA_ "GenSigSendType" SG_ 131 VFC_Line03_Type 9;
BA_ "GenSigSendType" SG_ 131 VFC_Line03_DyStdDevDxEnd 9;
BA_ "GenSigSendType" SG_ 131 VFC_Line03_HypoConfidence 9;
BA_ "GenSigSendType" SG_ 131 VFC_Line03_prevID 9;
BA_ "GenSigSendType" SG_ 131 VFC_Line03_nextID 9;
BA_ "GenSigSendType" SG_ 131 VFC_Line03_DyStdDevDxStart 9;
BA_ "GenSigSendType" SG_ 131 VFC_Line03_TypeProb 9;
BA_ "GenSigSendType" SG_ 131 VFC_Line03_DyStdDevDxMid 9;
BA_ "GenSigSendType" SG_ 132 VFC_Line04_CRC 9;
BA_ "GenSigSendType" SG_ 132 VFC_Line04_AliveCtr 9;
BA_ "GenSigSendType" SG_ 132 VFC_Line04_BlockCounter 9;
BA_ "GenSigSendType" SG_ 132 VFC_Line04_ProtOrderIndex 9;
BA_ "GenSigSendType" SG_ 132 VFC_Line04_LineID 9;
BA_ "GenSigSendType" SG_ 132 VFC_Line04_LaneRelation 9;
BA_ "GenSigSendType" SG_ 132 VFC_Line04_ExistProb 9;
BA_ "GenSigSendType" SG_ 132 VFC_Line04_DxStart 9;
BA_ "GenSigSendType" SG_ 132 VFC_Line04_ColorClass 9;
BA_ "GenSigSendType" SG_ 132 VFC_Line04_DxEnd 9;
BA_ "GenSigSendType" SG_ 132 VFC_Line04_HeadingAngle 9;
BA_ "GenSigStartValue" SG_ 132 VFC_Line04_HeadingAngle 3277;
BA_ "GenSigSendType" SG_ 132 VFC_Line04_Dy 9;
BA_ "GenSigStartValue" SG_ 132 VFC_Line04_Dy 2048;
BA_ "GenSigSendType" SG_ 132 VFC_Line04_CurvChange 9;
BA_ "GenSigStartValue" SG_ 132 VFC_Line04_CurvChange 2048;
BA_ "GenSigSendType" SG_ 132 VFC_Line04_Curv 9;
BA_ "GenSigStartValue" SG_ 132 VFC_Line04_Curv 4096;
BA_ "GenSigSendType" SG_ 132 VFC_Line04_MeasureType 9;
BA_ "GenSigSendType" SG_ 132 VFC_Line04_LineWidth 9;
BA_ "GenSigSendType" SG_ 132 VFC_Line04_CourseDeviation 9;
BA_ "GenSigSendType" SG_ 132 VFC_Line04_Type 9;
BA_ "GenSigSendType" SG_ 132 VFC_Line04_DyStdDevDxEnd 9;
BA_ "GenSigSendType" SG_ 132 VFC_Line04_HypoConfidence 9;
BA_ "GenSigSendType" SG_ 132 VFC_Line04_prevID 9;
BA_ "GenSigSendType" SG_ 132 VFC_Line04_nextID 9;
BA_ "GenSigSendType" SG_ 132 VFC_Line04_DyStdDevDxStart 9;
BA_ "GenSigSendType" SG_ 132 VFC_Line04_TypeProb 9;
BA_ "GenSigSendType" SG_ 132 VFC_Line04_DyStdDevDxMid 9;
BA_ "GenSigSendType" SG_ 133 VFC_Line05_CRC 9;
BA_ "GenSigSendType" SG_ 133 VFC_Line05_AliveCtr 9;
BA_ "GenSigSendType" SG_ 133 VFC_Line05_BlockCounter 9;
BA_ "GenSigSendType" SG_ 133 VFC_Line05_ProtOrderIndex 9;
BA_ "GenSigSendType" SG_ 133 VFC_Line05_LineID 9;
BA_ "GenSigSendType" SG_ 133 VFC_Line05_LaneRelation 9;
BA_ "GenSigSendType" SG_ 133 VFC_Line05_ExistProb 9;
BA_ "GenSigSendType" SG_ 133 VFC_Line05_DxStart 9;
BA_ "GenSigSendType" SG_ 133 VFC_Line05_ColorClass 9;
BA_ "GenSigSendType" SG_ 133 VFC_Line05_DxEnd 9;
BA_ "GenSigSendType" SG_ 133 VFC_Line05_HeadingAngle 9;
BA_ "GenSigStartValue" SG_ 133 VFC_Line05_HeadingAngle 3277;
BA_ "GenSigSendType" SG_ 133 VFC_Line05_Dy 9;
BA_ "GenSigStartValue" SG_ 133 VFC_Line05_Dy 2048;
BA_ "GenSigSendType" SG_ 133 VFC_Line05_CurvChange 9;
BA_ "GenSigStartValue" SG_ 133 VFC_Line05_CurvChange 2048;
BA_ "GenSigSendType" SG_ 133 VFC_Line05_Curv 9;
BA_ "GenSigStartValue" SG_ 133 VFC_Line05_Curv 4096;
BA_ "GenSigSendType" SG_ 133 VFC_Line05_MeasureType 9;
BA_ "GenSigSendType" SG_ 133 VFC_Line05_LineWidth 9;
BA_ "GenSigSendType" SG_ 133 VFC_Line05_CourseDeviation 9;
BA_ "GenSigSendType" SG_ 133 VFC_Line05_Type 9;
BA_ "GenSigSendType" SG_ 133 VFC_Line05_DyStdDevDxEnd 9;
BA_ "GenSigSendType" SG_ 133 VFC_Line05_HypoConfidence 9;
BA_ "GenSigSendType" SG_ 133 VFC_Line05_prevID 9;
BA_ "GenSigSendType" SG_ 133 VFC_Line05_nextID 9;
BA_ "GenSigSendType" SG_ 133 VFC_Line05_DyStdDevDxStart 9;
BA_ "GenSigSendType" SG_ 133 VFC_Line05_TypeProb 9;
BA_ "GenSigSendType" SG_ 133 VFC_Line05_DyStdDevDxMid 9;
BA_ "GenSigSendType" SG_ 134 VFC_Line06_CRC 9;
BA_ "GenSigSendType" SG_ 134 VFC_Line06_AliveCtr 9;
BA_ "GenSigSendType" SG_ 134 VFC_Line06_BlockCounter 9;
BA_ "GenSigSendType" SG_ 134 VFC_Line06_ProtOrderIndex 9;
BA_ "GenSigSendType" SG_ 134 VFC_Line06_LineID 9;
BA_ "GenSigSendType" SG_ 134 VFC_Line06_LaneRelation 9;
BA_ "GenSigSendType" SG_ 134 VFC_Line06_ExistProb 9;
BA_ "GenSigSendType" SG_ 134 VFC_Line06_DxStart 9;
BA_ "GenSigSendType" SG_ 134 VFC_Line06_ColorClass 9;
BA_ "GenSigSendType" SG_ 134 VFC_Line06_DxEnd 9;
BA_ "GenSigSendType" SG_ 134 VFC_Line06_HeadingAngle 9;
BA_ "GenSigStartValue" SG_ 134 VFC_Line06_HeadingAngle 3277;
BA_ "GenSigSendType" SG_ 134 VFC_Line06_Dy 9;
BA_ "GenSigStartValue" SG_ 134 VFC_Line06_Dy 2048;
BA_ "GenSigSendType" SG_ 134 VFC_Line06_CurvChange 9;
BA_ "GenSigStartValue" SG_ 134 VFC_Line06_CurvChange 2048;
BA_ "GenSigSendType" SG_ 134 VFC_Line06_Curv 9;
BA_ "GenSigStartValue" SG_ 134 VFC_Line06_Curv 4096;
BA_ "GenSigSendType" SG_ 134 VFC_Line06_MeasureType 9;
BA_ "GenSigSendType" SG_ 134 VFC_Line06_LineWidth 9;
BA_ "GenSigSendType" SG_ 134 VFC_Line06_CourseDeviation 9;
BA_ "GenSigSendType" SG_ 134 VFC_Line06_Type 9;
BA_ "GenSigSendType" SG_ 134 VFC_Line06_DyStdDevDxEnd 9;
BA_ "GenSigSendType" SG_ 134 VFC_Line06_HypoConfidence 9;
BA_ "GenSigSendType" SG_ 134 VFC_Line06_prevID 9;
BA_ "GenSigSendType" SG_ 134 VFC_Line06_nextID 9;
BA_ "GenSigSendType" SG_ 134 VFC_Line06_DyStdDevDxStart 9;
BA_ "GenSigSendType" SG_ 134 VFC_Line06_TypeProb 9;
BA_ "GenSigSendType" SG_ 134 VFC_Line06_DyStdDevDxMid 9;
BA_ "GenSigSendType" SG_ 135 VFC_Line07_CRC 9;
BA_ "GenSigSendType" SG_ 135 VFC_Line07_AliveCtr 9;
BA_ "GenSigSendType" SG_ 135 VFC_Line07_BlockCounter 9;
BA_ "GenSigSendType" SG_ 135 VFC_Line07_ProtOrderIndex 9;
BA_ "GenSigSendType" SG_ 135 VFC_Line07_LineID 9;
BA_ "GenSigSendType" SG_ 135 VFC_Line07_LaneRelation 9;
BA_ "GenSigSendType" SG_ 135 VFC_Line07_ExistProb 9;
BA_ "GenSigSendType" SG_ 135 VFC_Line07_DxStart 9;
BA_ "GenSigSendType" SG_ 135 VFC_Line07_ColorClass 9;
BA_ "GenSigSendType" SG_ 135 VFC_Line07_DxEnd 9;
BA_ "GenSigSendType" SG_ 135 VFC_Line07_HeadingAngle 9;
BA_ "GenSigStartValue" SG_ 135 VFC_Line07_HeadingAngle 3277;
BA_ "GenSigSendType" SG_ 135 VFC_Line07_Dy 9;
BA_ "GenSigStartValue" SG_ 135 VFC_Line07_Dy 2048;
BA_ "GenSigSendType" SG_ 135 VFC_Line07_CurvChange 9;
BA_ "GenSigStartValue" SG_ 135 VFC_Line07_CurvChange 2048;
BA_ "GenSigSendType" SG_ 135 VFC_Line07_Curv 9;
BA_ "GenSigStartValue" SG_ 135 VFC_Line07_Curv 4096;
BA_ "GenSigSendType" SG_ 135 VFC_Line07_MeasureType 9;
BA_ "GenSigSendType" SG_ 135 VFC_Line07_LineWidth 9;
BA_ "GenSigSendType" SG_ 135 VFC_Line07_CourseDeviation 9;
BA_ "GenSigSendType" SG_ 135 VFC_Line07_Type 9;
BA_ "GenSigSendType" SG_ 135 VFC_Line07_DyStdDevDxEnd 9;
BA_ "GenSigSendType" SG_ 135 VFC_Line07_HypoConfidence 9;
BA_ "GenSigSendType" SG_ 135 VFC_Line07_prevID 9;
BA_ "GenSigSendType" SG_ 135 VFC_Line07_nextID 9;
BA_ "GenSigSendType" SG_ 135 VFC_Line07_DyStdDevDxStart 9;
BA_ "GenSigSendType" SG_ 135 VFC_Line07_TypeProb 9;
BA_ "GenSigSendType" SG_ 135 VFC_Line07_DyStdDevDxMid 9;
BA_ "GenSigSendType" SG_ 136 VFC_Line08_CRC 9;
BA_ "GenSigSendType" SG_ 136 VFC_Line08_AliveCtr 9;
BA_ "GenSigSendType" SG_ 136 VFC_Line08_BlockCounter 9;
BA_ "GenSigSendType" SG_ 136 VFC_Line08_ProtOrderIndex 9;
BA_ "GenSigSendType" SG_ 136 VFC_Line08_LineID 9;
BA_ "GenSigSendType" SG_ 136 VFC_Line08_LaneRelation 9;
BA_ "GenSigSendType" SG_ 136 VFC_Line08_ExistProb 9;
BA_ "GenSigSendType" SG_ 136 VFC_Line08_DxStart 9;
BA_ "GenSigSendType" SG_ 136 VFC_Line08_ColorClass 9;
BA_ "GenSigSendType" SG_ 136 VFC_Line08_DxEnd 9;
BA_ "GenSigSendType" SG_ 136 VFC_Line08_HeadingAngle 9;
BA_ "GenSigStartValue" SG_ 136 VFC_Line08_HeadingAngle 3277;
BA_ "GenSigSendType" SG_ 136 VFC_Line08_Dy 9;
BA_ "GenSigStartValue" SG_ 136 VFC_Line08_Dy 2048;
BA_ "GenSigSendType" SG_ 136 VFC_Line08_CurvChange 9;
BA_ "GenSigStartValue" SG_ 136 VFC_Line08_CurvChange 2048;
BA_ "GenSigSendType" SG_ 136 VFC_Line08_Curv 9;
BA_ "GenSigStartValue" SG_ 136 VFC_Line08_Curv 4096;
BA_ "GenSigSendType" SG_ 136 VFC_Line08_MeasureType 9;
BA_ "GenSigSendType" SG_ 136 VFC_Line08_LineWidth 9;
BA_ "GenSigSendType" SG_ 136 VFC_Line08_CourseDeviation 9;
BA_ "GenSigSendType" SG_ 136 VFC_Line08_Type 9;
BA_ "GenSigSendType" SG_ 136 VFC_Line08_DyStdDevDxEnd 9;
BA_ "GenSigSendType" SG_ 136 VFC_Line08_HypoConfidence 9;
BA_ "GenSigSendType" SG_ 136 VFC_Line08_prevID 9;
BA_ "GenSigSendType" SG_ 136 VFC_Line08_nextID 9;
BA_ "GenSigSendType" SG_ 136 VFC_Line08_DyStdDevDxStart 9;
BA_ "GenSigSendType" SG_ 136 VFC_Line08_TypeProb 9;
BA_ "GenSigSendType" SG_ 136 VFC_Line08_DyStdDevDxMid 9;
VAL_ 206 VFC_Obj15A_ClassifiedView 0 "Unknown" 1 "Front" 2 "Rear" 3 "Left" 4 "Right" ;
VAL_ 206 VFC_Obj15A_Measured 0 "Invalid" 1 "Predicted" 2 "Measured" 3 "Reserved" ;
VAL_ 206 VFC_Obj15A_VisibleView 0 "UNKNOWN" 1 "CLASSIC" 2 "SIDE" 3 "CLASSIC_SIDE" 4 "SIDE_CLASSIC" ;
VAL_ 206 VFC_Obj15A_HeadOrientation 0 "N/A" 1 "Head front" 2 "Head left front" 3 "Head left" 4 "Head left back" 5 "Head back" 6 "Head right back" 7 "Head right" 8 "Head right front" 15 "Unknown" ;
VAL_ 206 VFC_Obj15A_Type 0 "No type" 1 "Car" 2 "Truck" 3 "Motorcycle" 4 "Pedestrian" 5 "Cyclist" 6 "Animal" ;
VAL_ 207 VFC_Obj15B_LineEdgeRightEgo 0 "Right" 1 "Not Right" ;
VAL_ 207 VFC_Obj15B_LineEdgeLeftEgo 0 "Left" 1 "Not Left" ;
VAL_ 207 VFC_Obj15B_CompletelyInImg 0 "completely measured" 1 "not completely measured" ;
VAL_ 207 VFC_Obj15B_DirIndicator 0 "No direction indicator" 1 "Left indicator" 2 "Right indicator" 3 "Warning Lights" 4 "Unknown" ;
VAL_ 207 VFC_Obj15B_BrakeLight 0 "No light detected" 1 "One light detected" 2 "Two lights detected" 3 "Three lights detected" 4 "Unknown" ;
VAL_ 207 VFC_Obj15B_MeasSource 1 "MOD" 2 "PDET" 4 "OFT" 8 "OLS" 16 "Reserved" ;
VAL_ 207 VFC_Obj15B_Reliab 1 "Classifier Path" 2 "Flow Path" 4 "Disparity Path" 8 "Semantic Segmentation Path" 16 "Flow Stixel Path" 32 "Reserved" ;
VAL_ 208 VFC_Obj16A_ClassifiedView 0 "Unknown" 1 "Front" 2 "Rear" 3 "Left" 4 "Right" ;
VAL_ 208 VFC_Obj16A_Measured 0 "Invalid" 1 "Predicted" 2 "Measured" 3 "Reserved" ;
VAL_ 208 VFC_Obj16A_VisibleView 0 "UNKNOWN" 1 "CLASSIC" 2 "SIDE" 3 "CLASSIC_SIDE" 4 "SIDE_CLASSIC" ;
VAL_ 208 VFC_Obj16A_HeadOrientation 0 "N/A" 1 "Head front" 2 "Head left front" 3 "Head left" 4 "Head left back" 5 "Head back" 6 "Head right back" 7 "Head right" 8 "Head right front" 15 "Unknown" ;
VAL_ 208 VFC_Obj16A_Type 0 "No type" 1 "Car" 2 "Truck" 3 "Motorcycle" 4 "Pedestrian" 5 "Cyclist" 6 "Animal" ;
VAL_ 209 VFC_Obj16B_LineEdgeRightEgo 0 "Right" 1 "Not Right" ;
VAL_ 209 VFC_Obj16B_LineEdgeLeftEgo 0 "Left" 1 "Not Left" ;
VAL_ 209 VFC_Obj16B_CompletelyInImg 0 "completely measured" 1 "not completely measured" ;
VAL_ 209 VFC_Obj16B_DirIndicator 0 "No direction indicator" 1 "Left indicator" 2 "Right indicator" 3 "Warning Lights" 4 "Unknown" ;
VAL_ 209 VFC_Obj16B_BrakeLight 0 "No light detected" 1 "One light detected" 2 "Two lights detected" 3 "Three lights detected" 4 "Unknown" ;
VAL_ 209 VFC_Obj16B_MeasSource 1 "MOD" 2 "PDET" 4 "OFT" 8 "OLS" 16 "Reserved" ;
VAL_ 209 VFC_Obj16B_Reliab 1 "Classifier Path" 2 "Flow Path" 4 "Disparity Path" 8 "Semantic Segmentation Path" 16 "Flow Stixel Path" 32 "Reserved" ;
VAL_ 210 VFC_Obj17A_ClassifiedView 0 "Unknown" 1 "Front" 2 "Rear" 3 "Left" 4 "Right" ;
VAL_ 210 VFC_Obj17A_Measured 0 "Invalid" 1 "Predicted" 2 "Measured" 3 "Reserved" ;
VAL_ 210 VFC_Obj17A_VisibleView 0 "UNKNOWN" 1 "CLASSIC" 2 "SIDE" 3 "CLASSIC_SIDE" 4 "SIDE_CLASSIC" ;
VAL_ 210 VFC_Obj17A_HeadOrientation 0 "N/A" 1 "Head front" 2 "Head left front" 3 "Head left" 4 "Head left back" 5 "Head back" 6 "Head right back" 7 "Head right" 8 "Head right front" 15 "Unknown" ;
VAL_ 210 VFC_Obj17A_Type 0 "No type" 1 "Car" 2 "Truck" 3 "Motorcycle" 4 "Pedestrian" 5 "Cyclist" 6 "Animal" ;
VAL_ 211 VFC_Obj17B_LineEdgeRightEgo 0 "Right" 1 "Not Right" ;
VAL_ 211 VFC_Obj17B_LineEdgeLeftEgo 0 "Left" 1 "Not Left" ;
VAL_ 211 VFC_Obj17B_CompletelyInImg 0 "completely measured" 1 "not completely measured" ;
VAL_ 211 VFC_Obj17B_DirIndicator 0 "No direction indicator" 1 "Left indicator" 2 "Right indicator" 3 "Warning Lights" 4 "Unknown" ;
VAL_ 211 VFC_Obj17B_BrakeLight 0 "No light detected" 1 "One light detected" 2 "Two lights detected" 3 "Three lights detected" 4 "Unknown" ;
VAL_ 211 VFC_Obj17B_MeasSource 1 "MOD" 2 "PDET" 4 "OFT" 8 "OLS" 16 "Reserved" ;
VAL_ 211 VFC_Obj17B_Reliab 1 "Classifier Path" 2 "Flow Path" 4 "Disparity Path" 8 "Semantic Segmentation Path" 16 "Flow Stixel Path" 32 "Reserved" ;
VAL_ 212 VFC_Obj18A_ClassifiedView 0 "Unknown" 1 "Front" 2 "Rear" 3 "Left" 4 "Right" ;
VAL_ 212 VFC_Obj18A_Measured 0 "Invalid" 1 "Predicted" 2 "Measured" 3 "Reserved" ;
VAL_ 212 VFC_Obj18A_VisibleView 0 "UNKNOWN" 1 "CLASSIC" 2 "SIDE" 3 "CLASSIC_SIDE" 4 "SIDE_CLASSIC" ;
VAL_ 212 VFC_Obj18A_HeadOrientation 0 "N/A" 1 "Head front" 2 "Head left front" 3 "Head left" 4 "Head left back" 5 "Head back" 6 "Head right back" 7 "Head right" 8 "Head right front" 15 "Unknown" ;
VAL_ 212 VFC_Obj18A_Type 0 "No type" 1 "Car" 2 "Truck" 3 "Motorcycle" 4 "Pedestrian" 5 "Cyclist" 6 "Animal" ;
VAL_ 213 VFC_Obj18B_LineEdgeRightEgo 0 "Right" 1 "Not Right" ;
VAL_ 213 VFC_Obj18B_LineEdgeLeftEgo 0 "Left" 1 "Not Left" ;
VAL_ 213 VFC_Obj18B_CompletelyInImg 0 "completely measured" 1 "not completely measured" ;
VAL_ 213 VFC_Obj18B_DirIndicator 0 "No direction indicator" 1 "Left indicator" 2 "Right indicator" 3 "Warning Lights" 4 "Unknown" ;
VAL_ 213 VFC_Obj18B_BrakeLight 0 "No light detected" 1 "One light detected" 2 "Two lights detected" 3 "Three lights detected" 4 "Unknown" ;
VAL_ 213 VFC_Obj18B_MeasSource 1 "MOD" 2 "PDET" 4 "OFT" 8 "OLS" 16 "Reserved" ;
VAL_ 213 VFC_Obj18B_Reliab 1 "Classifier Path" 2 "Flow Path" 4 "Disparity Path" 8 "Semantic Segmentation Path" 16 "Flow Stixel Path" 32 "Reserved" ;
VAL_ 214 VFC_Obj19A_ClassifiedView 0 "Unknown" 1 "Front" 2 "Rear" 3 "Left" 4 "Right" ;
VAL_ 214 VFC_Obj19A_Measured 0 "Invalid" 1 "Predicted" 2 "Measured" 3 "Reserved" ;
VAL_ 214 VFC_Obj19A_VisibleView 0 "UNKNOWN" 1 "CLASSIC" 2 "SIDE" 3 "CLASSIC_SIDE" 4 "SIDE_CLASSIC" ;
VAL_ 214 VFC_Obj19A_HeadOrientation 0 "N/A" 1 "Head front" 2 "Head left front" 3 "Head left" 4 "Head left back" 5 "Head back" 6 "Head right back" 7 "Head right" 8 "Head right front" 15 "Unknown" ;
VAL_ 214 VFC_Obj19A_Type 0 "No type" 1 "Car" 2 "Truck" 3 "Motorcycle" 4 "Pedestrian" 5 "Cyclist" 6 "Animal" ;
VAL_ 215 VFC_Obj19B_LineEdgeRightEgo 0 "Right" 1 "Not Right" ;
VAL_ 215 VFC_Obj19B_LineEdgeLeftEgo 0 "Left" 1 "Not Left" ;
VAL_ 215 VFC_Obj19B_CompletelyInImg 0 "completely measured" 1 "not completely measured" ;
VAL_ 215 VFC_Obj19B_DirIndicator 0 "No direction indicator" 1 "Left indicator" 2 "Right indicator" 3 "Warning Lights" 4 "Unknown" ;
VAL_ 215 VFC_Obj19B_BrakeLight 0 "No light detected" 1 "One light detected" 2 "Two lights detected" 3 "Three lights detected" 4 "Unknown" ;
VAL_ 215 VFC_Obj19B_MeasSource 1 "MOD" 2 "PDET" 4 "OFT" 8 "OLS" 16 "Reserved" ;
VAL_ 215 VFC_Obj19B_Reliab 1 "Classifier Path" 2 "Flow Path" 4 "Disparity Path" 8 "Semantic Segmentation Path" 16 "Flow Stixel Path" 32 "Reserved" ;
VAL_ 128 VFC_LineHdr_Report 1 "INVALID_BET_INPUT" 2 "INVALID_MOPED_INPUT" 4 "INVALID_MOFU_INPUT" 8 "NO_LBSEGS" 16 "INVALID_YAW_RATE" 32 "INVALID_YAW_ANGLE" 64 "INVALID_VELOCITY" 128 "INVALID_TIMESTAMP" ;
VAL_ 128 VFC_LineHdr_State 0 "off" 1 "on" 2 "Reduced" 3 "HW_Error" 4 "SW_Error" 5 "FID_Active" 6 "Reserved6" 7 "Reserved7" ;
VAL_ 129 VFC_Line01_LaneRelation 0 "LEFT_EGO_LINE" 1 "RIGHT_EGO_LINE" 2 "LEFT_LEFT_LINE" 3 "RIGHT_RIGHT_LINE" 4 "ROAD_EDGE_LEFT" 5 "ROAD_EDGE_RIGHT" 6 "RAISED_LEFT" 7 "RAISED_RIGHT" ;
VAL_ 129 VFC_Line01_ColorClass 0 "COLOR_WHITE" 1 "COLOR_YELLOW" 2 "COLOR_RED" 3 "COLOR_BLUE" 7 "COLOR_UNKNOWN" ;
VAL_ 129 VFC_Line01_MeasureType 0 "MTYPE_MEASURED" 1 "MTYPE_VIRTUAL" 2 "MTYPE_INTERPOLATED" 3 "MTYPE_UNKNOWN" ;
VAL_ 129 VFC_Line01_Type 0 "TYPE_SOLID_LINE" 1 "TYPE_DASHED_LINE" 2 "TYPE_DOUBLE_DASHED_DASHED" 3 "TYPE_DOUBLE_DASHED_SOLID" 4 "TYPE_DOUBLE_SOLID_DASHED" 5 "TYPE_DOUBLE_SOLID_SOLID" 6 "TYPE_MULTIPLE" 7 "TYPE_MULTIPLE_WARNING" 8 "TYPE_CAR_POOL" 9 "TYPE_ASPHALT_JOINT" 10 "TYPE_BOTTS_DOTS" 11 "TYPE_ROAD_EDGE" 12 "TYPE_GUARDRAIL" 13 "TYPE_CURBSTONE" 14 "TYPE_WALL" 15 "TYPE_TRAFFIC_CONE" 16 "TYPE_DELINEATOR_POST" 17 "TYPE_PARKING_CAR" 18 "TYPE_UNKNOWN_RAISED" 19 "TYPE_UNKNOWN" ;
VAL_ 130 VFC_Line02_LaneRelation 0 "LEFT_EGO_LINE" 1 "RIGHT_EGO_LINE" 2 "LEFT_LEFT_LINE" 3 "RIGHT_RIGHT_LINE" 4 "ROAD_EDGE_LEFT" 5 "ROAD_EDGE_RIGHT" 6 "RAISED_LEFT" 7 "RAISED_RIGHT" ;
VAL_ 130 VFC_Line02_ColorClass 0 "COLOR_WHITE" 1 "COLOR_YELLOW" 2 "COLOR_RED" 3 "COLOR_BLUE" 7 "COLOR_UNKNOWN" ;
VAL_ 130 VFC_Line02_MeasureType 0 "MTYPE_MEASURED" 1 "MTYPE_VIRTUAL" 2 "MTYPE_INTERPOLATED" 3 "MTYPE_UNKNOWN" ;
VAL_ 130 VFC_Line02_Type 0 "TYPE_SOLID_LINE" 1 "TYPE_DASHED_LINE" 2 "TYPE_DOUBLE_DASHED_DASHED" 3 "TYPE_DOUBLE_DASHED_SOLID" 4 "TYPE_DOUBLE_SOLID_DASHED" 5 "TYPE_DOUBLE_SOLID_SOLID" 6 "TYPE_MULTIPLE" 7 "TYPE_MULTIPLE_WARNING" 8 "TYPE_CAR_POOL" 9 "TYPE_ASPHALT_JOINT" 10 "TYPE_BOTTS_DOTS" 11 "TYPE_ROAD_EDGE" 12 "TYPE_GUARDRAIL" 13 "TYPE_CURBSTONE" 14 "TYPE_WALL" 15 "TYPE_TRAFFIC_CONE" 16 "TYPE_DELINEATOR_POST" 17 "TYPE_PARKING_CAR" 18 "TYPE_UNKNOWN_RAISED" 19 "TYPE_UNKNOWN" ;
VAL_ 131 VFC_Line03_LaneRelation 0 "LEFT_EGO_LINE" 1 "RIGHT_EGO_LINE" 2 "LEFT_LEFT_LINE" 3 "RIGHT_RIGHT_LINE" 4 "ROAD_EDGE_LEFT" 5 "ROAD_EDGE_RIGHT" 6 "RAISED_LEFT" 7 "RAISED_RIGHT" ;
VAL_ 131 VFC_Line03_ColorClass 0 "COLOR_WHITE" 1 "COLOR_YELLOW" 2 "COLOR_RED" 3 "COLOR_BLUE" 7 "COLOR_UNKNOWN" ;
VAL_ 131 VFC_Line03_MeasureType 0 "MTYPE_MEASURED" 1 "MTYPE_VIRTUAL" 2 "MTYPE_INTERPOLATED" 3 "MTYPE_UNKNOWN" ;
VAL_ 131 VFC_Line03_Type 0 "TYPE_SOLID_LINE" 1 "TYPE_DASHED_LINE" 2 "TYPE_DOUBLE_DASHED_DASHED" 3 "TYPE_DOUBLE_DASHED_SOLID" 4 "TYPE_DOUBLE_SOLID_DASHED" 5 "TYPE_DOUBLE_SOLID_SOLID" 6 "TYPE_MULTIPLE" 7 "TYPE_MULTIPLE_WARNING" 8 "TYPE_CAR_POOL" 9 "TYPE_ASPHALT_JOINT" 10 "TYPE_BOTTS_DOTS" 11 "TYPE_ROAD_EDGE" 12 "TYPE_GUARDRAIL" 13 "TYPE_CURBSTONE" 14 "TYPE_WALL" 15 "TYPE_TRAFFIC_CONE" 16 "TYPE_DELINEATOR_POST" 17 "TYPE_PARKING_CAR" 18 "TYPE_UNKNOWN_RAISED" 19 "TYPE_UNKNOWN" ;
VAL_ 132 VFC_Line04_LaneRelation 0 "LEFT_EGO_LINE" 1 "RIGHT_EGO_LINE" 2 "LEFT_LEFT_LINE" 3 "RIGHT_RIGHT_LINE" 4 "ROAD_EDGE_LEFT" 5 "ROAD_EDGE_RIGHT" 6 "RAISED_LEFT" 7 "RAISED_RIGHT" ;
VAL_ 132 VFC_Line04_ColorClass 0 "COLOR_WHITE" 1 "COLOR_YELLOW" 2 "COLOR_RED" 3 "COLOR_BLUE" 7 "COLOR_UNKNOWN" ;
VAL_ 132 VFC_Line04_MeasureType 0 "MTYPE_MEASURED" 1 "MTYPE_VIRTUAL" 2 "MTYPE_INTERPOLATED" 3 "MTYPE_UNKNOWN" ;
VAL_ 132 VFC_Line04_Type 0 "TYPE_SOLID_LINE" 1 "TYPE_DASHED_LINE" 2 "TYPE_DOUBLE_DASHED_DASHED" 3 "TYPE_DOUBLE_DASHED_SOLID" 4 "TYPE_DOUBLE_SOLID_DASHED" 5 "TYPE_DOUBLE_SOLID_SOLID" 6 "TYPE_MULTIPLE" 7 "TYPE_MULTIPLE_WARNING" 8 "TYPE_CAR_POOL" 9 "TYPE_ASPHALT_JOINT" 10 "TYPE_BOTTS_DOTS" 11 "TYPE_ROAD_EDGE" 12 "TYPE_GUARDRAIL" 13 "TYPE_CURBSTONE" 14 "TYPE_WALL" 15 "TYPE_TRAFFIC_CONE" 16 "TYPE_DELINEATOR_POST" 17 "TYPE_PARKING_CAR" 18 "TYPE_UNKNOWN_RAISED" 19 "TYPE_UNKNOWN" ;
VAL_ 133 VFC_Line05_LaneRelation 0 "LEFT_EGO_LINE" 1 "RIGHT_EGO_LINE" 2 "LEFT_LEFT_LINE" 3 "RIGHT_RIGHT_LINE" 4 "ROAD_EDGE_LEFT" 5 "ROAD_EDGE_RIGHT" 6 "RAISED_LEFT" 7 "RAISED_RIGHT" ;
VAL_ 133 VFC_Line05_ColorClass 0 "COLOR_WHITE" 1 "COLOR_YELLOW" 2 "COLOR_RED" 3 "COLOR_BLUE" 7 "COLOR_UNKNOWN" ;
VAL_ 133 VFC_Line05_MeasureType 0 "MTYPE_MEASURED" 1 "MTYPE_VIRTUAL" 2 "MTYPE_INTERPOLATED" 3 "MTYPE_UNKNOWN" ;
VAL_ 133 VFC_Line05_Type 0 "TYPE_SOLID_LINE" 1 "TYPE_DASHED_LINE" 2 "TYPE_DOUBLE_DASHED_DASHED" 3 "TYPE_DOUBLE_DASHED_SOLID" 4 "TYPE_DOUBLE_SOLID_DASHED" 5 "TYPE_DOUBLE_SOLID_SOLID" 6 "TYPE_MULTIPLE" 7 "TYPE_MULTIPLE_WARNING" 8 "TYPE_CAR_POOL" 9 "TYPE_ASPHALT_JOINT" 10 "TYPE_BOTTS_DOTS" 11 "TYPE_ROAD_EDGE" 12 "TYPE_GUARDRAIL" 13 "TYPE_CURBSTONE" 14 "TYPE_WALL" 15 "TYPE_TRAFFIC_CONE" 16 "TYPE_DELINEATOR_POST" 17 "TYPE_PARKING_CAR" 18 "TYPE_UNKNOWN_RAISED" 19 "TYPE_UNKNOWN" ;
VAL_ 134 VFC_Line06_LaneRelation 0 "LEFT_EGO_LINE" 1 "RIGHT_EGO_LINE" 2 "LEFT_LEFT_LINE" 3 "RIGHT_RIGHT_LINE" 4 "ROAD_EDGE_LEFT" 5 "ROAD_EDGE_RIGHT" 6 "RAISED_LEFT" 7 "RAISED_RIGHT" ;
VAL_ 134 VFC_Line06_ColorClass 0 "COLOR_WHITE" 1 "COLOR_YELLOW" 2 "COLOR_RED" 3 "COLOR_BLUE" 7 "COLOR_UNKNOWN" ;
VAL_ 134 VFC_Line06_MeasureType 0 "MTYPE_MEASURED" 1 "MTYPE_VIRTUAL" 2 "MTYPE_INTERPOLATED" 3 "MTYPE_UNKNOWN" ;
VAL_ 134 VFC_Line06_Type 0 "TYPE_SOLID_LINE" 1 "TYPE_DASHED_LINE" 2 "TYPE_DOUBLE_DASHED_DASHED" 3 "TYPE_DOUBLE_DASHED_SOLID" 4 "TYPE_DOUBLE_SOLID_DASHED" 5 "TYPE_DOUBLE_SOLID_SOLID" 6 "TYPE_MULTIPLE" 7 "TYPE_MULTIPLE_WARNING" 8 "TYPE_CAR_POOL" 9 "TYPE_ASPHALT_JOINT" 10 "TYPE_BOTTS_DOTS" 11 "TYPE_ROAD_EDGE" 12 "TYPE_GUARDRAIL" 13 "TYPE_CURBSTONE" 14 "TYPE_WALL" 15 "TYPE_TRAFFIC_CONE" 16 "TYPE_DELINEATOR_POST" 17 "TYPE_PARKING_CAR" 18 "TYPE_UNKNOWN_RAISED" 19 "TYPE_UNKNOWN" ;
VAL_ 135 VFC_Line07_LaneRelation 0 "LEFT_EGO_LINE" 1 "RIGHT_EGO_LINE" 2 "LEFT_LEFT_LINE" 3 "RIGHT_RIGHT_LINE" 4 "ROAD_EDGE_LEFT" 5 "ROAD_EDGE_RIGHT" 6 "RAISED_LEFT" 7 "RAISED_RIGHT" ;
VAL_ 135 VFC_Line07_ColorClass 0 "COLOR_WHITE" 1 "COLOR_YELLOW" 2 "COLOR_RED" 3 "COLOR_BLUE" 7 "COLOR_UNKNOWN" ;
VAL_ 135 VFC_Line07_MeasureType 0 "MTYPE_MEASURED" 1 "MTYPE_VIRTUAL" 2 "MTYPE_INTERPOLATED" 3 "MTYPE_UNKNOWN" ;
VAL_ 135 VFC_Line07_Type 0 "TYPE_SOLID_LINE" 1 "TYPE_DASHED_LINE" 2 "TYPE_DOUBLE_DASHED_DASHED" 3 "TYPE_DOUBLE_DASHED_SOLID" 4 "TYPE_DOUBLE_SOLID_DASHED" 5 "TYPE_DOUBLE_SOLID_SOLID" 6 "TYPE_MULTIPLE" 7 "TYPE_MULTIPLE_WARNING" 8 "TYPE_CAR_POOL" 9 "TYPE_ASPHALT_JOINT" 10 "TYPE_BOTTS_DOTS" 11 "TYPE_ROAD_EDGE" 12 "TYPE_GUARDRAIL" 13 "TYPE_CURBSTONE" 14 "TYPE_WALL" 15 "TYPE_TRAFFIC_CONE" 16 "TYPE_DELINEATOR_POST" 17 "TYPE_PARKING_CAR" 18 "TYPE_UNKNOWN_RAISED" 19 "TYPE_UNKNOWN" ;
VAL_ 136 VFC_Line08_LaneRelation 0 "LEFT_EGO_LINE" 1 "RIGHT_EGO_LINE" 2 "LEFT_LEFT_LINE" 3 "RIGHT_RIGHT_LINE" 4 "ROAD_EDGE_LEFT" 5 "ROAD_EDGE_RIGHT" 6 "RAISED_LEFT" 7 "RAISED_RIGHT" ;
VAL_ 136 VFC_Line08_ColorClass 0 "COLOR_WHITE" 1 "COLOR_YELLOW" 2 "COLOR_RED" 3 "COLOR_BLUE" 7 "COLOR_UNKNOWN" ;
VAL_ 136 VFC_Line08_MeasureType 0 "MTYPE_MEASURED" 1 "MTYPE_VIRTUAL" 2 "MTYPE_INTERPOLATED" 3 "MTYPE_UNKNOWN" ;
VAL_ 136 VFC_Line08_Type 0 "TYPE_SOLID_LINE" 1 "TYPE_DASHED_LINE" 2 "TYPE_DOUBLE_DASHED_DASHED" 3 "TYPE_DOUBLE_DASHED_SOLID" 4 "TYPE_DOUBLE_SOLID_DASHED" 5 "TYPE_DOUBLE_SOLID_SOLID" 6 "TYPE_MULTIPLE" 7 "TYPE_MULTIPLE_WARNING" 8 "TYPE_CAR_POOL" 9 "TYPE_ASPHALT_JOINT" 10 "TYPE_BOTTS_DOTS" 11 "TYPE_ROAD_EDGE" 12 "TYPE_GUARDRAIL" 13 "TYPE_CURBSTONE" 14 "TYPE_WALL" 15 "TYPE_TRAFFIC_CONE" 16 "TYPE_DELINEATOR_POST" 17 "TYPE_PARKING_CAR" 18 "TYPE_UNKNOWN_RAISED" 19 "TYPE_UNKNOWN" ;
VAL_ 930 VFC_ADAS_ModSts_SLA 0 "Unknown" 1 "Off" 2 "Fusion mode" 3 "Vision mode" 4 "Navigation only mode" 5 "Defect" 6 "Reserved" 7 "Reserved" ;
VAL_ 930 VFC_ADAS_SpdLim_SLA 0 "No Display" 1 "SPL Cancelled" 2 "SPL 5" 3 "SPL 10" 4 "SPL 15" 5 "SPL 20" 6 "SPL 25" 7 "SPL 30" 8 "SPL 35" 9 "SPL 40" 10 "SPL 45" 11 "SPL 50" 12 "SPL 55" 13 "SPL 60" 14 "SPL 65" 15 "SPL 70" 16 "SPL 75" 17 "SPL 80" 18 "SPL 85" 19 "SPL 90" 20 "SPL 95" 21 "SPL 100" 22 "SPL 105" 23 "SPL 110" 24 "SPL 115" 25 "SPL 120" 26 "SPL 125" 27 "SPL 130" 28 "Reserved" 29 "0x1C(28)-FF(255): Reserved." 255 "0x1C(28)-FF(255): Reserved." ;
VAL_ 930 VFC_ADAS_SpdLimUnit_SLA 0 "Unknown" 1 "KPH" 2 "MPH" 3 "Reserved" ;
